VERSION "1.11.2"

NS_ :

BS_:

BU_: TCU BRK ESP MCU RDD GP TMS GW KPD1 RDE FNR ECU KPD2 ATSGO ACU IMU1 IMU2 IMU3 IMU4 IMU5 AGW PMI HDOQS EGOQS OBC EEC CBSW EJRH EJLH EPDLT EPDL2 EPDLR EPDLA TRBDZ ECU1 CLST LC510 EGDL JS SMB KPAC ACCU Audio TGU RDRR RDLH RDRH AVM CHMSL CTC SMK EVC MCU2 PHM MC3D AMBLMP RCTGU RDU PT3D XCU can1 can2

BO_ 2566866721 MCU_SIG3: 8 MCU
 SG_ DifActlTrgGrdt : 63|1@1+ (1,0) [0|1] "" Vector__XXX
 SG_ OprPrsntSt : 62|1@1+ (1,0) [0|1] "" Vector__XXX
 SG_ HydCutOffRls : 61|1@1+ (1,0) [0|1] "" Vector__XXX
 SG_ ChgErr : 60|1@1+ (1,0) [0|1] "" Vector__XXX
 SG_ ChgSt : 58|2@1+ (1,0) [0|3] "" Vector__XXX
 SG_ WrkTrv : 56|2@1+ (1,0) [0|3] "" Vector__XXX
 SG_ BatLw : 55|1@1+ (1,0) [0|1] "" Vector__XXX
 SG_ HydLck : 54|1@1+ (1,0) [0|1] "" Vector__XXX
 SG_ PopCmdHillDscntCtrl : 53|1@1+ (5,0) [0|1250] "" Vector__XXX
 SG_ HillDscntCtrlSt : 52|1@1+ (1,0) [0|1] "" Vector__XXX
 SG_ OprPrsnc : 51|1@1+ (1,0) [0|1] "" Vector__XXX
 SG_ BckDust : 50|1@1+ (1,0) [0|1] "" Vector__XXX
 SG_ BmsPrhtLmp : 48|2@1+ (1,0) [0|3] "" Vector__XXX
 SG_ DacSt : 45|3@1+ (1,0) [0|7] "" Vector__XXX
 SG_ EmcvFngrtpLvrErr : 44|1@1+ (1,0) [0|1] "" Vector__XXX
 SG_ PopCmdFnrNtrl : 42|2@1+ (1,0) [0|3] "" Vector__XXX
 SG_ IllminSt : 40|2@1+ (1,0) [0|3] "" Vector__XXX
 SG_ ChmslSt : 36|4@1+ (1,0) [0|15] "" Vector__XXX
 SG_ CdsFanRvsSt : 35|1@1+ (1,0) [0|1] "" Vector__XXX
 SG_ CacFanRvsSt : 34|1@1+ (1,0) [0|1] "" Vector__XXX
 SG_ CurMaxSpdMinor : 32|2@1+ (1,0) [0|3] "" Vector__XXX
 SG_ WhlTypeStrMd : 30|2@1+ (1,0) [0|3] "" Vector__XXX
 SG_ WrnGndSlop : 29|1@1+ (1,0) [0|1] "" Vector__XXX
 SG_ WrnOilTmpLw : 28|1@1+ (1,0) [0|1] "" Vector__XXX
 SG_ WghConfirmWarnMsg : 24|4@1+ (1,0) [0|15] "" Vector__XXX
 SG_ AttOpr : 23|1@1+ (1,0) [0|1] "" Vector__XXX
 SG_ QckCoolSt : 21|2@1+ (1,0) [0|3] "" Vector__XXX
 SG_ PopCmdBckAstTargetSet : 20|1@1+ (1,0) [0|1] "" Vector__XXX
 SG_ WrnLimpHome : 19|1@1+ (1,0) [0|1] "" Vector__XXX
 SG_ DozAstStopReq : 18|1@1+ (1,0) [0|1] "" Vector__XXX
 SG_ MchCond : 16|2@1+ (1,0) [0|3] "" Vector__XXX
 SG_ WrnRollOvr : 14|2@1+ (1,0) [0|3] "" Vector__XXX
 SG_ WrnArmPosOnDrv : 13|1@1+ (1,0) [0|1] "" Vector__XXX
 SG_ WrnThwStrShft : 12|1@1+ (1,0) [0|1] "" Vector__XXX
 SG_ WrnRamLck : 10|2@1+ (1,0) [0|3] "" Vector__XXX
 SG_ WrnHstOilFilt : 9|1@1+ (1,0) [0|1] "" Vector__XXX
 SG_ WrnGrBoxOvTmp : 8|1@1+ (1,0) [0|1] "" Vector__XXX
 SG_ VhcStTractionLv : 6|2@1+ (1,0) [0|3] "" Vector__XXX
 SG_ WhlLis : 4|2@1+ (1,0) [0|3] "" Vector__XXX
 SG_ WhlDzTrlHitch : 3|1@1+ (1,0) [0|1] "" Vector__XXX
 SG_ WhlSwgAlign : 2|1@1+ (1,0) [0|1] "" Vector__XXX
 SG_ WhlRamLckAuto : 0|2@1+ (1,0) [0|3] "" Vector__XXX

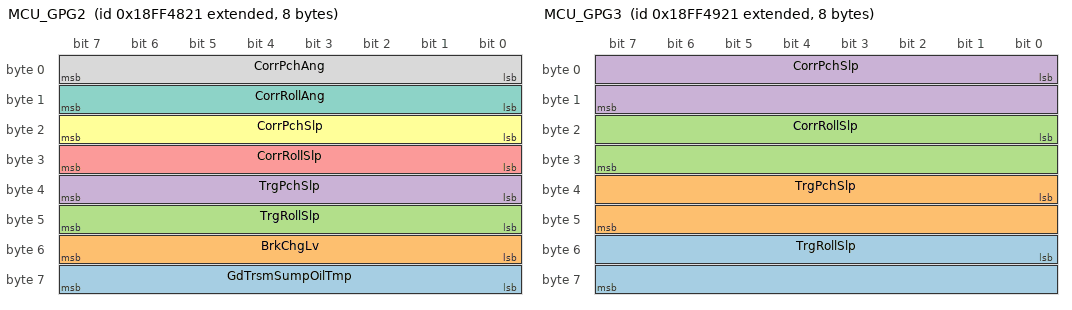
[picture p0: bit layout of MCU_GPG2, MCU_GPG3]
BO_ 2566866977 MCU_GPG2: 8 MCU
 SG_ GdTrsmSumpOilTmp : 56|8@1+ (1,0) [0|250] "percent" Vector__XXX
 SG_ BrkChgLv : 48|8@1+ (1,0) [0|250] "percent" Vector__XXX
 SG_ TrgRollSlp : 40|8@1- (1,-125) [-125|125] "percent" Vector__XXX
 SG_ TrgPchSlp : 32|8@1- (1,-125) [-125|125] "percent" Vector__XXX
 SG_ CorrRollSlp : 24|8@1- (1,-125) [-125|125] "percent" Vector__XXX
 SG_ CorrPchSlp : 16|8@1- (1,-125) [-125|125] "percent" Vector__XXX
 SG_ CorrRollAng : 8|8@1- (0.5,-65) [-65|60] "deg" Vector__XXX
 SG_ CorrPchAng : 0|8@1- (0.5,-65) [-65|60] "deg" Vector__XXX

BO_ 2566867233 MCU_GPG3: 8 MCU
 SG_ TrgRollSlp : 48|16@1- (0.01,-321.27) [-321.27|321.28] "percent" Vector__XXX
 SG_ TrgPchSlp : 32|16@1- (0.01,-321.27) [-321.27|321.28] "percent" Vector__XXX
 SG_ CorrRollSlp : 16|16@1- (0.01,-321.27) [-321.27|321.28] "percent" Vector__XXX
 SG_ CorrPchSlp : 0|16@1- (0.01,-321.27) [-321.27|321.28] "percent" Vector__XXX

BO_ 2566867489 MCU_SIG4: 8 MCU
 SG_ WarnPopLimitangexcess : 62|2@1+ (1,0) [0|3] "" Vector__XXX
 SG_ WarnPopMgMcSsErr : 58|4@1+ (1,0) [0|15] "" Vector__XXX
 SG_ McTemporaryRlsPop : 56|2@1+ (1,0) [0|3] "" Vector__XXX
 SG_ VhcStStickStr : 54|2@1+ (1,0) [0|3] "" Vector__XXX
 SG_ VhcStFineSwg : 52|2@1+ (1,0) [0|3] "" Vector__XXX
 SG_ ActTrvlSpdforCrwl : 50|2@1+ (1,0) [0|3] "" Vector__XXX
 SG_ ActTrvlStforCrwl : 48|2@1+ (1,0) [0|3] "" Vector__XXX
 SG_ VhcStParallelLift : 46|2@1+ (1,0) [0|3] "" Vector__XXX
 SG_ VhcStFrSspnAuto : 44|2@1+ (1,0) [0|3] "" Vector__XXX
 SG_ RmCrakingSt : 40|4@1+ (1,0) [0|15] "" Vector__XXX
 SG_ IndTrmsColdStart : 39|1@1+ (1,0) [0|1] "" Vector__XXX
 SG_ VhcStElevatingCabin : 37|2@1+ (1,0) [0|3] "" Vector__XXX
 SG_ WarnPopStickStr : 36|1@1+ (1,0) [0|1] "" Vector__XXX
 SG_ PopCmdThwLvrErr : 35|1@1+ (1,0) [0|1] "" Vector__XXX
 SG_ HpApMd : 33|2@1+ (1,0) [0|3] "" Vector__XXX
 SG_ GrLmt : 32|1@1+ (1,0) [0|1] "" Vector__XXX
 SG_ BodyAng : 24|8@1+ (1,-125) [-125|125] "deg" Vector__XXX
 SG_ WghIndSt : 22|2@1+ (1,0) [0|3] "" Vector__XXX
 SG_ BrkHold : 21|1@1+ (1,0) [0|1] "" Vector__XXX
 SG_ RtrdSt : 18|3@1+ (1,0) [0|7] "" Vector__XXX
 SG_ PilotCutOffSt : 16|2@1+ (1,0) [0|3] "" Vector__XXX
 SG_ BodySt : 14|2@1+ (1,0) [0|3] "" Vector__XXX
 SG_ VhcStGndSaw : 13|1@1+ (1,0) [0|1] "" Vector__XXX
 SG_ PopCmdJoyLvrNtrlErr : 12|1@1+ (1,0) [0|1] "" Vector__XXX
 SG_ VhcStIntAxleLck : 11|1@1+ (1,0) [0|1] "" Vector__XXX
 SG_ TrlHhFlowMd : 8|3@1+ (1,0) [0|7] "" Vector__XXX
 SG_ ExcAutoBrkAntiFire : 6|2@1+ (1,0) [0|3] "" Vector__XXX
 SG_ TrlIntLckOvrd : 5|1@1+ (1,0) [0|1] "" Vector__XXX
 SG_ TrlCtrlFlow : 3|2@1+ (1,0) [0|3] "" Vector__XXX
 SG_ TrlSelfLv : 1|2@1+ (1,0) [0|3] "" Vector__XXX
 SG_ TrlHhFlow : 0|1@1+ (1,0) [0|1] "" Vector__XXX

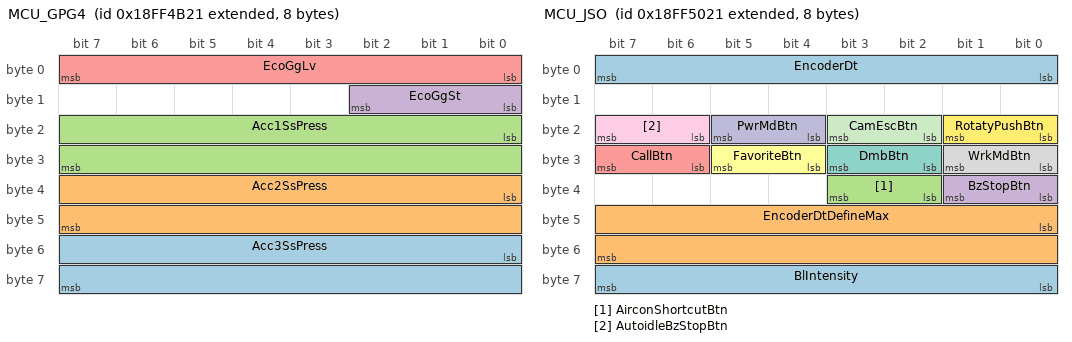
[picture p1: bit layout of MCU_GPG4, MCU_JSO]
BO_ 2566867745 MCU_GPG4: 8 MCU
 SG_ Acc3SsPress : 48|16@1+ (1,0) [0|65535] "bar" Vector__XXX
 SG_ Acc2SsPress : 32|16@1+ (1,0) [0|65535] "bar" Vector__XXX
 SG_ Acc1SsPress : 16|16@1+ (1,0) [0|65535] "bar" Vector__XXX
 SG_ EcoGgSt : 8|3@1+ (1,0) [0|7] "" Vector__XXX
 SG_ EcoGgLv : 0|8@1+ (1,0) [0|250] "percent" Vector__XXX

BO_ 2566868257 MCU_METPSC: 250 MCU
 SG_ MaximumEgSpd : 40|16@1+ (0.125,0) [0|8031.875] "Rpm" Vector__XXX
 SG_ AutoCalbMd : 35|1@1+ (1,0) [0|1] "" Vector__XXX
 SG_ CalbReq : 34|1@1+ (1,0) [0|1] "" Vector__XXX
 SG_ VhcStTpsCalb : 32|2@1+ (1,0) [0|3] "" Vector__XXX
 SG_ MinimumEgSpd : 8|16@1+ (0.125,0) [0|8031.875] "rpm" Vector__XXX
 SG_ VhcStSsNrm : 3|1@1+ (1,0) [0|1] "" Vector__XXX
 SG_ VhcStEgIgn : 2|1@1+ (1,0) [0|1] "" Vector__XXX
 SG_ VhcStPilotCutOff : 1|1@1+ (1,0) [0|1] "" Vector__XXX
 SG_ VhcStEgCtrlDialMax : 0|1@1+ (1,0) [0|1] "" Vector__XXX

BO_ 2566868921 EGDL_EDO: 8 EGDL
 SG_ DialStep : 8|4@1+ (1,0) [0|15] "" Vector__XXX
 SG_ DialPos : 0|8@1+ (0.02044,0) [0|5.11] "V" Vector__XXX

BO_ 2566869025 MCU_JSO: 8 MCU
 SG_ BlIntensity : 56|8@1+ (1,0) [0|255] "" Vector__XXX
 SG_ EncoderDtDefineMax : 40|16@1+ (16,0) [0|0] "" Vector__XXX
 SG_ AirconShortcutBtn : 34|2@1+ (1,0) [0|3] "" Vector__XXX
 SG_ BzStopBtn : 32|2@1+ (1,0) [0|3] "" Vector__XXX
 SG_ CallBtn : 30|2@1+ (1,0) [0|3] "" Vector__XXX
 SG_ FavoriteBtn : 28|2@1+ (1,0) [0|3] "" Vector__XXX
 SG_ DmbBtn : 26|2@1+ (1,0) [0|3] "" Vector__XXX
 SG_ WrkMdBtn : 24|2@1+ (1,0) [0|3] "" Vector__XXX
 SG_ AutoidleBzStopBtn : 22|2@1+ (1,0) [0|3] "" Vector__XXX
 SG_ PwrMdBtn : 20|2@1+ (1,0) [0|3] "" Vector__XXX
 SG_ CamEscBtn : 18|2@1+ (1,0) [0|3] "" Vector__XXX
 SG_ RotatyPushBtn : 16|2@1+ (1,0) [0|3] "" Vector__XXX
 SG_ EncoderDt : 0|8@1+ (1,0) [0|255] "" Vector__XXX

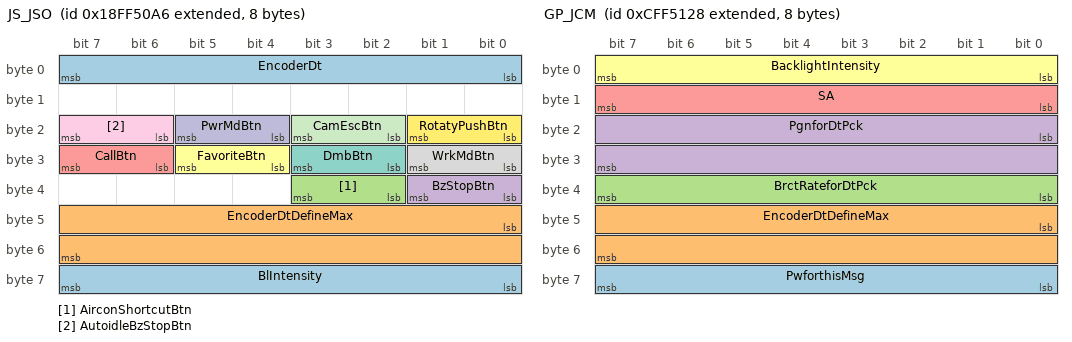
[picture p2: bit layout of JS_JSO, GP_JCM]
BO_ 2566869158 JS_JSO: 8 JS
 SG_ BlIntensity : 56|8@1+ (1,0) [0|255] "" Vector__XXX
 SG_ EncoderDtDefineMax : 40|16@1+ (16,0) [0|0] "" Vector__XXX
 SG_ AirconShortcutBtn : 34|2@1+ (1,0) [0|3] "" Vector__XXX
 SG_ BzStopBtn : 32|2@1+ (1,0) [0|3] "" Vector__XXX
 SG_ CallBtn : 30|2@1+ (1,0) [0|3] "" Vector__XXX
 SG_ FavoriteBtn : 28|2@1+ (1,0) [0|3] "" Vector__XXX
 SG_ DmbBtn : 26|2@1+ (1,0) [0|3] "" Vector__XXX
 SG_ WrkMdBtn : 24|2@1+ (1,0) [0|3] "" Vector__XXX
 SG_ AutoidleBzStopBtn : 22|2@1+ (1,0) [0|3] "" Vector__XXX
 SG_ PwrMdBtn : 20|2@1+ (1,0) [0|3] "" Vector__XXX
 SG_ CamEscBtn : 18|2@1+ (1,0) [0|3] "" Vector__XXX
 SG_ RotatyPushBtn : 16|2@1+ (1,0) [0|3] "" Vector__XXX
 SG_ EncoderDt : 0|8@1+ (1,0) [0|255] "" Vector__XXX

BO_ 2365542696 GP_JCM: 8 GP
 SG_ PwforthisMsg : 56|8@1+ (1,0) [0|254] "" Vector__XXX
 SG_ EncoderDtDefineMax : 40|16@1+ (1,0) [0|65534] "" Vector__XXX
 SG_ BrctRateforDtPck : 32|8@1+ (1,0) [0|254] "" Vector__XXX
 SG_ PgnforDtPck : 16|16@1+ (1,0) [0|65534] "" Vector__XXX
 SG_ SA : 8|8@1+ (1,0) [0|254] "" Vector__XXX
 SG_ BacklightIntensity : 0|8@1+ (1,0) [0|254] "" Vector__XXX

BO_ 2365542917 FNR_ZFTC1: 8 FNR

BO_ 2365543201 MCU_KEYPADBI: 8 MCU
 SG_ RvsFanLInd : 62|2@1+ (1,0) [0|3] "" Vector__XXX
 SG_ RvsFanRInd : 60|2@1+ (1,0) [0|3] "" Vector__XXX
 SG_ BoomLmpOprLInd : 58|2@1+ (1,0) [0|3] "" Vector__XXX
 SG_ BoomLmpOprCtrInd : 56|2@1+ (1,0) [0|3] "" Vector__XXX
 SG_ BoomLmpOprRInd : 54|2@1+ (1,0) [0|3] "" Vector__XXX
 SG_ InfoLInd : 52|2@1+ (1,0) [0|3] "" Vector__XXX
 SG_ InfoCtrInd : 50|2@1+ (1,0) [0|3] "" Vector__XXX
 SG_ InfoRInd : 48|2@1+ (1,0) [0|3] "" Vector__XXX
 SG_ EmgStrLInd : 46|2@1+ (1,0) [0|3] "" Vector__XXX
 SG_ EmgStrCtrInd : 44|2@1+ (1,0) [0|3] "" Vector__XXX
 SG_ EmgStrRInd : 42|2@1+ (1,0) [0|3] "" Vector__XXX
 SG_ LoadIsolationLInd : 40|2@1+ (1,0) [0|3] "" Vector__XXX
 SG_ LoadIsolationCtrInd : 38|2@1+ (1,0) [0|3] "" Vector__XXX
 SG_ LoadIsolationRInd : 36|2@1+ (1,0) [0|3] "" Vector__XXX
 SG_ MirrorHtLInd : 34|2@1+ (1,0) [0|3] "" Vector__XXX
 SG_ MirrorHtCtrInd : 32|2@1+ (1,0) [0|3] "" Vector__XXX
 SG_ MirrorHtRInd : 30|2@1+ (1,0) [0|3] "" Vector__XXX
 SG_ RrWpWashLInd : 28|2@1+ (1,0) [0|3] "" Vector__XXX
 SG_ RrWpWashCtrInd : 26|2@1+ (1,0) [0|3] "" Vector__XXX
 SG_ RrWpWashRInd : 24|2@1+ (1,0) [0|3] "" Vector__XXX
 SG_ BeaconLInd : 22|2@1+ (1,0) [0|3] "" Vector__XXX
 SG_ BeaconCtrInd : 20|2@1+ (1,0) [0|3] "" Vector__XXX
 SG_ BeaconRInd : 18|2@1+ (1,0) [0|3] "" Vector__XXX
 SG_ RrWrkLmpLInd : 16|2@1+ (1,0) [0|3] "" Vector__XXX
 SG_ RrWrkLmpCtrInd : 14|2@1+ (1,0) [0|3] "" Vector__XXX
 SG_ RrWrkLmpRInd : 12|2@1+ (1,0) [0|3] "" Vector__XXX
 SG_ FrWrkLmpLInd : 10|2@1+ (1,0) [0|3] "" Vector__XXX
 SG_ FrWrkLmpCentorInd : 8|2@1+ (1,0) [0|3] "" Vector__XXX
 SG_ FrWrkLmpRInd : 6|2@1+ (1,0) [0|3] "" Vector__XXX
 SG_ HeadLmpLInd : 4|2@1+ (1,0) [0|3] "" Vector__XXX
 SG_ HeadLmpCtrInd : 2|2@1+ (1,0) [0|3] "" Vector__XXX
 SG_ HeadLmpRInd : 0|2@1+ (1,0) [0|3] "" Vector__XXX

BO_ 2365543504 KPD1_KEYPADS: 8 KPD1
 SG_ TrkExpansionSig : 63|1@1+ (1,0) [0|1] "" Vector__XXX
 SG_ InterlockOverrideSig : 62|1@1+ (1,0) [0|1] "" Vector__XXX
 SG_ Aux8OprSig : 61|1@1+ (1,0) [0|1] "" Vector__XXX
 SG_ Aux7OprSig : 60|1@1+ (1,0) [0|1] "" Vector__XXX
 SG_ ContinuousFlowSig : 59|1@1+ (1,0) [0|1] "" Vector__XXX
 SG_ RvsFanOprSig : 58|1@1+ (1,0) [0|1] "" Vector__XXX
 SG_ SelfLevelSig : 57|1@1+ (1,0) [0|1] "" Vector__XXX
 SG_ BoomLis : 56|1@1+ (1,0) [0|1] "" Vector__XXX
 SG_ UpSig : 55|1@1+ (1,0) [0|1] "" Vector__XXX
 SG_ DnSig : 54|1@1+ (1,0) [0|1] "" Vector__XXX
 SG_ EnterSig : 53|1@1+ (1,0) [0|1] "" Vector__XXX
 SG_ MenuSig : 52|1@1+ (1,0) [0|1] "" Vector__XXX
 SG_ BzStopSig : 51|1@1+ (1,0) [0|1] "" Vector__XXX
 SG_ DmbEntertainSig : 50|1@1+ (1,0) [0|1] "" Vector__XXX
 SG_ CallSig : 49|1@1+ (1,0) [0|1] "" Vector__XXX
 SG_ RrMirrorHtSig : 48|1@1+ (1,0) [0|1] "" Vector__XXX
 SG_ FrWpOprSig : 47|1@1+ (1,0) [0|1] "" Vector__XXX
 SG_ RrWpOprSig : 46|1@1+ (1,0) [0|1] "" Vector__XXX
 SG_ SideWpOprSig : 45|1@1+ (1,0) [0|1] "" Vector__XXX
 SG_ FrWpWashOprSig : 44|1@1+ (1,0) [0|1] "" Vector__XXX
 SG_ SideWpWashOprSig : 43|1@1+ (1,0) [0|1] "" Vector__XXX
 SG_ AirCompOprSig : 42|1@1+ (1,0) [0|1] "" Vector__XXX
 SG_ TrvlSpdOprSig : 41|1@1+ (1,0) [0|1] "" Vector__XXX
 SG_ AutoidleSig : 40|1@1+ (1,0) [0|1] "" Vector__XXX
 SG_ CrabRoundSelSig : 39|1@1+ (1,0) [0|1] "" Vector__XXX
 SG_ TwoWhlFourWhlSelSig : 38|1@1+ (1,0) [0|1] "" Vector__XXX
 SG_ ThrottleLckUpOprSig : 37|1@1+ (1,0) [0|1] "" Vector__XXX
 SG_ TractionCtrlMdOprSig : 36|1@1+ (1,0) [0|1] "" Vector__XXX
 SG_ VariableSpdDnOprSig : 35|1@1+ (1,0) [0|1] "" Vector__XXX
 SG_ VariableSpdUpOprSig : 34|1@1+ (1,0) [0|1] "" Vector__XXX
 SG_ MaxSpdUpOprSig : 33|1@1+ (1,0) [0|1] "" Vector__XXX
 SG_ MaxSpdDnOprSig : 32|1@1+ (1,0) [0|1] "" Vector__XXX
 SG_ TrqCvtLckUpOprSig : 31|1@1+ (1,0) [0|1] "" Vector__XXX
 SG_ ClutchCutOffOprSig : 30|1@1+ (1,0) [0|1] "" Vector__XXX
 SG_ TrmsMdSelOprSig : 29|1@1+ (1,0) [0|1] "" Vector__XXX
 SG_ ShakeControlSig : 28|1@1+ (1,0) [0|1] "" Vector__XXX
 SG_ OutriggerAllSig : 27|1@1+ (1,0) [0|1] "" Vector__XXX
 SG_ OutriggerRrRSig : 26|1@1+ (1,0) [0|1] "" Vector__XXX
 SG_ OutriggerRrLSig : 25|1@1+ (1,0) [0|1] "" Vector__XXX
 SG_ OutriggerFrRSig : 24|1@1+ (1,0) [0|1] "" Vector__XXX
 SG_ OutriggerFrLSig : 23|1@1+ (1,0) [0|1] "" Vector__XXX
 SG_ DifLockEngagedOprSig : 22|1@1+ (1,0) [0|1] "" Vector__XXX
 SG_ EmgStrOprSig : 21|1@1+ (1,0) [0|1] "" Vector__XXX
 SG_ BckDetentOprSig : 20|1@1+ (1,0) [0|1] "" Vector__XXX
 SG_ BoomDetentOprSig : 19|1@1+ (1,0) [0|1] "" Vector__XXX
 SG_ LoadIsolationOprSig : 18|1@1+ (1,0) [0|1] "" Vector__XXX
 SG_ MdSelOprSig : 17|1@1+ (1,0) [0|1] "" Vector__XXX
 SG_ MenuHelpOprSig : 16|1@1+ (1,0) [0|1] "" Vector__XXX
 SG_ JoyStrSig : 15|1@1+ (1,0) [0|1] "" Vector__XXX
 SG_ FineSwgSig : 14|1@1+ (1,0) [0|1] "" Vector__XXX
 SG_ TrailerHitchSig : 13|1@1+ (1,0) [0|1] "" Vector__XXX
 SG_ AutoDigBrkSig : 12|1@1+ (1,0) [0|1] "" Vector__XXX
 SG_ BoomSwgSig : 11|1@1+ (1,0) [0|1] "" Vector__XXX
 SG_ WorkMdSig : 10|1@1+ (1,0) [0|1] "" Vector__XXX
 SG_ PwrMdSig : 9|1@1+ (1,0) [0|1] "" Vector__XXX
 SG_ TrvlAlmSig : 8|1@1+ (1,0) [0|1] "" Vector__XXX
 SG_ MirrorHtOprSig : 7|1@1+ (1,0) [0|1] "" Vector__XXX
 SG_ RrWpWashOprSig : 6|1@1+ (1,0) [0|1] "" Vector__XXX
 SG_ OwdOprSig : 5|1@1+ (1,0) [0|1] "" Vector__XXX
 SG_ BoomLmpOprSig : 4|1@1+ (1,0) [0|1] "" Vector__XXX
 SG_ BeaconLmpOprSig : 3|1@1+ (1,0) [0|1] "" Vector__XXX
 SG_ RrWrkLmpOprSig : 2|1@1+ (1,0) [0|1] "" Vector__XXX
 SG_ FrWrkLmpOprSig : 1|1@1+ (1,0) [0|1] "" Vector__XXX
 SG_ HeadLmpOprSig : 0|1@1+ (1,0) [0|1] "" Vector__XXX

BO_ 2365543713 MCU_KEYPADI1: 8 MCU
 SG_ SelfLvLInd : 58|2@1+ (1,0) [0|3] "" Vector__XXX
 SG_ SelfLvCtrInd : 56|2@1+ (1,0) [0|3] "" Vector__XXX
 SG_ SelfLvRInd : 54|2@1+ (1,0) [0|3] "" Vector__XXX
 SG_ TrqCvtLckUpLInd : 52|2@1+ (1,0) [0|3] "" Vector__XXX
 SG_ TrqCvtLckUpCtrInd : 50|2@1+ (1,0) [0|3] "" Vector__XXX
 SG_ TrqCvtLckUpRInd : 48|2@1+ (1,0) [0|3] "" Vector__XXX
 SG_ ClutchCutOffLInd : 46|2@1+ (1,0) [0|3] "" Vector__XXX
 SG_ ClutchCutOffCtrInd : 44|2@1+ (1,0) [0|3] "" Vector__XXX
 SG_ ClutchCutOffRInd : 42|2@1+ (1,0) [0|3] "" Vector__XXX
 SG_ TrmsMdSelLInd : 40|2@1+ (1,0) [0|3] "" Vector__XXX
 SG_ TrmsMdSelCtrInd : 38|2@1+ (1,0) [0|3] "" Vector__XXX
 SG_ TrmsMdSelRInd : 36|2@1+ (1,0) [0|3] "" Vector__XXX
 SG_ MaxSpdDnLInd : 34|2@1+ (1,0) [0|3] "" Vector__XXX
 SG_ MaxSpdDnCtrInd : 32|2@1+ (1,0) [0|3] "" Vector__XXX
 SG_ MaxSpdDnRInd : 30|2@1+ (1,0) [0|3] "" Vector__XXX
 SG_ MaxSpdUpLInd : 28|2@1+ (1,0) [0|3] "" Vector__XXX
 SG_ MaxSpdUpCtrInd : 26|2@1+ (1,0) [0|3] "" Vector__XXX
 SG_ MaxSpdUpRInd : 24|2@1+ (1,0) [0|3] "" Vector__XXX
 SG_ BckDetentLInd : 22|2@1+ (1,0) [0|3] "" Vector__XXX
 SG_ BckDetentCtrInd : 20|2@1+ (1,0) [0|3] "" Vector__XXX
 SG_ BckDetentRInd : 18|2@1+ (1,0) [0|3] "" Vector__XXX
 SG_ BoomDetentLInd : 16|2@1+ (1,0) [0|3] "" Vector__XXX
 SG_ BoomDetentCtrInd : 14|2@1+ (1,0) [0|3] "" Vector__XXX
 SG_ BoomDetentRInd : 12|2@1+ (1,0) [0|3] "" Vector__XXX
 SG_ DifLckEngagedLInd : 10|2@1+ (1,0) [0|3] "" Vector__XXX
 SG_ DifLckEngagedCtrInd : 8|2@1+ (1,0) [0|3] "" Vector__XXX
 SG_ DifLckEngagedRInd : 6|2@1+ (1,0) [0|3] "" Vector__XXX
 SG_ MdSelLInd : 4|2@1+ (1,0) [0|3] "" Vector__XXX
 SG_ MdSelCtrInd : 2|2@1+ (1,0) [0|3] "" Vector__XXX
 SG_ MdSelRInd : 0|2@1+ (1,0) [0|3] "" Vector__XXX

BO_ 2365543969 MCU_KEYPADMI1: 8 MCU
 SG_ HyhLckCtrInd : 60|2@1+ (1,0) [0|3] "" Vector__XXX
 SG_ AutoidleLInd : 58|2@1+ (1,0) [0|3] "" Vector__XXX
 SG_ AutoidleCtrInd : 56|2@1+ (1,0) [0|3] "" Vector__XXX
 SG_ AutoidleRInd : 54|2@1+ (1,0) [0|3] "" Vector__XXX
 SG_ JoyStrLInd : 52|2@1+ (1,0) [0|3] "" Vector__XXX
 SG_ JoyStrCtrInd : 50|2@1+ (1,0) [0|3] "" Vector__XXX
 SG_ JoyStrRInd : 48|2@1+ (1,0) [0|3] "" Vector__XXX
 SG_ FineSwgLInd : 46|2@1+ (1,0) [0|3] "" Vector__XXX
 SG_ FineSwgCtrInd : 44|2@1+ (1,0) [0|3] "" Vector__XXX
 SG_ FineSwgRInd : 42|2@1+ (1,0) [0|3] "" Vector__XXX
 SG_ TrailerHitchBrkLInd : 40|2@1+ (1,0) [0|3] "" Vector__XXX
 SG_ TrailerHitchBrkCtrInd : 38|2@1+ (1,0) [0|3] "" Vector__XXX
 SG_ TrailerHitchRInd : 36|2@1+ (1,0) [0|3] "" Vector__XXX
 SG_ AutoDigBrkLInd : 34|2@1+ (1,0) [0|3] "" Vector__XXX
 SG_ AutoDigBrkCtrInd : 32|2@1+ (1,0) [0|3] "" Vector__XXX
 SG_ AutoDigBrkRInd : 30|2@1+ (1,0) [0|3] "" Vector__XXX
 SG_ BoomSwgMdLInd : 28|2@1+ (1,0) [0|3] "" Vector__XXX
 SG_ BoomSwgMdCtrInd : 26|2@1+ (1,0) [0|3] "" Vector__XXX
 SG_ BoomSwgMdRInd : 24|2@1+ (1,0) [0|3] "" Vector__XXX
 SG_ WrkMdLInd : 22|2@1+ (1,0) [0|3] "" Vector__XXX
 SG_ WrkMdCtrInd : 20|2@1+ (1,0) [0|3] "" Vector__XXX
 SG_ WrkMdRInd : 18|2@1+ (1,0) [0|3] "" Vector__XXX
 SG_ PwrMdLInd : 16|2@1+ (1,0) [0|3] "" Vector__XXX
 SG_ PwrMdCtrInd : 14|2@1+ (1,0) [0|3] "" Vector__XXX
 SG_ PwrMdRInd : 12|2@1+ (1,0) [0|3] "" Vector__XXX
 SG_ TrvlAlmLInd : 10|2@1+ (1,0) [0|3] "" Vector__XXX
 SG_ TrvlAlmCtrInd : 8|2@1+ (1,0) [0|3] "" Vector__XXX
 SG_ TrvlAlmRInd : 6|2@1+ (1,0) [0|3] "" Vector__XXX
 SG_ OwdLInd : 4|2@1+ (1,0) [0|3] "" Vector__XXX
 SG_ OwdCtrInd : 2|2@1+ (1,0) [0|3] "" Vector__XXX
 SG_ OwdRInd : 0|2@1+ (1,0) [0|3] "" Vector__XXX

BO_ 2365544225 MCU_KEYPADMI2: 8 MCU
 SG_ SwgLckLInd : 58|2@1+ (1,0) [0|3] "" Vector__XXX
 SG_ SwgLckCtrInd : 56|2@1+ (1,0) [0|3] "" Vector__XXX
 SG_ SwgLckRInd : 54|2@1+ (1,0) [0|3] "" Vector__XXX
 SG_ BoomFltLInd : 52|2@1+ (1,0) [0|3] "" Vector__XXX
 SG_ BoomFltCtrInd : 50|2@1+ (1,0) [0|3] "" Vector__XXX
 SG_ BoomFltRInd : 48|2@1+ (1,0) [0|3] "" Vector__XXX
 SG_ BoomLisLInd : 46|2@1+ (1,0) [0|3] "" Vector__XXX
 SG_ BoomLisCtrInd : 44|2@1+ (1,0) [0|3] "" Vector__XXX
 SG_ BoomLisRInd : 42|2@1+ (1,0) [0|3] "" Vector__XXX
 SG_ CrabRoundSelLInd : 40|2@1+ (1,0) [0|3] "" Vector__XXX
 SG_ CrabRoundSelCtrInd : 38|2@1+ (1,0) [0|3] "" Vector__XXX
 SG_ CrabRoundSelRInd : 36|2@1+ (1,0) [0|3] "" Vector__XXX
 SG_ TwoWhlFourWhlSelLInd : 34|2@1+ (1,0) [0|3] "" Vector__XXX
 SG_ TwoWhlFourWhlSelCtrInd : 32|2@1+ (1,0) [0|3] "" Vector__XXX
 SG_ TwoWhlFourWhlSelRInd : 30|2@1+ (1,0) [0|3] "" Vector__XXX
 SG_ OtrgAllLInd : 28|2@1+ (1,0) [0|3] "" Vector__XXX
 SG_ OtrgAllCtrInd : 26|2@1+ (1,0) [0|3] "" Vector__XXX
 SG_ OtrgAllRInd : 24|2@1+ (1,0) [0|3] "" Vector__XXX
 SG_ OtrgRrRLInd : 22|2@1+ (1,0) [0|3] "" Vector__XXX
 SG_ OtrgRrRCtrInd : 20|2@1+ (1,0) [0|3] "" Vector__XXX
 SG_ OtrgRrRRInd : 18|2@1+ (1,0) [0|3] "" Vector__XXX
 SG_ OtrgRrLLInd : 16|2@1+ (1,0) [0|3] "" Vector__XXX
 SG_ OtrgRrLCtrInd : 14|2@1+ (1,0) [0|3] "" Vector__XXX
 SG_ OtrgRrLRInd : 12|2@1+ (1,0) [0|3] "" Vector__XXX
 SG_ OtrgFrRLInd : 10|2@1+ (1,0) [0|3] "" Vector__XXX
 SG_ OtrgFrRCtrInd : 8|2@1+ (1,0) [0|3] "" Vector__XXX
 SG_ OtrgFrRRInd : 6|2@1+ (1,0) [0|3] "" Vector__XXX
 SG_ OtrgFrLLInd : 4|2@1+ (1,0) [0|3] "" Vector__XXX
 SG_ OtrgFrLCtrInd : 2|2@1+ (1,0) [0|3] "" Vector__XXX
 SG_ OtrgFrLRInd : 0|2@1+ (1,0) [0|3] "" Vector__XXX

BO_ 2365544481 MCU_KEYPADI2: 8 MCU
 SG_ Aux8LInd : 52|2@1+ (1,0) [0|3] "" Vector__XXX
 SG_ Aux8CtrInd : 50|2@1+ (1,0) [0|3] "" Vector__XXX
 SG_ Aux8RInd : 48|2@1+ (1,0) [0|3] "" Vector__XXX
 SG_ Aux7LInd : 46|2@1+ (1,0) [0|3] "" Vector__XXX
 SG_ Aux7CtrInd : 44|2@1+ (1,0) [0|3] "" Vector__XXX
 SG_ Aux7RInd : 42|2@1+ (1,0) [0|3] "" Vector__XXX
 SG_ ContinuousFlowLInd : 40|2@1+ (1,0) [0|3] "" Vector__XXX
 SG_ ContinuousFlowCtrInd : 38|2@1+ (1,0) [0|3] "" Vector__XXX
 SG_ ContinuousFlowRInd : 36|2@1+ (1,0) [0|3] "" Vector__XXX
 SG_ InterlockOverrideLInd : 34|2@1+ (1,0) [0|3] "" Vector__XXX
 SG_ InterlockOverrideCtrInd : 32|2@1+ (1,0) [0|3] "" Vector__XXX
 SG_ InterlockOverrideRInd : 30|2@1+ (1,0) [0|3] "" Vector__XXX
 SG_ ShakeCtrlLInd : 28|2@1+ (1,0) [0|3] "" Vector__XXX
 SG_ ShakeCtrlCtrInd : 26|2@1+ (1,0) [0|3] "" Vector__XXX
 SG_ ShakeCtrlRInd : 24|2@1+ (1,0) [0|3] "" Vector__XXX
 SG_ ThrottleLckUpLInd : 22|2@1+ (1,0) [0|3] "" Vector__XXX
 SG_ ThrottleLckUpCtrInd : 20|2@1+ (1,0) [0|3] "" Vector__XXX
 SG_ ThrottleLckUpRInd : 18|2@1+ (1,0) [0|3] "" Vector__XXX
 SG_ TractionCtrlMdLInd : 16|2@1+ (1,0) [0|3] "" Vector__XXX
 SG_ TractionCtrlMdCtrInd : 14|2@1+ (1,0) [0|3] "" Vector__XXX
 SG_ TractionCtrlMdRInd : 12|2@1+ (1,0) [0|3] "" Vector__XXX
 SG_ VariableSpdDnLInd : 10|2@1+ (1,0) [0|3] "" Vector__XXX
 SG_ VariableSpdDnCtrInd : 8|2@1+ (1,0) [0|3] "" Vector__XXX
 SG_ VariableSpdDnRInd : 6|2@1+ (1,0) [0|3] "" Vector__XXX
 SG_ VariableSpdUpLInd : 4|2@1+ (1,0) [0|3] "" Vector__XXX
 SG_ VariableSpdUpCtrInd : 2|2@1+ (1,0) [0|3] "" Vector__XXX
 SG_ VariableSpdUpRInd : 0|2@1+ (1,0) [0|3] "" Vector__XXX

BO_ 2365544737 MCU_KEYPADI3: 8 MCU
 SG_ TrkExpansionLInd : 58|2@1+ (1,0) [0|3] "" Vector__XXX
 SG_ TrkExpansionCtrInd : 56|2@1+ (1,0) [0|3] "" Vector__XXX
 SG_ TrkExpansionRInd : 54|2@1+ (1,0) [0|3] "" Vector__XXX
 SG_ FrWpLInd : 52|2@1+ (1,0) [0|3] "" Vector__XXX
 SG_ FrWpCtrInd : 50|2@1+ (1,0) [0|3] "" Vector__XXX
 SG_ FrWpRInd : 48|2@1+ (1,0) [0|3] "" Vector__XXX
 SG_ RrWpLInd : 46|2@1+ (1,0) [0|3] "" Vector__XXX
 SG_ RrWpCtrInd : 44|2@1+ (1,0) [0|3] "" Vector__XXX
 SG_ RrWpRInd : 42|2@1+ (1,0) [0|3] "" Vector__XXX
 SG_ SideWpLInd : 40|2@1+ (1,0) [0|3] "" Vector__XXX
 SG_ SideWpCtrInd : 38|2@1+ (1,0) [0|3] "" Vector__XXX
 SG_ SideWpRInd : 36|2@1+ (1,0) [0|3] "" Vector__XXX
 SG_ FrWpWashLInd : 34|2@1+ (1,0) [0|3] "" Vector__XXX
 SG_ FrWpWashCtrInd : 32|2@1+ (1,0) [0|3] "" Vector__XXX
 SG_ FrWpWashRInd : 30|2@1+ (1,0) [0|3] "" Vector__XXX
 SG_ SideWpWashLInd : 28|2@1+ (1,0) [0|3] "" Vector__XXX
 SG_ SideWpWashCtrInd : 26|2@1+ (1,0) [0|3] "" Vector__XXX
 SG_ SideWpWashRInd : 24|2@1+ (1,0) [0|3] "" Vector__XXX
 SG_ RrMirrorHtLInd : 22|2@1+ (1,0) [0|3] "" Vector__XXX
 SG_ RrMirrorHtCtrInd : 20|2@1+ (1,0) [0|3] "" Vector__XXX
 SG_ RrMirrorHtRInd : 18|2@1+ (1,0) [0|3] "" Vector__XXX
 SG_ AirCompLInd : 16|2@1+ (1,0) [0|3] "" Vector__XXX
 SG_ AirCompCtrInd : 14|2@1+ (1,0) [0|3] "" Vector__XXX
 SG_ AirCompRInd : 12|2@1+ (1,0) [0|3] "" Vector__XXX
 SG_ TrvlSpdLInd : 10|2@1+ (1,0) [0|3] "" Vector__XXX
 SG_ TrvlSpdCtrInd : 8|2@1+ (1,0) [0|3] "" Vector__XXX
 SG_ TrvlSpdRInd : 6|2@1+ (1,0) [0|3] "" Vector__XXX
 SG_ BzStopLInd : 4|2@1+ (1,0) [0|3] "" Vector__XXX
 SG_ BzStopCtrInd : 2|2@1+ (1,0) [0|3] "" Vector__XXX
 SG_ BzStopRInd : 0|2@1+ (1,0) [0|3] "" Vector__XXX

BO_ 2566871629 CBSW_HCMD: 8 CBSW
 SG_ HornSwIn : 34|2@1+ (1,0) [0|3] "" Vector__XXX

BO_ 2566872001 IMU1_ASI: 8 IMU1
 SG_ AccRate : 0|21@1+ (189,-196245504) [-196245504|196245504] "umps2" Vector__XXX

BO_ 2566872002 IMU2_ASI: 8 IMU2
 SG_ AccRate : 0|21@1+ (189,-196245504) [-196245504|196245504] "umps2" Vector__XXX

BO_ 2566872003 IMU3_ASI: 8 IMU3
 SG_ AccRate : 0|21@1+ (189,-196245504) [-196245504|196245504] "umps2" Vector__XXX

BO_ 2566872004 IMU4_ASI: 8 IMU4
 SG_ AccRate : 0|21@1+ (189,-196245504) [-196245504|196245504] "umps2" Vector__XXX

BO_ 2566872005 IMU5_ASI: 8 IMU5
 SG_ AccRate : 0|21@1+ (189,-196245504) [-196245504|196245504] "umps2" Vector__XXX

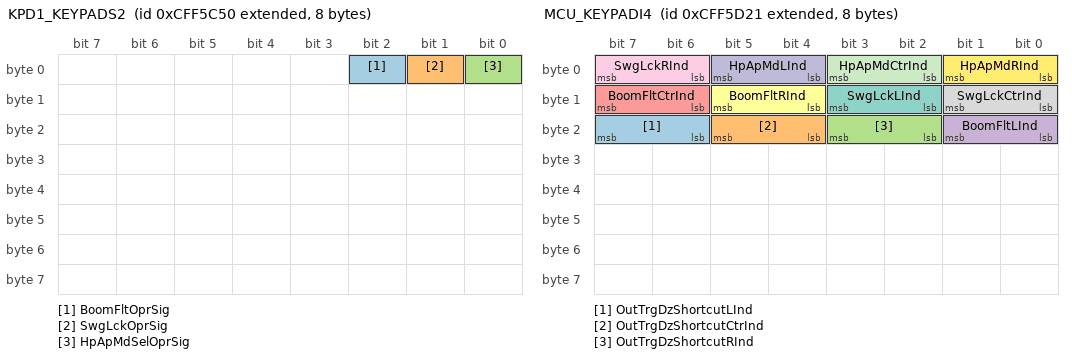
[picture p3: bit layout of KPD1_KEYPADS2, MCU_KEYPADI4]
BO_ 2365545552 KPD1_KEYPADS2: 8 KPD1
 SG_ BoomFltOprSig : 2|1@1+ (1,0) [0|1] "" Vector__XXX
 SG_ SwgLckOprSig : 1|1@1+ (1,0) [0|1] "" Vector__XXX
 SG_ HpApMdSelOprSig : 0|1@1+ (1,0) [0|1] "" Vector__XXX

BO_ 2365545761 MCU_KEYPADI4: 8 MCU
 SG_ OutTrgDzShortcutLInd : 22|2@1+ (1,0) [0|3] "" Vector__XXX
 SG_ OutTrgDzShortcutCtrInd : 20|2@1+ (1,0) [0|3] "" Vector__XXX
 SG_ OutTrgDzShortcutRInd : 18|2@1+ (1,0) [0|3] "" Vector__XXX
 SG_ BoomFltLInd : 16|2@1+ (1,0) [0|3] "" Vector__XXX
 SG_ BoomFltCtrInd : 14|2@1+ (1,0) [0|3] "" Vector__XXX
 SG_ BoomFltRInd : 12|2@1+ (1,0) [0|3] "" Vector__XXX
 SG_ SwgLckLInd : 10|2@1+ (1,0) [0|3] "" Vector__XXX
 SG_ SwgLckCtrInd : 8|2@1+ (1,0) [0|3] "" Vector__XXX
 SG_ SwgLckRInd : 6|2@1+ (1,0) [0|3] "" Vector__XXX
 SG_ HpApMdLInd : 4|2@1+ (1,0) [0|3] "" Vector__XXX
 SG_ HpApMdCtrInd : 2|2@1+ (1,0) [0|3] "" Vector__XXX
 SG_ HpApMdRInd : 0|2@1+ (1,0) [0|3] "" Vector__XXX

BO_ 2566873377 MCU_ACUCTR: 8 MCU
 SG_ LowOutReq8 : 46|2@1+ (1,0) [0|3] "" Vector__XXX
 SG_ LowOutReq7 : 44|2@1+ (1,0) [0|3] "" Vector__XXX
 SG_ LowOutReq6 : 42|2@1+ (1,0) [0|3] "" Vector__XXX
 SG_ LowOutReq5 : 40|2@1+ (1,0) [0|3] "" Vector__XXX
 SG_ LowOutReq4 : 38|2@1+ (1,0) [0|3] "" Vector__XXX
 SG_ LowOutReq3 : 36|2@1+ (1,0) [0|3] "" Vector__XXX
 SG_ LowOutReq2 : 34|2@1+ (1,0) [0|3] "" Vector__XXX
 SG_ LowOutReq1 : 32|2@1+ (1,0) [0|3] "" Vector__XXX
 SG_ OutReq15 : 28|2@1+ (1,0) [0|3] "" Vector__XXX
 SG_ OutReq14 : 26|2@1+ (1,0) [0|3] "" Vector__XXX
 SG_ OutReq13 : 24|2@1+ (1,0) [0|3] "" Vector__XXX
 SG_ OutReq12 : 22|2@1+ (1,0) [0|3] "" Vector__XXX
 SG_ OutReq11 : 20|2@1+ (1,0) [0|3] "" Vector__XXX
 SG_ OutReq10 : 18|2@1+ (1,0) [0|3] "" Vector__XXX
 SG_ OutReq9 : 16|2@1+ (1,0) [0|3] "" Vector__XXX
 SG_ OutReq8 : 14|2@1+ (1,0) [0|3] "" Vector__XXX
 SG_ OutReq7 : 12|2@1+ (1,0) [0|3] "" Vector__XXX
 SG_ OutReq6 : 10|2@1+ (1,0) [0|3] "" Vector__XXX
 SG_ OutReq5 : 8|2@1+ (1,0) [0|3] "" Vector__XXX
 SG_ OutReq4 : 6|2@1+ (1,0) [0|3] "" Vector__XXX
 SG_ OutReq3 : 4|2@1+ (1,0) [0|3] "" Vector__XXX
 SG_ OutReq2 : 2|2@1+ (1,0) [0|3] "" Vector__XXX
 SG_ OutReq1 : 0|2@1+ (1,0) [0|3] "" Vector__XXX

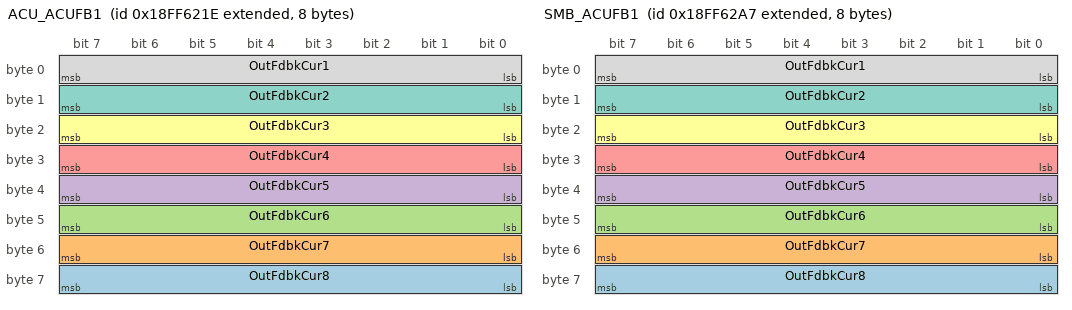
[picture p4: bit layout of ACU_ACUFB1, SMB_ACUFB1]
BO_ 2566873630 ACU_ACUFB1: 8 ACU
 SG_ OutFdbkCur8 : 56|8@1+ (1,0) [0|255] "" Vector__XXX
 SG_ OutFdbkCur7 : 48|8@1+ (1,0) [0|255] "" Vector__XXX
 SG_ OutFdbkCur6 : 40|8@1+ (1,0) [0|255] "" Vector__XXX
 SG_ OutFdbkCur5 : 32|8@1+ (1,0) [0|255] "" Vector__XXX
 SG_ OutFdbkCur4 : 24|8@1+ (1,0) [0|255] "" Vector__XXX
 SG_ OutFdbkCur3 : 16|8@1+ (1,0) [0|255] "" Vector__XXX
 SG_ OutFdbkCur2 : 8|8@1+ (1,0) [0|255] "" Vector__XXX
 SG_ OutFdbkCur1 : 0|8@1+ (0.05,0) [0|12.65] "A" Vector__XXX

BO_ 2566873767 SMB_ACUFB1: 8 SMB
 SG_ OutFdbkCur8 : 56|8@1+ (1,0) [0|255] "" Vector__XXX
 SG_ OutFdbkCur7 : 48|8@1+ (1,0) [0|255] "" Vector__XXX
 SG_ OutFdbkCur6 : 40|8@1+ (1,0) [0|255] "" Vector__XXX
 SG_ OutFdbkCur5 : 32|8@1+ (1,0) [0|255] "" Vector__XXX
 SG_ OutFdbkCur4 : 24|8@1+ (1,0) [0|255] "" Vector__XXX
 SG_ OutFdbkCur3 : 16|8@1+ (1,0) [0|255] "" Vector__XXX
 SG_ OutFdbkCur2 : 8|8@1+ (1,0) [0|255] "" Vector__XXX
 SG_ OutFdbkCur1 : 0|8@1+ (0.05,0) [0|12.65] "A" Vector__XXX

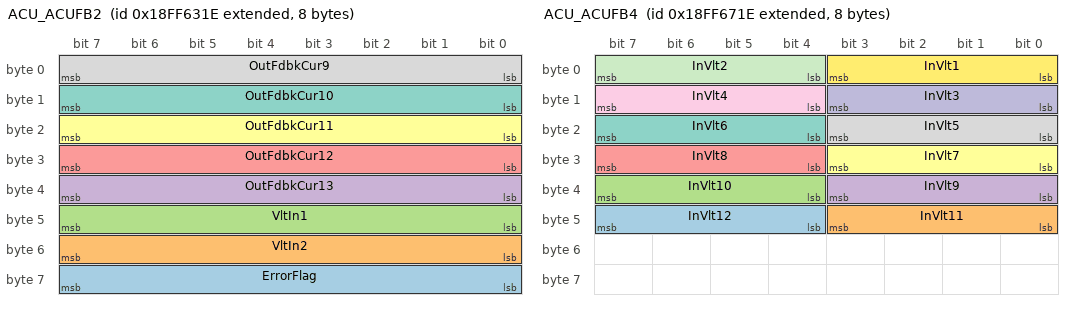
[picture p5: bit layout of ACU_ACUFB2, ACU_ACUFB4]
BO_ 2566873886 ACU_ACUFB2: 8 ACU
 SG_ ErrorFlag : 56|8@1+ (1,0) [0|255] "" Vector__XXX
 SG_ VltIn2 : 48|8@1+ (1,0) [0|255] "" Vector__XXX
 SG_ VltIn1 : 40|8@1+ (0.125,0) [0|31.625] "V" Vector__XXX
 SG_ OutFdbkCur13 : 32|8@1+ (1,0) [0|255] "" Vector__XXX
 SG_ OutFdbkCur12 : 24|8@1+ (1,0) [0|255] "" Vector__XXX
 SG_ OutFdbkCur11 : 16|8@1+ (1,0) [0|255] "" Vector__XXX
 SG_ OutFdbkCur10 : 8|8@1+ (1,0) [0|255] "" Vector__XXX
 SG_ OutFdbkCur9 : 0|8@1+ (0.05,0) [0|12.65] "A" Vector__XXX

BO_ 2566874654 ACU_ACUFB3: 8 ACU
 SG_ OutFdbkActvLowCur8 : 62|2@1+ (1,0) [0|3] "" Vector__XXX
 SG_ OutFdbkActvLowCur7 : 60|2@1+ (1,0) [0|3] "" Vector__XXX
 SG_ OutFdbkActvLowCur6 : 58|2@1+ (1,0) [0|3] "" Vector__XXX
 SG_ OutFdbkActvLowCur5 : 56|2@1+ (1,0) [0|3] "" Vector__XXX
 SG_ OutFdbkActvLowCur4 : 54|2@1+ (1,0) [0|3] "" Vector__XXX
 SG_ OutFdbkActvLowCur3 : 52|2@1+ (1,0) [0|3] "" Vector__XXX
 SG_ OutFdbkActvLowCur2 : 50|2@1+ (1,0) [0|3] "" Vector__XXX
 SG_ OutFdbkActvLowCur1 : 48|2@1+ (1,0) [0|3] "" Vector__XXX
 SG_ OutFdbkActvHighCur15 : 46|2@1+ (1,0) [0|3] "" Vector__XXX
 SG_ OutFdbkActvHighCur14 : 44|2@1+ (1,0) [0|3] "" Vector__XXX
 SG_ OutFdbkActvHighCur13 : 42|2@1+ (1,0) [0|3] "" Vector__XXX
 SG_ OutFdbkActvHighCur12 : 40|2@1+ (1,0) [0|3] "" Vector__XXX
 SG_ OutFdbkActvHighCur11 : 38|2@1+ (1,0) [0|3] "" Vector__XXX
 SG_ OutFdbkActvHighCur10 : 36|2@1+ (1,0) [0|3] "" Vector__XXX
 SG_ OutFdbkActvHighCur9 : 34|2@1+ (1,0) [0|3] "" Vector__XXX
 SG_ OutFdbkActvHighCur8 : 32|2@1+ (1,0) [0|3] "" Vector__XXX
 SG_ OutFdbkActvHighCur7 : 30|2@1+ (1,0) [0|3] "" Vector__XXX
 SG_ OutFdbkActvHighCur6 : 28|2@1+ (1,0) [0|3] "" Vector__XXX
 SG_ OutFdbkActvHighCur5 : 26|2@1+ (1,0) [0|3] "" Vector__XXX
 SG_ OutFdbkActvHighCur4 : 24|2@1+ (1,0) [0|3] "" Vector__XXX
 SG_ OutFdbkActvHighCur3 : 16|8@1+ (1,0) [0|255] "" Vector__XXX
 SG_ OutFdbkActvHighCur2 : 8|8@1+ (1,0) [0|255] "" Vector__XXX
 SG_ OutFdbkActvHighCur1 : 0|8@1+ (0.1,0) [0|25.3] "A" Vector__XXX

BO_ 2566874910 ACU_ACUFB4: 8 ACU
 SG_ InVlt12 : 44|4@1+ (1,0) [0|15] "" Vector__XXX
 SG_ InVlt11 : 40|4@1+ (1,0) [0|15] "" Vector__XXX
 SG_ InVlt10 : 36|4@1+ (1,0) [0|15] "" Vector__XXX
 SG_ InVlt9 : 32|4@1+ (1,0) [0|15] "" Vector__XXX
 SG_ InVlt8 : 28|4@1+ (1,0) [0|15] "" Vector__XXX
 SG_ InVlt7 : 24|4@1+ (1,0) [0|15] "" Vector__XXX
 SG_ InVlt6 : 20|4@1+ (1,0) [0|15] "" Vector__XXX
 SG_ InVlt5 : 16|4@1+ (1,0) [0|15] "" Vector__XXX
 SG_ InVlt4 : 12|4@1+ (1,0) [0|15] "" Vector__XXX
 SG_ InVlt3 : 8|4@1+ (1,0) [0|15] "" Vector__XXX
 SG_ InVlt2 : 4|4@1+ (1,0) [0|15] "" Vector__XXX
 SG_ InVlt1 : 0|4@1+ (2,0) [0|30] "V" Vector__XXX

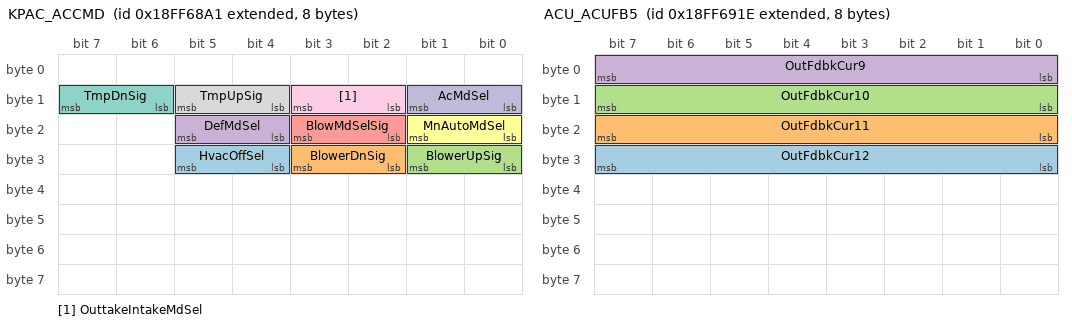
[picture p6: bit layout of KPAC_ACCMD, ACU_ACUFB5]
BO_ 2566875297 KPAC_ACCMD: 8 KPAC
 SG_ HvacOffSel : 28|2@1+ (1,0) [0|3] "" Vector__XXX
 SG_ BlowerDnSig : 26|2@1+ (1,0) [0|3] "" Vector__XXX
 SG_ BlowerUpSig : 24|2@1+ (1,0) [0|3] "" Vector__XXX
 SG_ DefMdSel : 20|2@1+ (1,0) [0|3] "" Vector__XXX
 SG_ BlowMdSelSig : 18|2@1+ (1,0) [0|3] "" Vector__XXX
 SG_ MnAutoMdSel : 16|2@1+ (1,0) [0|3] "" Vector__XXX
 SG_ TmpDnSig : 14|2@1+ (1,0) [0|3] "" Vector__XXX
 SG_ TmpUpSig : 12|2@1+ (1,0) [0|3] "" Vector__XXX
 SG_ OuttakeIntakeMdSel : 10|2@1+ (1,0) [0|3] "" Vector__XXX
 SG_ AcMdSel : 8|2@1+ (1,0) [0|3] "" Vector__XXX

BO_ 2566875422 ACU_ACUFB5: 8 ACU
 SG_ OutFdbkCur12 : 24|8@1+ (1,0) [0|255] "" Vector__XXX
 SG_ OutFdbkCur11 : 16|8@1+ (1,0) [0|255] "" Vector__XXX
 SG_ OutFdbkCur10 : 8|8@1+ (1,0) [0|255] "" Vector__XXX
 SG_ OutFdbkCur9 : 0|8@1+ (0.1,0) [0|25.3] "A" Vector__XXX

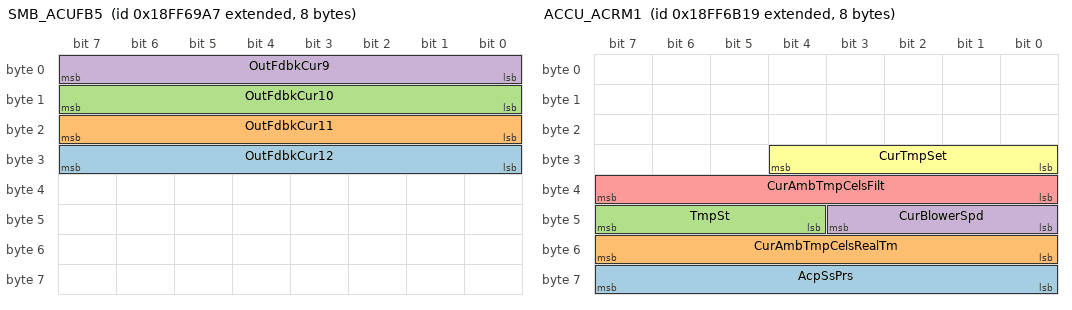
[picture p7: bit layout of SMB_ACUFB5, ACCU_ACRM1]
BO_ 2566875559 SMB_ACUFB5: 8 SMB
 SG_ OutFdbkCur12 : 24|8@1+ (1,0) [0|255] "" Vector__XXX
 SG_ OutFdbkCur11 : 16|8@1+ (1,0) [0|255] "" Vector__XXX
 SG_ OutFdbkCur10 : 8|8@1+ (1,0) [0|255] "" Vector__XXX
 SG_ OutFdbkCur9 : 0|8@1+ (0.1,0) [0|25.3] "A" Vector__XXX

BO_ 2566875678 ACU_ACUFB6: 28 ACU
 SG_ MiniRly30AFuse2St : 221|1@1+ (1,0) [0|1] "" Vector__XXX
 SG_ MiniRly30AFuse1St : 220|1@1+ (1,0) [0|1] "" Vector__XXX
 SG_ MicroRly20AFuse5St : 219|1@1+ (1,0) [0|1] "" Vector__XXX
 SG_ MicroRly20AFuse4St : 218|1@1+ (1,0) [0|1] "" Vector__XXX
 SG_ MicroRly20AFuse3St : 217|1@1+ (1,0) [0|1] "" Vector__XXX
 SG_ MicroRly20AFuse2St : 216|1@1+ (1,0) [0|1] "" Vector__XXX
 SG_ MicroRly20AFuse1St : 215|1@1+ (1,0) [0|1] "" Vector__XXX
 SG_ KeyOn30AFuse5St : 214|1@1+ (1,0) [0|1] "" Vector__XXX
 SG_ KeyOn30AFuse4St : 213|1@1+ (1,0) [0|1] "" Vector__XXX
 SG_ KeyOn30AFuse3St : 212|1@1+ (1,0) [0|1] "" Vector__XXX
 SG_ KeyOn30AFuse2St : 211|1@1+ (1,0) [0|1] "" Vector__XXX
 SG_ KeyOn30AFuse1St : 210|1@1+ (1,0) [0|1] "" Vector__XXX
 SG_ KeyOn20AFuse10St : 209|1@1+ (1,0) [0|1] "" Vector__XXX
 SG_ KeyOn20AFuse9St : 208|1@1+ (1,0) [0|1] "" Vector__XXX
 SG_ KeyOn20AFuse8St : 207|1@1+ (1,0) [0|1] "" Vector__XXX
 SG_ KeyOn20AFuse7St : 206|1@1+ (1,0) [0|1] "" Vector__XXX
 SG_ KeyOn20AFuse6St : 205|1@1+ (1,0) [0|1] "" Vector__XXX
 SG_ KeyOn20AFuse5St : 204|1@1+ (1,0) [0|1] "" Vector__XXX
 SG_ KeyOn20AFuse4St : 203|1@1+ (1,0) [0|1] "" Vector__XXX
 SG_ KeyOn20AFuse3St : 202|1@1+ (1,0) [0|1] "" Vector__XXX
 SG_ KeyOn20AFuse2St : 201|1@1+ (1,0) [0|1] "" Vector__XXX
 SG_ KeyOn20AFuse1St : 200|1@1+ (1,0) [0|1] "" Vector__XXX
 SG_ KeyOn10AFuse5St : 199|1@1+ (1,0) [0|1] "" Vector__XXX
 SG_ KeyOn10AFuse4St : 198|1@1+ (1,0) [0|1] "" Vector__XXX
 SG_ KeyOn10AFuse3St : 197|1@1+ (1,0) [0|1] "" Vector__XXX
 SG_ KeyOn10AFuse2St : 196|1@1+ (1,0) [0|1] "" Vector__XXX
 SG_ KeyOn10AFuse1St : 195|1@1+ (1,0) [0|1] "" Vector__XXX
 SG_ KeyOn5AFuse15St : 194|1@1+ (1,0) [0|1] "" Vector__XXX
 SG_ KeyOn5AFuse14St : 193|1@1+ (1,0) [0|1] "" Vector__XXX
 SG_ KeyOn5AFuse13St : 192|1@1+ (1,0) [0|1] "" Vector__XXX
 SG_ KeyOn5AFuse12St : 191|1@1+ (1,0) [0|1] "" Vector__XXX
 SG_ KeyOn5AFuse11St : 190|1@1+ (1,0) [0|1] "" Vector__XXX
 SG_ KeyOn5AFuse10St : 189|1@1+ (1,0) [0|1] "" Vector__XXX
 SG_ KeyOn5AFuse9St : 188|1@1+ (1,0) [0|1] "" Vector__XXX
 SG_ KeyOn5AFuse8St : 187|1@1+ (1,0) [0|1] "" Vector__XXX
 SG_ KeyOn5AFuse7St : 186|1@1+ (1,0) [0|1] "" Vector__XXX
 SG_ KeyOn5AFuse6St : 185|1@1+ (1,0) [0|1] "" Vector__XXX
 SG_ KeyOn5AFuse5St : 184|1@1+ (1,0) [0|1] "" Vector__XXX
 SG_ KeyOn5AFuse4St : 183|1@1+ (1,0) [0|1] "" Vector__XXX
 SG_ KeyOn5AFuse3St : 182|1@1+ (1,0) [0|1] "" Vector__XXX
 SG_ KeyOn5AFuse2St : 181|1@1+ (1,0) [0|1] "" Vector__XXX
 SG_ KeyOn5AFuse1St : 180|1@1+ (1,0) [0|1] "" Vector__XXX
 SG_ BPlus30AFuse5St : 179|1@1+ (1,0) [0|1] "" Vector__XXX
 SG_ BPlus30AFuse4St : 178|1@1+ (1,0) [0|1] "" Vector__XXX
 SG_ BPlus30AFuse3St : 177|1@1+ (1,0) [0|1] "" Vector__XXX
 SG_ BPlus30AFuse2St : 176|1@1+ (1,0) [0|1] "" Vector__XXX
 SG_ BPlus30AFuse1St : 175|1@1+ (1,0) [0|1] "" Vector__XXX
 SG_ BPlus20AFuse5St : 174|1@1+ (1,0) [0|1] "" Vector__XXX
 SG_ BPlus20AFuse4St : 173|1@1+ (1,0) [0|1] "" Vector__XXX
 SG_ BPlus20AFuse3St : 172|1@1+ (1,0) [0|1] "" Vector__XXX
 SG_ BPlus20AFuse2St : 171|1@1+ (1,0) [0|1] "" Vector__XXX
 SG_ BPlus20AFuse1St : 170|1@1+ (1,0) [0|1] "" Vector__XXX
 SG_ BPlus5AFuse10St : 169|1@1+ (1,0) [0|1] "" Vector__XXX
 SG_ BPlus5AFuse9St : 168|1@1+ (1,0) [0|1] "" Vector__XXX
 SG_ BPlus5AFuse8St : 167|1@1+ (1,0) [0|1] "" Vector__XXX
 SG_ BPlus5AFuse7St : 166|1@1+ (1,0) [0|1] "" Vector__XXX
 SG_ BPlus5AFuse6St : 165|1@1+ (1,0) [0|1] "" Vector__XXX
 SG_ BPlus5AFuse5St : 164|1@1+ (1,0) [0|1] "" Vector__XXX
 SG_ BPlus5AFuse4St : 163|1@1+ (1,0) [0|1] "" Vector__XXX
 SG_ BPlus5AFuse3St : 162|1@1+ (1,0) [0|1] "" Vector__XXX
 SG_ BPlus5AFuse2St : 161|1@1+ (1,0) [0|1] "" Vector__XXX
 SG_ BPlus5AFuse1St : 160|1@1+ (1,0) [0|1] "" Vector__XXX
 SG_ IpsTotalCur : 144|16@1+ (0.1,0) [0|102] "percent" Vector__XXX
 SG_ MINIFuse2Cur : 128|16@1+ (0.05,0) [0|3212.75] "A" Vector__XXX
 SG_ MINIFuse1Cur : 112|16@1+ (0.05,0) [0|3212.75] "A" Vector__XXX
 SG_ MicroFuse5Cur : 96|16@1+ (0.05,0) [0|3212.75] "A" Vector__XXX
 SG_ MicroFuse4Cur : 80|16@1+ (0.05,0) [0|3212.75] "A" Vector__XXX
 SG_ MicroFuse3Cur : 64|16@1+ (0.05,0) [0|3212.75] "A" Vector__XXX
 SG_ MicroFuse2Cur : 48|16@1+ (0.05,0) [0|3212.75] "A" Vector__XXX
 SG_ MicroFuse1Cur : 32|16@1+ (0.05,0) [0|3212.75] "A" Vector__XXX
 SG_ KeyOnPwrCur : 16|16@1+ (0.05,0) [0|3212.75] "A" Vector__XXX
 SG_ BPlusPwrCur : 0|16@1+ (0.05,0) [0|3212.75] "A" Vector__XXX

BO_ 2566875815 SMB_ACUFB6: 28 SMB
 SG_ MiniRly30AFuse2St : 221|1@1+ (1,0) [0|1] "" Vector__XXX
 SG_ MiniRly30AFuse1St : 220|1@1+ (1,0) [0|1] "" Vector__XXX
 SG_ MicroRly20AFuse5St : 219|1@1+ (1,0) [0|1] "" Vector__XXX
 SG_ MicroRly20AFuse4St : 218|1@1+ (1,0) [0|1] "" Vector__XXX
 SG_ MicroRly20AFuse3St : 217|1@1+ (1,0) [0|1] "" Vector__XXX
 SG_ MicroRly20AFuse2St : 216|1@1+ (1,0) [0|1] "" Vector__XXX
 SG_ MicroRly20AFuse1St : 215|1@1+ (1,0) [0|1] "" Vector__XXX
 SG_ KeyOn30AFuse5St : 214|1@1+ (1,0) [0|1] "" Vector__XXX
 SG_ KeyOn30AFuse4St : 213|1@1+ (1,0) [0|1] "" Vector__XXX
 SG_ KeyOn30AFuse3St : 212|1@1+ (1,0) [0|1] "" Vector__XXX
 SG_ KeyOn30AFuse2St : 211|1@1+ (1,0) [0|1] "" Vector__XXX
 SG_ KeyOn30AFuse1St : 210|1@1+ (1,0) [0|1] "" Vector__XXX
 SG_ KeyOn20AFuse10St : 209|1@1+ (1,0) [0|1] "" Vector__XXX
 SG_ KeyOn20AFuse9St : 208|1@1+ (1,0) [0|1] "" Vector__XXX
 SG_ KeyOn20AFuse8St : 207|1@1+ (1,0) [0|1] "" Vector__XXX
 SG_ KeyOn20AFuse7St : 206|1@1+ (1,0) [0|1] "" Vector__XXX
 SG_ KeyOn20AFuse6St : 205|1@1+ (1,0) [0|1] "" Vector__XXX
 SG_ KeyOn20AFuse5St : 204|1@1+ (1,0) [0|1] "" Vector__XXX
 SG_ KeyOn20AFuse4St : 203|1@1+ (1,0) [0|1] "" Vector__XXX
 SG_ KeyOn20AFuse3St : 202|1@1+ (1,0) [0|1] "" Vector__XXX
 SG_ KeyOn20AFuse2St : 201|1@1+ (1,0) [0|1] "" Vector__XXX
 SG_ KeyOn20AFuse1St : 200|1@1+ (1,0) [0|1] "" Vector__XXX
 SG_ KeyOn10AFuse5St : 199|1@1+ (1,0) [0|1] "" Vector__XXX
 SG_ KeyOn10AFuse4St : 198|1@1+ (1,0) [0|1] "" Vector__XXX
 SG_ KeyOn10AFuse3St : 197|1@1+ (1,0) [0|1] "" Vector__XXX
 SG_ KeyOn10AFuse2St : 196|1@1+ (1,0) [0|1] "" Vector__XXX
 SG_ KeyOn10AFuse1St : 195|1@1+ (1,0) [0|1] "" Vector__XXX
 SG_ KeyOn5AFuse15St : 194|1@1+ (1,0) [0|1] "" Vector__XXX
 SG_ KeyOn5AFuse14St : 193|1@1+ (1,0) [0|1] "" Vector__XXX
 SG_ KeyOn5AFuse13St : 192|1@1+ (1,0) [0|1] "" Vector__XXX
 SG_ KeyOn5AFuse12St : 191|1@1+ (1,0) [0|1] "" Vector__XXX
 SG_ KeyOn5AFuse11St : 190|1@1+ (1,0) [0|1] "" Vector__XXX
 SG_ KeyOn5AFuse10St : 189|1@1+ (1,0) [0|1] "" Vector__XXX
 SG_ KeyOn5AFuse9St : 188|1@1+ (1,0) [0|1] "" Vector__XXX
 SG_ KeyOn5AFuse8St : 187|1@1+ (1,0) [0|1] "" Vector__XXX
 SG_ KeyOn5AFuse7St : 186|1@1+ (1,0) [0|1] "" Vector__XXX
 SG_ KeyOn5AFuse6St : 185|1@1+ (1,0) [0|1] "" Vector__XXX
 SG_ KeyOn5AFuse5St : 184|1@1+ (1,0) [0|1] "" Vector__XXX
 SG_ KeyOn5AFuse4St : 183|1@1+ (1,0) [0|1] "" Vector__XXX
 SG_ KeyOn5AFuse3St : 182|1@1+ (1,0) [0|1] "" Vector__XXX
 SG_ KeyOn5AFuse2St : 181|1@1+ (1,0) [0|1] "" Vector__XXX
 SG_ KeyOn5AFuse1St : 180|1@1+ (1,0) [0|1] "" Vector__XXX
 SG_ BPlus30AFuse5St : 179|1@1+ (1,0) [0|1] "" Vector__XXX
 SG_ BPlus30AFuse4St : 178|1@1+ (1,0) [0|1] "" Vector__XXX
 SG_ BPlus30AFuse3St : 177|1@1+ (1,0) [0|1] "" Vector__XXX
 SG_ BPlus30AFuse2St : 176|1@1+ (1,0) [0|1] "" Vector__XXX
 SG_ BPlus30AFuse1St : 175|1@1+ (1,0) [0|1] "" Vector__XXX
 SG_ BPlus20AFuse5St : 174|1@1+ (1,0) [0|1] "" Vector__XXX
 SG_ BPlus20AFuse4St : 173|1@1+ (1,0) [0|1] "" Vector__XXX
 SG_ BPlus20AFuse3St : 172|1@1+ (1,0) [0|1] "" Vector__XXX
 SG_ BPlus20AFuse2St : 171|1@1+ (1,0) [0|1] "" Vector__XXX
 SG_ BPlus20AFuse1St : 170|1@1+ (1,0) [0|1] "" Vector__XXX
 SG_ BPlus5AFuse10St : 169|1@1+ (1,0) [0|1] "" Vector__XXX
 SG_ BPlus5AFuse9St : 168|1@1+ (1,0) [0|1] "" Vector__XXX
 SG_ BPlus5AFuse8St : 167|1@1+ (1,0) [0|1] "" Vector__XXX
 SG_ BPlus5AFuse7St : 166|1@1+ (1,0) [0|1] "" Vector__XXX
 SG_ BPlus5AFuse6St : 165|1@1+ (1,0) [0|1] "" Vector__XXX
 SG_ BPlus5AFuse5St : 164|1@1+ (1,0) [0|1] "" Vector__XXX
 SG_ BPlus5AFuse4St : 163|1@1+ (1,0) [0|1] "" Vector__XXX
 SG_ BPlus5AFuse3St : 162|1@1+ (1,0) [0|1] "" Vector__XXX
 SG_ BPlus5AFuse2St : 161|1@1+ (1,0) [0|1] "" Vector__XXX
 SG_ BPlus5AFuse1St : 160|1@1+ (1,0) [0|1] "" Vector__XXX
 SG_ IpsTotalCur : 144|16@1+ (0.1,0) [0|102] "percent" Vector__XXX
 SG_ MINIFuse2Cur : 128|16@1+ (0.05,0) [0|3212.75] "A" Vector__XXX
 SG_ MINIFuse1Cur : 112|16@1+ (0.05,0) [0|3212.75] "A" Vector__XXX
 SG_ MicroFuse5Cur : 96|16@1+ (0.05,0) [0|3212.75] "A" Vector__XXX
 SG_ MicroFuse4Cur : 80|16@1+ (0.05,0) [0|3212.75] "A" Vector__XXX
 SG_ MicroFuse3Cur : 64|16@1+ (0.05,0) [0|3212.75] "A" Vector__XXX
 SG_ MicroFuse2Cur : 48|16@1+ (0.05,0) [0|3212.75] "A" Vector__XXX
 SG_ MicroFuse1Cur : 32|16@1+ (0.05,0) [0|3212.75] "A" Vector__XXX
 SG_ KeyOnPwrCur : 16|16@1+ (0.05,0) [0|3212.75] "A" Vector__XXX
 SG_ BPlusPwrCur : 0|16@1+ (0.05,0) [0|3212.75] "A" Vector__XXX

BO_ 2566875929 ACCU_ACRM1: 8 ACCU
 SG_ AcpSsPrs : 56|8@1+ (16,0) [0|4000] "" Vector__XXX
 SG_ CurAmbTmpCelsRealTm : 48|8@1- (0.5,-40) [-40|86] "Celsius" Vector__XXX
 SG_ TmpSt : 44|4@1+ (1,0) [1|15] "Step" Vector__XXX
 SG_ CurBlowerSpd : 40|4@1+ (1,0) [0|13] "" Vector__XXX
 SG_ CurAmbTmpCelsFilt : 32|8@1- (0.5,-40) [-40|86] "Celsius" Vector__XXX
 SG_ CurTmpSet : 24|5@1+ (0.5,17) [17|32] "Celsius" Vector__XXX

BO_ 2566876320 Audio_DCAI: 8 Audio

BO_ 2566876576 Audio_AFRTGP: 1785 Audio
 SG_ ReqPgn : 8|24@1+ (1,0) [0|16777215] "" Vector__XXX
 SG_ MsgCounter : 0|4@1+ (1,0) [0|15] "" Vector__XXX

BO_ 2566876832 Audio_APFGP: 72 Audio
 SG_ AdoPreSetAma6FrqtoGp : 560|16@1+ (1,0) [0|2000] "KHz" Vector__XXX
 SG_ AdoPreSetAma5FrqtoGp : 544|16@1+ (1,0) [0|2000] "KHz" Vector__XXX
 SG_ AdoPreSetAma4FrqtoGp : 528|16@1+ (1,0) [0|2000] "KHz" Vector__XXX
 SG_ AdoPreSetAma3FrqtoGp : 512|16@1+ (1,0) [0|2000] "KHz" Vector__XXX
 SG_ AdoPreSetAma2FrqtoGp : 496|16@1+ (1,0) [0|2000] "KHz" Vector__XXX
 SG_ AdoPreSetAma1FrqtoGp : 480|16@1+ (1,0) [0|2000] "KHz" Vector__XXX
 SG_ AdoPreSetAm26FrqtoGp : 464|16@1+ (1,0) [0|2000] "KHz" Vector__XXX
 SG_ AdoPreSetAm25FrqtoGp : 448|16@1+ (1,0) [0|2000] "KHz" Vector__XXX
 SG_ AdoPreSetAm24FrqtoGp : 432|16@1+ (1,0) [0|2000] "KHz" Vector__XXX
 SG_ AdoPreSetAm23FrqtoGp : 416|16@1+ (1,0) [0|2000] "KHz" Vector__XXX
 SG_ AdoPreSetAm22FrqtoGp : 400|16@1+ (1,0) [0|2000] "KHz" Vector__XXX
 SG_ AdoPreSetAm21FrqtoGp : 384|16@1+ (1,0) [0|2000] "KHz" Vector__XXX
 SG_ AdoPreSetAm16FrqtoGp : 368|16@1+ (1,0) [0|2000] "KHz" Vector__XXX
 SG_ AdoPreSetAm15FrqtoGp : 352|16@1+ (1,0) [0|2000] "KHz" Vector__XXX
 SG_ AdoPreSetAm14FrqtoGp : 336|16@1+ (1,0) [0|2000] "KHz" Vector__XXX
 SG_ AdoPreSetAm13FrqtoGp : 320|16@1+ (1,0) [0|2000] "KHz" Vector__XXX
 SG_ AdoPreSetAm12FrqtoGp : 304|16@1+ (1,0) [0|2000] "KHz" Vector__XXX
 SG_ AdoPreSetAm11FrqtoGp : 288|16@1+ (1,0) [0|2000] "KHz" Vector__XXX
 SG_ AdoPreSetFma6FrqtoGp : 272|16@1+ (0.05,0) [0|200] "MHz" Vector__XXX
 SG_ AdoPreSetFma5FrqtoGp : 256|16@1+ (0.05,0) [0|200] "MHz" Vector__XXX
 SG_ AdoPreSetFma4FrqtoGp : 240|16@1+ (0.05,0) [0|200] "MHz" Vector__XXX
 SG_ AdoPreSetFma3FrqtoGp : 224|16@1+ (0.05,0) [0|200] "MHz" Vector__XXX
 SG_ AdoPreSetFma2FrqtoGp : 208|16@1+ (0.05,0) [0|200] "MHz" Vector__XXX
 SG_ AdoPreSetFma1FrqtoGp : 192|16@1+ (0.05,0) [0|200] "MHz" Vector__XXX
 SG_ AdoPreSetFm26FrqtoGp : 176|16@1+ (0.05,0) [0|200] "MHz" Vector__XXX
 SG_ AdoPreSetFm25FrqtoGp : 160|16@1+ (0.05,0) [0|200] "MHz" Vector__XXX
 SG_ AdoPreSetFm24FrqtoGp : 144|16@1+ (0.05,0) [0|200] "MHz" Vector__XXX
 SG_ AdoPreSetFm23FrqtoGp : 128|16@1+ (0.05,0) [0|200] "MHz" Vector__XXX
 SG_ AdoPreSetFm22FrqtoGp : 112|16@1+ (0.05,0) [0|200] "MHz" Vector__XXX
 SG_ AdoPreSetFm21FrqtoGp : 96|16@1+ (0.05,0) [0|200] "MHz" Vector__XXX
 SG_ AdoPreSetFm16FrqtoGp : 80|16@1+ (0.05,0) [0|200] "MHz" Vector__XXX
 SG_ AdoPreSetFm15FrqtoGp : 64|16@1+ (0.05,0) [0|200] "MHz" Vector__XXX
 SG_ AdoPreSetFm14FrqtoGp : 48|16@1+ (0.05,0) [0|200] "MHz" Vector__XXX
 SG_ AdoPreSetFm13FrqtoGp : 32|16@1+ (0.05,0) [0|200] "MHz" Vector__XXX
 SG_ AdoPreSetFm12FrqtoGp : 16|16@1+ (0.05,0) [0|200] "MHz" Vector__XXX
 SG_ AdoPreSetFm11FrqtoGp : 0|16@1+ (0.05,0) [0|200] "MHz" Vector__XXX

BO_ 2566876961 MCU_ACUCTR2: 8 MCU
 SG_ LowOutReq8 : 46|2@1+ (1,0) [0|3] "" Vector__XXX
 SG_ LowOutReq7 : 44|2@1+ (1,0) [0|3] "" Vector__XXX
 SG_ LowOutReq6 : 42|2@1+ (1,0) [0|3] "" Vector__XXX
 SG_ LowOutReq5 : 40|2@1+ (1,0) [0|3] "" Vector__XXX
 SG_ LowOutReq4 : 38|2@1+ (1,0) [0|3] "" Vector__XXX
 SG_ LowOutReq3 : 36|2@1+ (1,0) [0|3] "" Vector__XXX
 SG_ LowOutReq2 : 34|2@1+ (1,0) [0|3] "" Vector__XXX
 SG_ LowOutReq1 : 32|2@1+ (1,0) [0|3] "" Vector__XXX
 SG_ OutReq15 : 28|2@1+ (1,0) [0|3] "" Vector__XXX
 SG_ OutReq14 : 26|2@1+ (1,0) [0|3] "" Vector__XXX
 SG_ OutReq13 : 24|2@1+ (1,0) [0|3] "" Vector__XXX
 SG_ OutReq12 : 22|2@1+ (1,0) [0|3] "" Vector__XXX
 SG_ OutReq11 : 20|2@1+ (1,0) [0|3] "" Vector__XXX
 SG_ OutReq10 : 18|2@1+ (1,0) [0|3] "" Vector__XXX
 SG_ OutReq9 : 16|2@1+ (1,0) [0|3] "" Vector__XXX
 SG_ OutReq8 : 14|2@1+ (1,0) [0|3] "" Vector__XXX
 SG_ OutReq7 : 12|2@1+ (1,0) [0|3] "" Vector__XXX
 SG_ OutReq6 : 10|2@1+ (1,0) [0|3] "" Vector__XXX
 SG_ OutReq5 : 8|2@1+ (1,0) [0|3] "" Vector__XXX
 SG_ OutReq4 : 6|2@1+ (1,0) [0|3] "" Vector__XXX
 SG_ OutReq3 : 4|2@1+ (1,0) [0|3] "" Vector__XXX
 SG_ OutReq2 : 2|2@1+ (1,0) [0|3] "" Vector__XXX
 SG_ OutReq1 : 0|2@1+ (1,0) [0|3] "" Vector__XXX

CM_ BO_ 2566866721 "State Information Group 3";
CM_ SG_ 2566866721 DifActlTrgGrdt "Warningpop-up;InterlockDetail-DifferenceActualandTargetGradient";
CM_ SG_ 2566866721 OprPrsntSt "Warningpop-up;InterlockDetail-OperatorPresentState";
CM_ SG_ 2566866721 HydCutOffRls "Warningpop-up;InterlockDetail-HydraulicCutOffRelease";
CM_ SG_ 2566866721 ChgErr "Warningpop-up;Chargingisabnormal";
CM_ SG_ 2566866721 ChgSt "VehicleStateSymbol;ChargingStatus";
CM_ SG_ 2566866721 WrkTrv "VehicleStateSymbol;Working/Travelenable";
CM_ SG_ 2566866721 BatLw "Warningpop-up;LowBattery";
CM_ SG_ 2566866721 HydLck "IndicatorSymbol;HydraulicLock";
CM_ SG_ 2566866721 PopCmdHillDscntCtrl "Pop-up Indication Command; Hill Descent Control Pop-up";
CM_ SG_ 2566866721 HillDscntCtrlSt "IndicatorSymbol;HillDescentControlStatus";
CM_ SG_ 2566866721 OprPrsnc "IndicatorSymbol;OperatorPresence";
CM_ SG_ 2566866721 BckDust "IndicatorSymbol;BucketDusting";
CM_ SG_ 2566866721 BmsPrhtLmp "IndicatorSymbol;BMSPreheatLamp";
CM_ SG_ 2566866721 DacSt "DACState";
CM_ SG_ 2566866721 EmcvFngrtpLvrErr "Popup DisplayCommand;E-MCVFingertipLeverErrorPop-up";
CM_ SG_ 2566866721 PopCmdFnrNtrl "Pop-up Indication Command; FNR Neutral";
CM_ SG_ 2566866721 IllminSt "IlluminationStatus";
CM_ SG_ 2566866721 ChmslSt "CHMSLStatus";
CM_ SG_ 2566866721 CdsFanRvsSt "IndicatorSymbol;CondenserFanReverseState";
CM_ SG_ 2566866721 CacFanRvsSt "IndicatorSymbol;CACFanReverseState";
CM_ SG_ 2566866721 CurMaxSpdMinor "Current Max. Speed minor";
CM_ SG_ 2566866721 WhlTypeStrMd "Wheel Type Symbol; Steering Mode";
CM_ SG_ 2566866721 WrnGndSlop "WarningPop-up;GroundSlopeforWeighing";
CM_ SG_ 2566866721 WrnOilTmpLw "WarningPop-up;OilTemperaturetooLowforWeighing";
CM_ SG_ 2566866721 WghConfirmWarnMsg "Warning Pop-up; Weighing Confirm Warning Message";
CM_ SG_ 2566866721 AttOpr "AttachmentOperatingSignal";
CM_ SG_ 2566866721 QckCoolSt "Quick Cooling Status";
CM_ SG_ 2566866721 PopCmdBckAstTargetSet "Pop-up Indication Command; Bucket Assist Target Set";
CM_ SG_ 2566866721 WrnLimpHome "Warningpop-up;LimpHome";
CM_ SG_ 2566866721 DozAstStopReq "Dozing Assit Stop Request";
CM_ SG_ 2566866721 MchCond "MachineCondition";
CM_ SG_ 2566866721 WrnRollOvr "Warningpop-up;Rollover";
CM_ SG_ 2566866721 WrnArmPosOnDrv "Warningpop-up;ArmPositionondriving";
CM_ SG_ 2566866721 WrnThwStrShft "Warningpop-up;ThumbWheelSteeringShifting";
CM_ SG_ 2566866721 WrnRamLck "Popup DisplayCommand;RAMLockinformation";
CM_ SG_ 2566866721 WrnHstOilFilt "Warningpop-up;HSTOilFilter";
CM_ SG_ 2566866721 WrnGrBoxOvTmp "Warningpop-up;GearboxOverTemperature";
CM_ SG_ 2566866721 VhcStTractionLv "VehicleStateSymbol;TractionLevel";
CM_ SG_ 2566866721 WhlLis "WheelTypeSymbol;LIS";
CM_ SG_ 2566866721 WhlDzTrlHitch "WheelTypeSymbol;Dozer/TrailerHitch";
CM_ SG_ 2566866721 WhlSwgAlign "WheelTypeSymbol;SwingAlign";
CM_ SG_ 2566866721 WhlRamLckAuto "WheelTypeSymbol;RAMLockAuto";
CM_ BO_ 2566866977 "Gauge Data Group 2";
CM_ SG_ 2566866977 GdTrsmSumpOilTmp "Gauge Data; Transmission Sump Oil Temperature";
CM_ SG_ 2566866977 BrkChgLv "Gauge Data; Brake Charging Level";
CM_ SG_ 2566866977 TrgRollSlp "TargetRollSlope";
CM_ SG_ 2566866977 TrgPchSlp "TargetPitchSlope";
CM_ SG_ 2566866977 CorrRollSlp "CorrectedRollSlope";
CM_ SG_ 2566866977 CorrPchSlp "CorrectedPitchSlope";
CM_ SG_ 2566866977 CorrRollAng "CorrectedRollAngle";
CM_ SG_ 2566866977 CorrPchAng "CorrectedPitchAngle";
CM_ BO_ 2566867233 "Gauge Data Group 3";
CM_ SG_ 2566867233 TrgRollSlp "TargetRollSlope";
CM_ SG_ 2566867233 TrgPchSlp "TargetPitchSlope";
CM_ SG_ 2566867233 CorrRollSlp "CorrectedRollSlope";
CM_ SG_ 2566867233 CorrPchSlp "CorrectedPitchSlope";
CM_ BO_ 2566867489 "State Information Group 4";
CM_ SG_ 2566867489 WarnPopLimitangexcess "Warning pop-up; Limit angle excess";
CM_ SG_ 2566867489 WarnPopMgMcSsErr "Warning pop-up; MG/MC Sensor Error";
CM_ SG_ 2566867489 McTemporaryRlsPop "MC Temporary Release Pop-up";
CM_ SG_ 2566867489 VhcStStickStr "Vehicle State Symbol; Stick Steering";
CM_ SG_ 2566867489 VhcStFineSwg "Vehicle State Symbol; Fine Swing";
CM_ SG_ 2566867489 ActTrvlSpdforCrwl "Actual Travel Speed for Crawler";
CM_ SG_ 2566867489 ActTrvlStforCrwl "Actual Travel Status for Crawler";
CM_ SG_ 2566867489 VhcStParallelLift "Vehicle State Symbol; Parallel Lift";
CM_ SG_ 2566867489 VhcStFrSspnAuto "Vehicle State Symbol; Front Suspension Auto";
CM_ SG_ 2566867489 RmCrakingSt "Remote Craking Status";
CM_ SG_ 2566867489 IndTrmsColdStart "Indicator Symbol; Transmission Cold Start";
CM_ SG_ 2566867489 VhcStElevatingCabin "Vehicle State Symbol; Elevating Cabin";
CM_ SG_ 2566867489 WarnPopStickStr "Warning Pop-up; Stick Steering";
CM_ SG_ 2566867489 PopCmdThwLvrErr "Pop-up Indication Command; Thumb Wheel Lever Error Pop-up";
CM_ SG_ 2566867489 HpApMd "HP/APMode";
CM_ SG_ 2566867489 GrLmt "VehicleStateSymbol;GearLimit";
CM_ SG_ 2566867489 BodyAng "BodyAngle";
CM_ SG_ 2566867489 WghIndSt "Weighing Indicator State";
CM_ SG_ 2566867489 BrkHold "VehicleStateSymbol;BrakeHold";
CM_ SG_ 2566867489 RtrdSt "RetarderState";
CM_ SG_ 2566867489 PilotCutOffSt "VehicleStateSymbol;PilotCutOffStatus";
CM_ SG_ 2566867489 BodySt "IndicatorSymbol;Bodystate";
CM_ SG_ 2566867489 VhcStGndSaw "VehicleStateSymbol;GroundSaw";
CM_ SG_ 2566867489 PopCmdJoyLvrNtrlErr "Pop-up Indication Command;  Joystick Lever Neutral Error Pop-up";
CM_ SG_ 2566867489 VhcStIntAxleLck "VehicleStateSymbol;InterAxleLock";
CM_ SG_ 2566867489 TrlHhFlowMd "TrackLoaderTypeGraphic;HighFlowMode";
CM_ SG_ 2566867489 ExcAutoBrkAntiFire "ExcavatorTypeSymbol;AutoBreaker,AntiBlankFireIndicator";
CM_ SG_ 2566867489 TrlIntLckOvrd "TrackLoaderTypeSymbol;InterlockOverride";
CM_ SG_ 2566867489 TrlCtrlFlow "TrackLoaderTypeSymbol;ContinuousFlowIndicator";
CM_ SG_ 2566867489 TrlSelfLv "TrackLoaderTypeSymbol;SelfLevelIndicator";
CM_ SG_ 2566867489 TrlHhFlow "TrackLoaderTypeSymbol;HighFlowIndicator";
CM_ BO_ 2566867745 "Gauge Data Group 4";
CM_ SG_ 2566867745 Acc3SsPress "ACC 3 Press. Sensor Press.";
CM_ SG_ 2566867745 Acc2SsPress "ACC 2 Press. Sensor Press.";
CM_ SG_ 2566867745 Acc1SsPress "ACC 1 Press. Sensor Press.";
CM_ SG_ 2566867745 EcoGgSt "EcoGaugeStatus";
CM_ SG_ 2566867745 EcoGgLv "EcoGaugeLevel";
CM_ BO_ 2566868257 "Mech. Engine TPS Calibration ";
CM_ SG_ 2566868257 MaximumEgSpd "MaximumRpm";
CM_ SG_ 2566868257 AutoCalbMd "AutoCalibrationMode";
CM_ SG_ 2566868257 CalbReq "RequestCalibration";
CM_ SG_ 2566868257 VhcStTpsCalb "VehicelState(2bit)-TPSCalibrationState";
CM_ SG_ 2566868257 MinimumEgSpd "MinimumRpm";
CM_ SG_ 2566868257 VhcStSsNrm "VehicelState(1bit)-SensorNormal";
CM_ SG_ 2566868257 VhcStEgIgn "VehicelState(1bit)-EngineStart";
CM_ SG_ 2566868257 VhcStPilotCutOff "VehicelState(1bit)-PilotCutOff";
CM_ SG_ 2566868257 VhcStEgCtrlDialMax "VehicelState(1bit)-EngineControlDialMax";
CM_ BO_ 2566868921 "Engine Dial Output";
CM_ SG_ 2566868921 DialStep "Dial Step";
CM_ SG_ 2566868921 DialPos "Dial Position";
CM_ BO_ 2566869025 "Jog Shuttle Output";
CM_ SG_ 2566869025 BlIntensity "Back Light Intensity";
CM_ SG_ 2566869025 EncoderDtDefineMax "Encoder Data, Define Maximum";
CM_ SG_ 2566869025 AirconShortcutBtn "Aircon Shortcut Button";
CM_ SG_ 2566869025 BzStopBtn "Buzzer Stop Button";
CM_ SG_ 2566869025 CallBtn "Call Button";
CM_ SG_ 2566869025 FavoriteBtn "Favorite Button";
CM_ SG_ 2566869025 DmbBtn "DMB Button";
CM_ SG_ 2566869025 WrkMdBtn "Work Mode Button";
CM_ SG_ 2566869025 AutoidleBzStopBtn "Autoidle/Buzzer Stop Button";
CM_ SG_ 2566869025 PwrMdBtn "Power Mode Button";
CM_ SG_ 2566869025 CamEscBtn "CAM/ESC Button";
CM_ SG_ 2566869025 RotatyPushBtn "Rotaty Push Button";
CM_ SG_ 2566869025 EncoderDt "Encoder Data";
CM_ BO_ 2566869158 "Jog Shuttle Output";
CM_ SG_ 2566869158 BlIntensity "Back Light Intensity";
CM_ SG_ 2566869158 EncoderDtDefineMax "Encoder Data, Define Maximum";
CM_ SG_ 2566869158 AirconShortcutBtn "Aircon Shortcut Button";
CM_ SG_ 2566869158 BzStopBtn "Buzzer Stop Button";
CM_ SG_ 2566869158 CallBtn "Call Button";
CM_ SG_ 2566869158 FavoriteBtn "Favorite Button";
CM_ SG_ 2566869158 DmbBtn "DMB Button";
CM_ SG_ 2566869158 WrkMdBtn "Work Mode Button";
CM_ SG_ 2566869158 AutoidleBzStopBtn "Autoidle/Buzzer Stop Button";
CM_ SG_ 2566869158 PwrMdBtn "Power Mode Button";
CM_ SG_ 2566869158 CamEscBtn "CAM/ESC Button";
CM_ SG_ 2566869158 RotatyPushBtn "Rotaty Push Button";
CM_ SG_ 2566869158 EncoderDt "Encoder Data";
CM_ BO_ 2365542696 "Jog Control Message";
CM_ SG_ 2365542696 PwforthisMsg "Passwordforthismessage";
CM_ SG_ 2365542696 EncoderDtDefineMax "EncoderData,DefineMaximum";
CM_ SG_ 2365542696 BrctRateforDtPck "BroadcastingrateforDataPackage";
CM_ SG_ 2365542696 PgnforDtPck "PGNforDataPackage";
CM_ SG_ 2365542696 SA "SourceAddress(CommandedAddress)";
CM_ SG_ 2365542696 BacklightIntensity "BacklightIntensity";
CM_ BO_ 2365542917 "ZFTC1";
CM_ BO_ 2365543201 "KeyPad Basic Indicate";
CM_ SG_ 2365543201 RvsFanLInd "Reverse Fan Left Indicator";
CM_ SG_ 2365543201 RvsFanRInd "Reverse Fan Right Indicator";
CM_ SG_ 2365543201 BoomLmpOprLInd "Boom Lamp Operate Left Indicator";
CM_ SG_ 2365543201 BoomLmpOprCtrInd "Boom Lamp Operate Center Indicator";
CM_ SG_ 2365543201 BoomLmpOprRInd "Boom Lamp Operate Right Indicator";
CM_ SG_ 2365543201 InfoLInd "Information Left Indicator";
CM_ SG_ 2365543201 InfoCtrInd "Information Center Indicator";
CM_ SG_ 2365543201 InfoRInd "Information Right Indicator";
CM_ SG_ 2365543201 EmgStrLInd "Emergency Steering Left Indicator";
CM_ SG_ 2365543201 EmgStrCtrInd "Emergency Steering Center Indicator";
CM_ SG_ 2365543201 EmgStrRInd "Emergency Steering Right Indicator";
CM_ SG_ 2365543201 LoadIsolationLInd "Load Isolation Left Indicator";
CM_ SG_ 2365543201 LoadIsolationCtrInd "Load Isolation Center Indicator";
CM_ SG_ 2365543201 LoadIsolationRInd "Load Isolation Right Indicator";
CM_ SG_ 2365543201 MirrorHtLInd "Mirror Heat Left Indicator";
CM_ SG_ 2365543201 MirrorHtCtrInd "Mirror Heat Center Indicator";
CM_ SG_ 2365543201 MirrorHtRInd "Mirror Heat Right Indicator";
CM_ SG_ 2365543201 RrWpWashLInd "Rear wiper & Washer Left Indicator";
CM_ SG_ 2365543201 RrWpWashCtrInd "Rear wiper & Washer Center Indicator";
CM_ SG_ 2365543201 RrWpWashRInd "Rear wiper & Washer Right Indicator";
CM_ SG_ 2365543201 BeaconLInd "Beacon Left Indicator";
CM_ SG_ 2365543201 BeaconCtrInd "Beacon Center Indicator";
CM_ SG_ 2365543201 BeaconRInd "Beacon Right Indicator";
CM_ SG_ 2365543201 RrWrkLmpLInd "Rear working Lamp  Left Indicator";
CM_ SG_ 2365543201 RrWrkLmpCtrInd "Rear working Lamp  Center Indicator";
CM_ SG_ 2365543201 RrWrkLmpRInd "Rear working Lamp  Right Indicator";
CM_ SG_ 2365543201 FrWrkLmpLInd "Front working Lamp Left Indicator ";
CM_ SG_ 2365543201 FrWrkLmpCentorInd "Front working Lamp Centor Indicator ";
CM_ SG_ 2365543201 FrWrkLmpRInd "Front working Lamp Right Indicator ";
CM_ SG_ 2365543201 HeadLmpLInd "Head Lamp Left Indicator ";
CM_ SG_ 2365543201 HeadLmpCtrInd "Head Lamp Center Indicator ";
CM_ SG_ 2365543201 HeadLmpRInd "Head Lamp Right Indicator ";
CM_ BO_ 2365543504 "KeyPad Signal";
CM_ SG_ 2365543504 TrkExpansionSig "Track Expansion Signal";
CM_ SG_ 2365543504 InterlockOverrideSig "Interlock Override Signal";
CM_ SG_ 2365543504 Aux8OprSig "Aux 8 Operate Signal";
CM_ SG_ 2365543504 Aux7OprSig "Aux 7 Operate Signal";
CM_ SG_ 2365543504 ContinuousFlowSig "Continuous Flow Signal";
CM_ SG_ 2365543504 RvsFanOprSig "Reverse FAN Operate Signal";
CM_ SG_ 2365543504 SelfLevelSig "Self Level Signal";
CM_ SG_ 2365543504 BoomLis "Boom LIS";
CM_ SG_ 2365543504 UpSig "Up Signal";
CM_ SG_ 2365543504 DnSig "Down Signal";
CM_ SG_ 2365543504 EnterSig "Enter Signal";
CM_ SG_ 2365543504 MenuSig "Menu Signal";
CM_ SG_ 2365543504 BzStopSig "Buzzer Stop Signal";
CM_ SG_ 2365543504 DmbEntertainSig "DMB Signal / Entertainment Signal";
CM_ SG_ 2365543504 CallSig "Call Signal";
CM_ SG_ 2365543504 RrMirrorHtSig "Rear Mirror Heater Signal";
CM_ SG_ 2365543504 FrWpOprSig "Front Wiper Operate Signal";
CM_ SG_ 2365543504 RrWpOprSig "Rear Wiper Operate Signal";
CM_ SG_ 2365543504 SideWpOprSig "Side Wiper Operate Signal";
CM_ SG_ 2365543504 FrWpWashOprSig "Front Wiper & Washer Operate Signal";
CM_ SG_ 2365543504 SideWpWashOprSig "Side Wiper & Washer Operate Signal";
CM_ SG_ 2365543504 AirCompOprSig "Air Comp.  Operate Signal";
CM_ SG_ 2365543504 TrvlSpdOprSig "Travel Speed Operate Signal";
CM_ SG_ 2365543504 AutoidleSig "Autoidle Signal";
CM_ SG_ 2365543504 CrabRoundSelSig "Crab / Round Select Signal";
CM_ SG_ 2365543504 TwoWhlFourWhlSelSig "2Wheel / 4Wheel Select Signal";
CM_ SG_ 2365543504 ThrottleLckUpOprSig "Throttle Lock Up Operate Signal";
CM_ SG_ 2365543504 TractionCtrlMdOprSig "Traction Control Mode Operate Signal";
CM_ SG_ 2365543504 VariableSpdDnOprSig "Variable Speed Down Operate Signal";
CM_ SG_ 2365543504 VariableSpdUpOprSig "Variable Speed Up Operate Signal";
CM_ SG_ 2365543504 MaxSpdUpOprSig "Max Speed Up Operate Signal";
CM_ SG_ 2365543504 MaxSpdDnOprSig "Max Speed Down Operate Signal";
CM_ SG_ 2365543504 TrqCvtLckUpOprSig "Torque Converter Lock Up Operate Signal";
CM_ SG_ 2365543504 ClutchCutOffOprSig "Clutch Cut Off Operate Signal";
CM_ SG_ 2365543504 TrmsMdSelOprSig "Transmission mode select Operate Signal";
CM_ SG_ 2365543504 ShakeControlSig "Shake Control Signal";
CM_ SG_ 2365543504 OutriggerAllSig "Outrigger All Signal";
CM_ SG_ 2365543504 OutriggerRrRSig "Outrigger Rear Right Signal";
CM_ SG_ 2365543504 OutriggerRrLSig "Outrigger Rear Left Signal";
CM_ SG_ 2365543504 OutriggerFrRSig "Outrigger Front Right Signal";
CM_ SG_ 2365543504 OutriggerFrLSig "Outrigger Front Left Signal";
CM_ SG_ 2365543504 DifLockEngagedOprSig "Differential Lock Engaged Operate Signal";
CM_ SG_ 2365543504 EmgStrOprSig "Emergency Steering Operate Signal";
CM_ SG_ 2365543504 BckDetentOprSig "Bucket Detent Operate Signal";
CM_ SG_ 2365543504 BoomDetentOprSig "Boom Detent Operate Signal";
CM_ SG_ 2365543504 LoadIsolationOprSig "Load Isolation Operate Signal";
CM_ SG_ 2365543504 MdSelOprSig "Mode Select Operate Signal";
CM_ SG_ 2365543504 MenuHelpOprSig "Menu,Help Operate Signal";
CM_ SG_ 2365543504 JoyStrSig "Joystick Steering Signal";
CM_ SG_ 2365543504 FineSwgSig "Fine Swing Signal";
CM_ SG_ 2365543504 TrailerHitchSig "Trailer Hitch Signal";
CM_ SG_ 2365543504 AutoDigBrkSig "Auto Digging Brake Signal";
CM_ SG_ 2365543504 BoomSwgSig "Boom Swing Signal";
CM_ SG_ 2365543504 WorkMdSig "Work Mode Signal";
CM_ SG_ 2365543504 PwrMdSig "Power Mode Signal";
CM_ SG_ 2365543504 TrvlAlmSig "Travel Alarm Signal";
CM_ SG_ 2365543504 MirrorHtOprSig "Mirror Heat Operate Signal";
CM_ SG_ 2365543504 RrWpWashOprSig "Rear wiper & Washer Operate Signal";
CM_ SG_ 2365543504 OwdOprSig "OWD Operate Signal";
CM_ SG_ 2365543504 BoomLmpOprSig "Boom Lamp Operate Signal";
CM_ SG_ 2365543504 BeaconLmpOprSig "Beacon Lamp Operate Signal";
CM_ SG_ 2365543504 RrWrkLmpOprSig "Rear Working Lamp Operate Signal";
CM_ SG_ 2365543504 FrWrkLmpOprSig "Front Working Lamp Operate Signal";
CM_ SG_ 2365543504 HeadLmpOprSig "Head Lamp Operate Signal";
CM_ BO_ 2365543713 "KeyPad Indicate 1";
CM_ SG_ 2365543713 SelfLvLInd "Self Level Left Indicator";
CM_ SG_ 2365543713 SelfLvCtrInd "Self Level Center Indicator";
CM_ SG_ 2365543713 SelfLvRInd "Self Level Right Indicator";
CM_ SG_ 2365543713 TrqCvtLckUpLInd "Torque Converter Lock Up Left Indicator";
CM_ SG_ 2365543713 TrqCvtLckUpCtrInd "Torque Converter Lock Up Center Indicator";
CM_ SG_ 2365543713 TrqCvtLckUpRInd "Torque Converter Lock Up Right Indicator";
CM_ SG_ 2365543713 ClutchCutOffLInd "Clutch Cut Off  Left Indicator";
CM_ SG_ 2365543713 ClutchCutOffCtrInd "Clutch Cut Off  Center Indicator";
CM_ SG_ 2365543713 ClutchCutOffRInd "Clutch Cut Off  Right Indicator";
CM_ SG_ 2365543713 TrmsMdSelLInd "Transmission mode select Left Indicator";
CM_ SG_ 2365543713 TrmsMdSelCtrInd "Transmission mode select Center Indicator";
CM_ SG_ 2365543713 TrmsMdSelRInd "Transmission mode select Right Indicator";
CM_ SG_ 2365543713 MaxSpdDnLInd "Max Speed Down Left Indicator";
CM_ SG_ 2365543713 MaxSpdDnCtrInd "Max Speed Down Center Indicator";
CM_ SG_ 2365543713 MaxSpdDnRInd "Max Speed Down Right Indicator";
CM_ SG_ 2365543713 MaxSpdUpLInd "Max Speed Up Left Indicator";
CM_ SG_ 2365543713 MaxSpdUpCtrInd "Max Speed Up Center Indicator";
CM_ SG_ 2365543713 MaxSpdUpRInd "Max Speed Up Right Indicator";
CM_ SG_ 2365543713 BckDetentLInd "Bucket Detent Left Indicator";
CM_ SG_ 2365543713 BckDetentCtrInd "Bucket Detent Center Indicator";
CM_ SG_ 2365543713 BckDetentRInd "Bucket Detent Right Indicator";
CM_ SG_ 2365543713 BoomDetentLInd "Boom Detent Left Indicator";
CM_ SG_ 2365543713 BoomDetentCtrInd "Boom Detent Center Indicator";
CM_ SG_ 2365543713 BoomDetentRInd "Boom Detent Right Indicator";
CM_ SG_ 2365543713 DifLckEngagedLInd "Differential Lock Engaged Left Indicator";
CM_ SG_ 2365543713 DifLckEngagedCtrInd "Differential Lock Engaged Center Indicator";
CM_ SG_ 2365543713 DifLckEngagedRInd "Differential Lock Engaged Right Indicator";
CM_ SG_ 2365543713 MdSelLInd "Mode Select Left  Indicator";
CM_ SG_ 2365543713 MdSelCtrInd "Mode Select Center  Indicator";
CM_ SG_ 2365543713 MdSelRInd "Mode Select Right  Indicator";
CM_ BO_ 2365543969 "KeyPad Machine Indicate 1";
CM_ SG_ 2365543969 HyhLckCtrInd "Hydraulic Lock Center Indicator";
CM_ SG_ 2365543969 AutoidleLInd "Autoidle Left Indicator";
CM_ SG_ 2365543969 AutoidleCtrInd "Autoidle Center Indicator";
CM_ SG_ 2365543969 AutoidleRInd "Autoidle Right Indicator";
CM_ SG_ 2365543969 JoyStrLInd "Joystick Steering Left Indicator";
CM_ SG_ 2365543969 JoyStrCtrInd "Joystick Steering Center Indicator";
CM_ SG_ 2365543969 JoyStrRInd "Joystick Steering Right Indicator";
CM_ SG_ 2365543969 FineSwgLInd "Fine Swing Left Indicator";
CM_ SG_ 2365543969 FineSwgCtrInd "Fine Swing Center Indicator";
CM_ SG_ 2365543969 FineSwgRInd "Fine Swing Right Indicator";
CM_ SG_ 2365543969 TrailerHitchBrkLInd "Trailer Hitch Brake  Left Indicator";
CM_ SG_ 2365543969 TrailerHitchBrkCtrInd "Trailer Hitch Brake Center Indicator";
CM_ SG_ 2365543969 TrailerHitchRInd "Trailer Hitch  Right Indicator";
CM_ SG_ 2365543969 AutoDigBrkLInd "Auto Digging Brake  Left Indicator";
CM_ SG_ 2365543969 AutoDigBrkCtrInd "Auto Digging Brake Center Indicator";
CM_ SG_ 2365543969 AutoDigBrkRInd "Auto Digging Brake  Right Indicator";
CM_ SG_ 2365543969 BoomSwgMdLInd "Boom Swing Mode Left Indicator";
CM_ SG_ 2365543969 BoomSwgMdCtrInd "Boom Swing Mode Center Indicator";
CM_ SG_ 2365543969 BoomSwgMdRInd "Boom Swing Mode Right Indicator";
CM_ SG_ 2365543969 WrkMdLInd "Work Mode Left Indicator";
CM_ SG_ 2365543969 WrkMdCtrInd "Work Mode Center Indicator";
CM_ SG_ 2365543969 WrkMdRInd "Work Mode Right Indicator";
CM_ SG_ 2365543969 PwrMdLInd "Power Mode Left Indicator";
CM_ SG_ 2365543969 PwrMdCtrInd "Power Mode Center Indicator";
CM_ SG_ 2365543969 PwrMdRInd "Power Mode Right Indicator";
CM_ SG_ 2365543969 TrvlAlmLInd "Travel Alarm Left Indicator";
CM_ SG_ 2365543969 TrvlAlmCtrInd "Travel Alarm Center Indicator";
CM_ SG_ 2365543969 TrvlAlmRInd "Travel Alarm Right Indicator";
CM_ SG_ 2365543969 OwdLInd "OWD Left Indicator";
CM_ SG_ 2365543969 OwdCtrInd "OWD Center Indicator";
CM_ SG_ 2365543969 OwdRInd "OWD Right Indicator";
CM_ BO_ 2365544225 "KeyPad Machine Indicate 2";
CM_ SG_ 2365544225 SwgLckLInd "Swing Lock Left Indicator";
CM_ SG_ 2365544225 SwgLckCtrInd "Swing Lock Center Indicator";
CM_ SG_ 2365544225 SwgLckRInd "Swing Lock Right Indicator";
CM_ SG_ 2365544225 BoomFltLInd "Boom Floating Left Indicator";
CM_ SG_ 2365544225 BoomFltCtrInd "Boom Floating Center Indicator";
CM_ SG_ 2365544225 BoomFltRInd "Boom Floating Right Indicator";
CM_ SG_ 2365544225 BoomLisLInd "Boom LIS Left Indicator";
CM_ SG_ 2365544225 BoomLisCtrInd "Boom LIS Center Indicator";
CM_ SG_ 2365544225 BoomLisRInd "Boom LIS Right Indicator";
CM_ SG_ 2365544225 CrabRoundSelLInd "Crab / Round Select Left Indicator";
CM_ SG_ 2365544225 CrabRoundSelCtrInd "Crab / Round Select Center Indicator";
CM_ SG_ 2365544225 CrabRoundSelRInd "Crab / Round Select Right Indicator";
CM_ SG_ 2365544225 TwoWhlFourWhlSelLInd "2Wheel / 4Wheel Select Left Indicator";
CM_ SG_ 2365544225 TwoWhlFourWhlSelCtrInd "2Wheel / 4Wheel Select Center Indicator";
CM_ SG_ 2365544225 TwoWhlFourWhlSelRInd "2Wheel / 4Wheel Select Right Indicator";
CM_ SG_ 2365544225 OtrgAllLInd "Outrigger All Left Indicator";
CM_ SG_ 2365544225 OtrgAllCtrInd "Outrigger All Center Indicator";
CM_ SG_ 2365544225 OtrgAllRInd "Outrigger All Right Indicator";
CM_ SG_ 2365544225 OtrgRrRLInd "Outrigger Rear Right Left Indicator";
CM_ SG_ 2365544225 OtrgRrRCtrInd "Outrigger Rear Right Center Indicator";
CM_ SG_ 2365544225 OtrgRrRRInd "Outrigger Rear Right Right Indicator";
CM_ SG_ 2365544225 OtrgRrLLInd "Outrigger Rear Left  Left Indicator";
CM_ SG_ 2365544225 OtrgRrLCtrInd "Outrigger Rear Left Center Indicator";
CM_ SG_ 2365544225 OtrgRrLRInd "Outrigger Rear Left  Right Indicator";
CM_ SG_ 2365544225 OtrgFrRLInd "Outrigger Front Right Left Indicator";
CM_ SG_ 2365544225 OtrgFrRCtrInd "Outrigger Front Right Center Indicator";
CM_ SG_ 2365544225 OtrgFrRRInd "Outrigger Front Right Right Indicator";
CM_ SG_ 2365544225 OtrgFrLLInd "Outrigger Front Left Left Indicator";
CM_ SG_ 2365544225 OtrgFrLCtrInd "Outrigger Front Left Center Indicator";
CM_ SG_ 2365544225 OtrgFrLRInd "Outrigger Front Left Right Indicator";
CM_ BO_ 2365544481 "KeyPad Indicate 2";
CM_ SG_ 2365544481 Aux8LInd "Aux8 Left Indicator";
CM_ SG_ 2365544481 Aux8CtrInd "Aux8 Center Indicator";
CM_ SG_ 2365544481 Aux8RInd "Aux8 Right Indicator";
CM_ SG_ 2365544481 Aux7LInd "Aux7 Left Indicator";
CM_ SG_ 2365544481 Aux7CtrInd "Aux7 Center Indicator";
CM_ SG_ 2365544481 Aux7RInd "Aux7 Right Indicator";
CM_ SG_ 2365544481 ContinuousFlowLInd "Continuous Flow Left Indicator";
CM_ SG_ 2365544481 ContinuousFlowCtrInd "Continuous Flow Center Indicator";
CM_ SG_ 2365544481 ContinuousFlowRInd "Continuous Flow Right Indicator";
CM_ SG_ 2365544481 InterlockOverrideLInd "Interlock Override Left Indicator";
CM_ SG_ 2365544481 InterlockOverrideCtrInd "Interlock Override Center Indicator";
CM_ SG_ 2365544481 InterlockOverrideRInd "Interlock Override Right Indicator";
CM_ SG_ 2365544481 ShakeCtrlLInd "Shake Control Left Indicator";
CM_ SG_ 2365544481 ShakeCtrlCtrInd "Shake Control Center Indicator";
CM_ SG_ 2365544481 ShakeCtrlRInd "Shake Control Right Indicator";
CM_ SG_ 2365544481 ThrottleLckUpLInd "Throttle Lock Up Left Indicator";
CM_ SG_ 2365544481 ThrottleLckUpCtrInd "Throttle Lock Up Center Indicator";
CM_ SG_ 2365544481 ThrottleLckUpRInd "Throttle Lock Up Right Indicator";
CM_ SG_ 2365544481 TractionCtrlMdLInd "Traction Control Mode Left Indicator";
CM_ SG_ 2365544481 TractionCtrlMdCtrInd "Traction Control Mode Center Indicator";
CM_ SG_ 2365544481 TractionCtrlMdRInd "Traction Control Mode Right Indicator";
CM_ SG_ 2365544481 VariableSpdDnLInd "Variable Speed Down Left Indicator";
CM_ SG_ 2365544481 VariableSpdDnCtrInd "Variable Speed Down Center Indicator";
CM_ SG_ 2365544481 VariableSpdDnRInd "Variable Speed Down Right Indicator";
CM_ SG_ 2365544481 VariableSpdUpLInd "Variable Speed Up Left Indicator";
CM_ SG_ 2365544481 VariableSpdUpCtrInd "Variable Speed Up Center Indicator";
CM_ SG_ 2365544481 VariableSpdUpRInd "Variable Speed Up Right Indicator";
CM_ BO_ 2365544737 "KeyPad Indicate 3";
CM_ SG_ 2365544737 TrkExpansionLInd "Track Expansion Left Indicator";
CM_ SG_ 2365544737 TrkExpansionCtrInd "Track Expansion Center Indicator";
CM_ SG_ 2365544737 TrkExpansionRInd "Track Expansion Right Indicator";
CM_ SG_ 2365544737 FrWpLInd "Front Wiper Left Indicator";
CM_ SG_ 2365544737 FrWpCtrInd "Front Wiper Center Indicator";
CM_ SG_ 2365544737 FrWpRInd "Front Wiper Right Indicator";
CM_ SG_ 2365544737 RrWpLInd "Rear Wiper Left Indicator";
CM_ SG_ 2365544737 RrWpCtrInd "Rear Wiper Center Indicator";
CM_ SG_ 2365544737 RrWpRInd "Rear Wiper Right Indicator";
CM_ SG_ 2365544737 SideWpLInd "Side Wiper Left Indicator";
CM_ SG_ 2365544737 SideWpCtrInd "Side Wiper Center Indicator";
CM_ SG_ 2365544737 SideWpRInd "Side Wiper Right Indicator";
CM_ SG_ 2365544737 FrWpWashLInd "Front Wiper & Washer Left Indicator";
CM_ SG_ 2365544737 FrWpWashCtrInd "Front Wiper & Washer Center Indicator";
CM_ SG_ 2365544737 FrWpWashRInd "Front Wiper & Washer Right Indicator";
CM_ SG_ 2365544737 SideWpWashLInd "Side Wiper & Washer Left Indicator";
CM_ SG_ 2365544737 SideWpWashCtrInd "Side Wiper & Washer Center Indicator";
CM_ SG_ 2365544737 SideWpWashRInd "Side Wiper & Washer Right Indicator";
CM_ SG_ 2365544737 RrMirrorHtLInd "Rear Mirror Heater Left Indicator";
CM_ SG_ 2365544737 RrMirrorHtCtrInd "Rear Mirror Heater Center Indicator";
CM_ SG_ 2365544737 RrMirrorHtRInd "Rear Mirror Heater Right Indicator";
CM_ SG_ 2365544737 AirCompLInd "Air Comp. Left Indicator";
CM_ SG_ 2365544737 AirCompCtrInd "Air Comp. Center Indicator";
CM_ SG_ 2365544737 AirCompRInd "Air Comp. Right Indicator";
CM_ SG_ 2365544737 TrvlSpdLInd "Travel Speed Left Indicator";
CM_ SG_ 2365544737 TrvlSpdCtrInd "Travel Speed Center Indicator";
CM_ SG_ 2365544737 TrvlSpdRInd "Travel Speed Right Indicator";
CM_ SG_ 2365544737 BzStopLInd "Buzzer Stop Left Indicator";
CM_ SG_ 2365544737 BzStopCtrInd "Buzzer Stop Center Indicator";
CM_ SG_ 2365544737 BzStopRInd "Buzzer Stop Right Indicator";
CM_ BO_ 2566871629 "Horn Command";
CM_ SG_ 2566871629 HornSwIn "Horn Switch Input";
CM_ BO_ 2566872001 "Accelleration Sensor Information";
CM_ SG_ 2566872001 AccRate "Acceleration Rate";
CM_ BO_ 2566872002 "Accelleration Sensor Information";
CM_ SG_ 2566872002 AccRate "Acceleration Rate";
CM_ BO_ 2566872003 "Accelleration Sensor Information";
CM_ SG_ 2566872003 AccRate "Acceleration Rate";
CM_ BO_ 2566872004 "Accelleration Sensor Information";
CM_ SG_ 2566872004 AccRate "Acceleration Rate";
CM_ BO_ 2566872005 "Accelleration Sensor Information";
CM_ SG_ 2566872005 AccRate "Acceleration Rate";
CM_ BO_ 2365545552 "KeyPad Signal 2";
CM_ SG_ 2365545552 BoomFltOprSig "Boom Floating Operate Siganl";
CM_ SG_ 2365545552 SwgLckOprSig "Swing Lock Operate Signal";
CM_ SG_ 2365545552 HpApMdSelOprSig "HP/AP Mode Select Operate Signal";
CM_ BO_ 2365545761 "KeyPad Indicate 4";
CM_ SG_ 2365545761 OutTrgDzShortcutLInd "Outrigger/Dozer Shortcut Left Indicator";
CM_ SG_ 2365545761 OutTrgDzShortcutCtrInd "Outrigger/Dozer Shortcut Center Indicator";
CM_ SG_ 2365545761 OutTrgDzShortcutRInd "Outrigger/Dozer Shortcut Right Indicator";
CM_ SG_ 2365545761 BoomFltLInd "Boom Floating Left Indicator";
CM_ SG_ 2365545761 BoomFltCtrInd "Boom Floating Center Indicator";
CM_ SG_ 2365545761 BoomFltRInd "Boom Floating Right Indicator";
CM_ SG_ 2365545761 SwgLckLInd "Swing Lock Left Indicator";
CM_ SG_ 2365545761 SwgLckCtrInd "Swing Lock Center Indicator";
CM_ SG_ 2365545761 SwgLckRInd "Swing Lock Right Indicator";
CM_ SG_ 2365545761 HpApMdLInd "HP/AP Mode Left Indicator";
CM_ SG_ 2365545761 HpApMdCtrInd "HP/AP Mode Center Indicator";
CM_ SG_ 2365545761 HpApMdRInd "HP/AP Mode Right Indicator";
CM_ BO_ 2566873377 "ACU Control";
CM_ SG_ 2566873377 LowOutReq8 "LowOutputrequest#8";
CM_ SG_ 2566873377 LowOutReq7 "LowOutputrequest#7";
CM_ SG_ 2566873377 LowOutReq6 "LowOutputrequest#6";
CM_ SG_ 2566873377 LowOutReq5 "LowOutputrequest#5";
CM_ SG_ 2566873377 LowOutReq4 "LowOutputrequest#4";
CM_ SG_ 2566873377 LowOutReq3 "LowOutputrequest#3";
CM_ SG_ 2566873377 LowOutReq2 "LowOutputrequest#2";
CM_ SG_ 2566873377 LowOutReq1 "LowOutputrequest#1";
CM_ SG_ 2566873377 OutReq15 "Outputrequest#15";
CM_ SG_ 2566873377 OutReq14 "Outputrequest#14";
CM_ SG_ 2566873377 OutReq13 "Outputrequest#13";
CM_ SG_ 2566873377 OutReq12 "Outputrequest#12";
CM_ SG_ 2566873377 OutReq11 "Outputrequest#11";
CM_ SG_ 2566873377 OutReq10 "Outputrequest#10";
CM_ SG_ 2566873377 OutReq9 "Outputrequest#9";
CM_ SG_ 2566873377 OutReq8 "Outputrequest#8";
CM_ SG_ 2566873377 OutReq7 "Outputrequest#7";
CM_ SG_ 2566873377 OutReq6 "Outputrequest#6";
CM_ SG_ 2566873377 OutReq5 "Outputrequest#5";
CM_ SG_ 2566873377 OutReq4 "Outputrequest#4";
CM_ SG_ 2566873377 OutReq3 "Outputrequest#3";
CM_ SG_ 2566873377 OutReq2 "Outputrequest#2";
CM_ SG_ 2566873377 OutReq1 "Outputrequest#1";
CM_ BO_ 2566873630 "ACU Feedback1";
CM_ SG_ 2566873630 OutFdbkCur8 "OutputFeedbackCurrent#8";
CM_ SG_ 2566873630 OutFdbkCur7 "OutputFeedbackCurrent#7";
CM_ SG_ 2566873630 OutFdbkCur6 "OutputFeedbackCurrent#6";
CM_ SG_ 2566873630 OutFdbkCur5 "OutputFeedbackCurrent#5";
CM_ SG_ 2566873630 OutFdbkCur4 "OutputFeedbackCurrent#4";
CM_ SG_ 2566873630 OutFdbkCur3 "OutputFeedbackCurrent#3";
CM_ SG_ 2566873630 OutFdbkCur2 "OutputFeedbackCurrent#2";
CM_ SG_ 2566873630 OutFdbkCur1 "OutputFeedbackCurrent#1";
CM_ BO_ 2566873767 "ACU Feedback1";
CM_ SG_ 2566873767 OutFdbkCur8 "OutputFeedbackCurrent#8";
CM_ SG_ 2566873767 OutFdbkCur7 "OutputFeedbackCurrent#7";
CM_ SG_ 2566873767 OutFdbkCur6 "OutputFeedbackCurrent#6";
CM_ SG_ 2566873767 OutFdbkCur5 "OutputFeedbackCurrent#5";
CM_ SG_ 2566873767 OutFdbkCur4 "OutputFeedbackCurrent#4";
CM_ SG_ 2566873767 OutFdbkCur3 "OutputFeedbackCurrent#3";
CM_ SG_ 2566873767 OutFdbkCur2 "OutputFeedbackCurrent#2";
CM_ SG_ 2566873767 OutFdbkCur1 "OutputFeedbackCurrent#1";
CM_ BO_ 2566873886 "ACU Feedback2";
CM_ SG_ 2566873886 ErrorFlag "ErrorFlag";
CM_ SG_ 2566873886 VltIn2 "VoltageInput#2";
CM_ SG_ 2566873886 VltIn1 "VoltageInput#1";
CM_ SG_ 2566873886 OutFdbkCur13 "OutputFeedbackCurrent#13";
CM_ SG_ 2566873886 OutFdbkCur12 "OutputFeedbackCurrent#12";
CM_ SG_ 2566873886 OutFdbkCur11 "OutputFeedbackCurrent#11";
CM_ SG_ 2566873886 OutFdbkCur10 "OutputFeedbackCurrent#10";
CM_ SG_ 2566873886 OutFdbkCur9 "OutputFeedbackCurrent#9";
CM_ BO_ 2566874654 "ACU Feedback3";
CM_ SG_ 2566874654 OutFdbkActvLowCur8 "OutputFeedbackActiveLowCurrent#8";
CM_ SG_ 2566874654 OutFdbkActvLowCur7 "OutputFeedbackActiveLowCurrent#7";
CM_ SG_ 2566874654 OutFdbkActvLowCur6 "OutputFeedbackActiveLowCurrent#6";
CM_ SG_ 2566874654 OutFdbkActvLowCur5 "OutputFeedbackActiveLowCurrent#5";
CM_ SG_ 2566874654 OutFdbkActvLowCur4 "OutputFeedbackActiveLowCurrent#4";
CM_ SG_ 2566874654 OutFdbkActvLowCur3 "OutputFeedbackActiveLowCurrent#3";
CM_ SG_ 2566874654 OutFdbkActvLowCur2 "OutputFeedbackActiveLowCurrent#2";
CM_ SG_ 2566874654 OutFdbkActvLowCur1 "OutputFeedbackActiveLowCurrent#1";
CM_ SG_ 2566874654 OutFdbkActvHighCur15 "OutputFeedbackActiveHighCurrent#15";
CM_ SG_ 2566874654 OutFdbkActvHighCur14 "OutputFeedbackActiveHighCurrent#14";
CM_ SG_ 2566874654 OutFdbkActvHighCur13 "OutputFeedbackActiveHighCurrent#13";
CM_ SG_ 2566874654 OutFdbkActvHighCur12 "OutputFeedbackActiveHighCurrent#12";
CM_ SG_ 2566874654 OutFdbkActvHighCur11 "OutputFeedbackActiveHighCurrent#11";
CM_ SG_ 2566874654 OutFdbkActvHighCur10 "OutputFeedbackActiveHighCurrent#10";
CM_ SG_ 2566874654 OutFdbkActvHighCur9 "OutputFeedbackActiveHighCurrent#9";
CM_ SG_ 2566874654 OutFdbkActvHighCur8 "OutputFeedbackActiveHighCurrent#8";
CM_ SG_ 2566874654 OutFdbkActvHighCur7 "OutputFeedbackActiveHighCurrent#7";
CM_ SG_ 2566874654 OutFdbkActvHighCur6 "OutputFeedbackActiveHighCurrent#6";
CM_ SG_ 2566874654 OutFdbkActvHighCur5 "OutputFeedbackActiveHighCurrent#5";
CM_ SG_ 2566874654 OutFdbkActvHighCur4 "OutputFeedbackActiveHighCurrent#4";
CM_ SG_ 2566874654 OutFdbkActvHighCur3 "OutputFeedbackActiveHighCurrent#3";
CM_ SG_ 2566874654 OutFdbkActvHighCur2 "OutputFeedbackActiveHighCurrent#2";
CM_ SG_ 2566874654 OutFdbkActvHighCur1 "OutputFeedbackActiveHighCurrent#1";
CM_ BO_ 2566874910 "ACU Feedback4";
CM_ SG_ 2566874910 InVlt12 "InputVoltage#12";
CM_ SG_ 2566874910 InVlt11 "InputVoltage#11";
CM_ SG_ 2566874910 InVlt10 "InputVoltage#10";
CM_ SG_ 2566874910 InVlt9 "InputVoltage#9";
CM_ SG_ 2566874910 InVlt8 "InputVoltage#8";
CM_ SG_ 2566874910 InVlt7 "InputVoltage#7";
CM_ SG_ 2566874910 InVlt6 "InputVoltage#6";
CM_ SG_ 2566874910 InVlt5 "InputVoltage#5";
CM_ SG_ 2566874910 InVlt4 "InputVoltage#4";
CM_ SG_ 2566874910 InVlt3 "InputVoltage#3";
CM_ SG_ 2566874910 InVlt2 "InputVoltage#2";
CM_ SG_ 2566874910 InVlt1 "InputVoltage#1";
CM_ BO_ 2566875297 "KeyPad AirCon Command";
CM_ SG_ 2566875297 HvacOffSel "HVAC Off Select";
CM_ SG_ 2566875297 BlowerDnSig "Blower Down signal";
CM_ SG_ 2566875297 BlowerUpSig "Blower Up signal";
CM_ SG_ 2566875297 DefMdSel "DEF Mode select";
CM_ SG_ 2566875297 BlowMdSelSig "Blow Mode Select signal ";
CM_ SG_ 2566875297 MnAutoMdSel "Manual / Auto Mode Select";
CM_ SG_ 2566875297 TmpDnSig "Temperature Down signal";
CM_ SG_ 2566875297 TmpUpSig "Temperature Up signal";
CM_ SG_ 2566875297 OuttakeIntakeMdSel "Outtake/Intake Mode select";
CM_ SG_ 2566875297 AcMdSel "A/C Mode select";
CM_ BO_ 2566875422 "ACU Feedback5";
CM_ SG_ 2566875422 OutFdbkCur12 "OutputFeedbackCurrent#12";
CM_ SG_ 2566875422 OutFdbkCur11 "OutputFeedbackCurrent#11";
CM_ SG_ 2566875422 OutFdbkCur10 "OutputFeedbackCurrent#10";
CM_ SG_ 2566875422 OutFdbkCur9 "OutputFeedbackCurrent#9";
CM_ BO_ 2566875559 "ACU Feedback5";
CM_ SG_ 2566875559 OutFdbkCur12 "OutputFeedbackCurrent#12";
CM_ SG_ 2566875559 OutFdbkCur11 "OutputFeedbackCurrent#11";
CM_ SG_ 2566875559 OutFdbkCur10 "OutputFeedbackCurrent#10";
CM_ SG_ 2566875559 OutFdbkCur9 "OutputFeedbackCurrent#9";
CM_ BO_ 2566875678 "ACU Feedback6";
CM_ SG_ 2566875678 MiniRly30AFuse2St "MiniRelay30AFuse#2Status";
CM_ SG_ 2566875678 MiniRly30AFuse1St "MiniRelay30AFuse#1Status";
CM_ SG_ 2566875678 MicroRly20AFuse5St "MicroRelay20AFuse#5Status";
CM_ SG_ 2566875678 MicroRly20AFuse4St "MicroRelay20AFuse#4Status";
CM_ SG_ 2566875678 MicroRly20AFuse3St "MicroRelay20AFuse#3Status";
CM_ SG_ 2566875678 MicroRly20AFuse2St "MicroRelay20AFuse#2Status";
CM_ SG_ 2566875678 MicroRly20AFuse1St "MicroRelay20AFuse#1Status";
CM_ SG_ 2566875678 KeyOn30AFuse5St "KeyOn30AFuse#5Status";
CM_ SG_ 2566875678 KeyOn30AFuse4St "KeyOn30AFuse#4Status";
CM_ SG_ 2566875678 KeyOn30AFuse3St "KeyOn30AFuse#3Status";
CM_ SG_ 2566875678 KeyOn30AFuse2St "KeyOn30AFuse#2Status";
CM_ SG_ 2566875678 KeyOn30AFuse1St "KeyOn30AFuse#1Status";
CM_ SG_ 2566875678 KeyOn20AFuse10St "KeyOn20AFuse#10Status";
CM_ SG_ 2566875678 KeyOn20AFuse9St "KeyOn20AFuse#9Status";
CM_ SG_ 2566875678 KeyOn20AFuse8St "KeyOn20AFuse#8Status";
CM_ SG_ 2566875678 KeyOn20AFuse7St "KeyOn20AFuse#7Status";
CM_ SG_ 2566875678 KeyOn20AFuse6St "KeyOn20AFuse#6Status";
CM_ SG_ 2566875678 KeyOn20AFuse5St "KeyOn20AFuse#5Status";
CM_ SG_ 2566875678 KeyOn20AFuse4St "KeyOn20AFuse#4Status";
CM_ SG_ 2566875678 KeyOn20AFuse3St "KeyOn20AFuse#3Status";
CM_ SG_ 2566875678 KeyOn20AFuse2St "KeyOn20AFuse#2Status";
CM_ SG_ 2566875678 KeyOn20AFuse1St "KeyOn20AFuse#1Status";
CM_ SG_ 2566875678 KeyOn10AFuse5St "KeyOn10AFuse#5Status";
CM_ SG_ 2566875678 KeyOn10AFuse4St "KeyOn10AFuse#4Status";
CM_ SG_ 2566875678 KeyOn10AFuse3St "KeyOn10AFuse#3Status";
CM_ SG_ 2566875678 KeyOn10AFuse2St "KeyOn10AFuse#2Status";
CM_ SG_ 2566875678 KeyOn10AFuse1St "KeyOn10AFuse#1Status";
CM_ SG_ 2566875678 KeyOn5AFuse15St "KeyOn5AFuse#15Status";
CM_ SG_ 2566875678 KeyOn5AFuse14St "KeyOn5AFuse#14Status";
CM_ SG_ 2566875678 KeyOn5AFuse13St "KeyOn5AFuse#13Status";
CM_ SG_ 2566875678 KeyOn5AFuse12St "KeyOn5AFuse#12Status";
CM_ SG_ 2566875678 KeyOn5AFuse11St "KeyOn5AFuse#11Status";
CM_ SG_ 2566875678 KeyOn5AFuse10St "KeyOn5AFuse#10Status";
CM_ SG_ 2566875678 KeyOn5AFuse9St "KeyOn5AFuse#9Status";
CM_ SG_ 2566875678 KeyOn5AFuse8St "KeyOn5AFuse#8Status";
CM_ SG_ 2566875678 KeyOn5AFuse7St "KeyOn5AFuse#7Status";
CM_ SG_ 2566875678 KeyOn5AFuse6St "KeyOn5AFuse#6Status";
CM_ SG_ 2566875678 KeyOn5AFuse5St "KeyOn5AFuse#5Status";
CM_ SG_ 2566875678 KeyOn5AFuse4St "KeyOn5AFuse#4Status";
CM_ SG_ 2566875678 KeyOn5AFuse3St "KeyOn5AFuse#3Status";
CM_ SG_ 2566875678 KeyOn5AFuse2St "KeyOn5AFuse#2Status";
CM_ SG_ 2566875678 KeyOn5AFuse1St "KeyOn5AFuse#1Status";
CM_ SG_ 2566875678 BPlus30AFuse5St "B+30AFuse#5Status";
CM_ SG_ 2566875678 BPlus30AFuse4St "B+30AFuse#4Status";
CM_ SG_ 2566875678 BPlus30AFuse3St "B+30AFuse#3Status";
CM_ SG_ 2566875678 BPlus30AFuse2St "B+30AFuse#2Status";
CM_ SG_ 2566875678 BPlus30AFuse1St "B+30AFuse#1Status";
CM_ SG_ 2566875678 BPlus20AFuse5St "B+20AFuse#5Status";
CM_ SG_ 2566875678 BPlus20AFuse4St "B+20AFuse#4Status";
CM_ SG_ 2566875678 BPlus20AFuse3St "B+20AFuse#3Status";
CM_ SG_ 2566875678 BPlus20AFuse2St "B+20AFuse#2Status";
CM_ SG_ 2566875678 BPlus20AFuse1St "B+20AFuse#1Status";
CM_ SG_ 2566875678 BPlus5AFuse10St "B+5AFuse#10Status";
CM_ SG_ 2566875678 BPlus5AFuse9St "B+5AFuse#9Status";
CM_ SG_ 2566875678 BPlus5AFuse8St "B+5AFuse#8Status";
CM_ SG_ 2566875678 BPlus5AFuse7St "B+5AFuse#7Status";
CM_ SG_ 2566875678 BPlus5AFuse6St "B+5AFuse#6Status";
CM_ SG_ 2566875678 BPlus5AFuse5St "B+5AFuse#5Status";
CM_ SG_ 2566875678 BPlus5AFuse4St "B+5AFuse#4Status";
CM_ SG_ 2566875678 BPlus5AFuse3St "B+5AFuse#3Status";
CM_ SG_ 2566875678 BPlus5AFuse2St "B+5AFuse#2Status";
CM_ SG_ 2566875678 BPlus5AFuse1St "B+5AFuse#1Status";
CM_ SG_ 2566875678 IpsTotalCur "IPSTotalCurrent";
CM_ SG_ 2566875678 MINIFuse2Cur "MINIFuse#2Current";
CM_ SG_ 2566875678 MINIFuse1Cur "MINIFuse#1Current";
CM_ SG_ 2566875678 MicroFuse5Cur "MicroFuse#5Current";
CM_ SG_ 2566875678 MicroFuse4Cur "MicroFuse#4Current";
CM_ SG_ 2566875678 MicroFuse3Cur "MicroFuse#3Current";
CM_ SG_ 2566875678 MicroFuse2Cur "MicroFuse#2Current";
CM_ SG_ 2566875678 MicroFuse1Cur "MicroFuse#1Current";
CM_ SG_ 2566875678 KeyOnPwrCur "KEYONPowerCurrent";
CM_ SG_ 2566875678 BPlusPwrCur "B+PowerCurrent";
CM_ BO_ 2566875815 "ACU Feedback6";
CM_ SG_ 2566875815 MiniRly30AFuse2St "MiniRelay30AFuse#2Status";
CM_ SG_ 2566875815 MiniRly30AFuse1St "MiniRelay30AFuse#1Status";
CM_ SG_ 2566875815 MicroRly20AFuse5St "MicroRelay20AFuse#5Status";
CM_ SG_ 2566875815 MicroRly20AFuse4St "MicroRelay20AFuse#4Status";
CM_ SG_ 2566875815 MicroRly20AFuse3St "MicroRelay20AFuse#3Status";
CM_ SG_ 2566875815 MicroRly20AFuse2St "MicroRelay20AFuse#2Status";
CM_ SG_ 2566875815 MicroRly20AFuse1St "MicroRelay20AFuse#1Status";
CM_ SG_ 2566875815 KeyOn30AFuse5St "KeyOn30AFuse#5Status";
CM_ SG_ 2566875815 KeyOn30AFuse4St "KeyOn30AFuse#4Status";
CM_ SG_ 2566875815 KeyOn30AFuse3St "KeyOn30AFuse#3Status";
CM_ SG_ 2566875815 KeyOn30AFuse2St "KeyOn30AFuse#2Status";
CM_ SG_ 2566875815 KeyOn30AFuse1St "KeyOn30AFuse#1Status";
CM_ SG_ 2566875815 KeyOn20AFuse10St "KeyOn20AFuse#10Status";
CM_ SG_ 2566875815 KeyOn20AFuse9St "KeyOn20AFuse#9Status";
CM_ SG_ 2566875815 KeyOn20AFuse8St "KeyOn20AFuse#8Status";
CM_ SG_ 2566875815 KeyOn20AFuse7St "KeyOn20AFuse#7Status";
CM_ SG_ 2566875815 KeyOn20AFuse6St "KeyOn20AFuse#6Status";
CM_ SG_ 2566875815 KeyOn20AFuse5St "KeyOn20AFuse#5Status";
CM_ SG_ 2566875815 KeyOn20AFuse4St "KeyOn20AFuse#4Status";
CM_ SG_ 2566875815 KeyOn20AFuse3St "KeyOn20AFuse#3Status";
CM_ SG_ 2566875815 KeyOn20AFuse2St "KeyOn20AFuse#2Status";
CM_ SG_ 2566875815 KeyOn20AFuse1St "KeyOn20AFuse#1Status";
CM_ SG_ 2566875815 KeyOn10AFuse5St "KeyOn10AFuse#5Status";
CM_ SG_ 2566875815 KeyOn10AFuse4St "KeyOn10AFuse#4Status";
CM_ SG_ 2566875815 KeyOn10AFuse3St "KeyOn10AFuse#3Status";
CM_ SG_ 2566875815 KeyOn10AFuse2St "KeyOn10AFuse#2Status";
CM_ SG_ 2566875815 KeyOn10AFuse1St "KeyOn10AFuse#1Status";
CM_ SG_ 2566875815 KeyOn5AFuse15St "KeyOn5AFuse#15Status";
CM_ SG_ 2566875815 KeyOn5AFuse14St "KeyOn5AFuse#14Status";
CM_ SG_ 2566875815 KeyOn5AFuse13St "KeyOn5AFuse#13Status";
CM_ SG_ 2566875815 KeyOn5AFuse12St "KeyOn5AFuse#12Status";
CM_ SG_ 2566875815 KeyOn5AFuse11St "KeyOn5AFuse#11Status";
CM_ SG_ 2566875815 KeyOn5AFuse10St "KeyOn5AFuse#10Status";
CM_ SG_ 2566875815 KeyOn5AFuse9St "KeyOn5AFuse#9Status";
CM_ SG_ 2566875815 KeyOn5AFuse8St "KeyOn5AFuse#8Status";
CM_ SG_ 2566875815 KeyOn5AFuse7St "KeyOn5AFuse#7Status";
CM_ SG_ 2566875815 KeyOn5AFuse6St "KeyOn5AFuse#6Status";
CM_ SG_ 2566875815 KeyOn5AFuse5St "KeyOn5AFuse#5Status";
CM_ SG_ 2566875815 KeyOn5AFuse4St "KeyOn5AFuse#4Status";
CM_ SG_ 2566875815 KeyOn5AFuse3St "KeyOn5AFuse#3Status";
CM_ SG_ 2566875815 KeyOn5AFuse2St "KeyOn5AFuse#2Status";
CM_ SG_ 2566875815 KeyOn5AFuse1St "KeyOn5AFuse#1Status";
CM_ SG_ 2566875815 BPlus30AFuse5St "B+30AFuse#5Status";
CM_ SG_ 2566875815 BPlus30AFuse4St "B+30AFuse#4Status";
CM_ SG_ 2566875815 BPlus30AFuse3St "B+30AFuse#3Status";
CM_ SG_ 2566875815 BPlus30AFuse2St "B+30AFuse#2Status";
CM_ SG_ 2566875815 BPlus30AFuse1St "B+30AFuse#1Status";
CM_ SG_ 2566875815 BPlus20AFuse5St "B+20AFuse#5Status";
CM_ SG_ 2566875815 BPlus20AFuse4St "B+20AFuse#4Status";
CM_ SG_ 2566875815 BPlus20AFuse3St "B+20AFuse#3Status";
CM_ SG_ 2566875815 BPlus20AFuse2St "B+20AFuse#2Status";
CM_ SG_ 2566875815 BPlus20AFuse1St "B+20AFuse#1Status";
CM_ SG_ 2566875815 BPlus5AFuse10St "B+5AFuse#10Status";
CM_ SG_ 2566875815 BPlus5AFuse9St "B+5AFuse#9Status";
CM_ SG_ 2566875815 BPlus5AFuse8St "B+5AFuse#8Status";
CM_ SG_ 2566875815 BPlus5AFuse7St "B+5AFuse#7Status";
CM_ SG_ 2566875815 BPlus5AFuse6St "B+5AFuse#6Status";
CM_ SG_ 2566875815 BPlus5AFuse5St "B+5AFuse#5Status";
CM_ SG_ 2566875815 BPlus5AFuse4St "B+5AFuse#4Status";
CM_ SG_ 2566875815 BPlus5AFuse3St "B+5AFuse#3Status";
CM_ SG_ 2566875815 BPlus5AFuse2St "B+5AFuse#2Status";
CM_ SG_ 2566875815 BPlus5AFuse1St "B+5AFuse#1Status";
CM_ SG_ 2566875815 IpsTotalCur "IPSTotalCurrent";
CM_ SG_ 2566875815 MINIFuse2Cur "MINIFuse#2Current";
CM_ SG_ 2566875815 MINIFuse1Cur "MINIFuse#1Current";
CM_ SG_ 2566875815 MicroFuse5Cur "MicroFuse#5Current";
CM_ SG_ 2566875815 MicroFuse4Cur "MicroFuse#4Current";
CM_ SG_ 2566875815 MicroFuse3Cur "MicroFuse#3Current";
CM_ SG_ 2566875815 MicroFuse2Cur "MicroFuse#2Current";
CM_ SG_ 2566875815 MicroFuse1Cur "MicroFuse#1Current";
CM_ SG_ 2566875815 KeyOnPwrCur "KEYONPowerCurrent";
CM_ SG_ 2566875815 BPlusPwrCur "B+PowerCurrent";
CM_ BO_ 2566875929 "Aircon Response Message 1";
CM_ SG_ 2566875929 AcpSsPrs "ACPsensorPressure";
CM_ SG_ 2566875929 CurAmbTmpCelsRealTm "CurrentAmbientTemperature(Celsius),RealTime";
CM_ SG_ 2566875929 TmpSt "TemperatureState";
CM_ SG_ 2566875929 CurBlowerSpd "CurrentBlowerSpeed";
CM_ SG_ 2566875929 CurAmbTmpCelsFilt "CurrentAmbientTemperature(Celsius),Filtered";
CM_ SG_ 2566875929 CurTmpSet "CurrentTemperatureSetting(Celsius)";
CM_ BO_ 2566876320 "Doosan CAN Audio Information";
CM_ BO_ 2566876576 "Audio Frequency to GP";
CM_ SG_ 2566876576 ReqPgn "Requesting PGN";
CM_ SG_ 2566876576 MsgCounter "Message Counter";
CM_ BO_ 2566876832 "Audio Preset Frequency to GP";
CM_ SG_ 2566876832 AdoPreSetAma6FrqtoGp "Audio PreSET AMA 6 Frequency to GP";
CM_ SG_ 2566876832 AdoPreSetAma5FrqtoGp "Audio PreSET AMA 5 Frequency to GP";
CM_ SG_ 2566876832 AdoPreSetAma4FrqtoGp "Audio PreSET AMA 4 Frequency to GP";
CM_ SG_ 2566876832 AdoPreSetAma3FrqtoGp "Audio PreSET AMA 3 Frequency to GP";
CM_ SG_ 2566876832 AdoPreSetAma2FrqtoGp "Audio PreSET AMA 2 Frequency to GP";
CM_ SG_ 2566876832 AdoPreSetAma1FrqtoGp "Audio PreSET AMA 1 Frequency to GP";
CM_ SG_ 2566876832 AdoPreSetAm26FrqtoGp "Audio PreSET AM2 6 Frequency to GP";
CM_ SG_ 2566876832 AdoPreSetAm25FrqtoGp "Audio PreSET AM2 5 Frequency to GP";
CM_ SG_ 2566876832 AdoPreSetAm24FrqtoGp "Audio PreSET AM2 4 Frequency to GP";
CM_ SG_ 2566876832 AdoPreSetAm23FrqtoGp "Audio PreSET AM2 3 Frequency to GP";
CM_ SG_ 2566876832 AdoPreSetAm22FrqtoGp "Audio PreSET AM2 2 Frequency to GP";
CM_ SG_ 2566876832 AdoPreSetAm21FrqtoGp "Audio PreSET AM2 1 Frequency to GP";
CM_ SG_ 2566876832 AdoPreSetAm16FrqtoGp "Audio PreSET AM1 6 Frequency to GP";
CM_ SG_ 2566876832 AdoPreSetAm15FrqtoGp "Audio PreSET AM1 5 Frequency to GP";
CM_ SG_ 2566876832 AdoPreSetAm14FrqtoGp "Audio PreSET AM1 4 Frequency to GP";
CM_ SG_ 2566876832 AdoPreSetAm13FrqtoGp "Audio PreSET AM1 3 Frequency to GP";
CM_ SG_ 2566876832 AdoPreSetAm12FrqtoGp "Audio PreSET AM1 2 Frequency to GP";
CM_ SG_ 2566876832 AdoPreSetAm11FrqtoGp "Audio PreSET AM1 1 Frequency to GP";
CM_ SG_ 2566876832 AdoPreSetFma6FrqtoGp "Audio PreSET FMA 6 Frequency to GP";
CM_ SG_ 2566876832 AdoPreSetFma5FrqtoGp "Audio PreSET FMA 5 Frequency to GP";
CM_ SG_ 2566876832 AdoPreSetFma4FrqtoGp "Audio PreSET FMA 4 Frequency to GP";
CM_ SG_ 2566876832 AdoPreSetFma3FrqtoGp "Audio PreSET FMA 3 Frequency to GP";
CM_ SG_ 2566876832 AdoPreSetFma2FrqtoGp "Audio PreSET FMA 2 Frequency to GP";
CM_ SG_ 2566876832 AdoPreSetFma1FrqtoGp "Audio PreSET FMA 1 Frequency to GP";
CM_ SG_ 2566876832 AdoPreSetFm26FrqtoGp "Audio PreSET FM2 6 Frequency to GP";
CM_ SG_ 2566876832 AdoPreSetFm25FrqtoGp "Audio PreSET FM2 5 Frequency to GP";
CM_ SG_ 2566876832 AdoPreSetFm24FrqtoGp "Audio PreSET FM2 4 Frequency to GP";
CM_ SG_ 2566876832 AdoPreSetFm23FrqtoGp "Audio PreSET FM2 3 Frequency to GP";
CM_ SG_ 2566876832 AdoPreSetFm22FrqtoGp "Audio PreSET FM2 2 Frequency to GP";
CM_ SG_ 2566876832 AdoPreSetFm21FrqtoGp "Audio PreSET FM2 1 Frequency to GP";
CM_ SG_ 2566876832 AdoPreSetFm16FrqtoGp "Audio PreSET FM1 6 Frequency to GP";
CM_ SG_ 2566876832 AdoPreSetFm15FrqtoGp "Audio PreSET FM1 5 Frequency to GP";
CM_ SG_ 2566876832 AdoPreSetFm14FrqtoGp "Audio PreSET FM1 4 Frequency to GP";
CM_ SG_ 2566876832 AdoPreSetFm13FrqtoGp "Audio PreSET FM1 3 Frequency to GP";
CM_ SG_ 2566876832 AdoPreSetFm12FrqtoGp "Audio PreSET FM1 2 Frequency to GP";
CM_ SG_ 2566876832 AdoPreSetFm11FrqtoGp "Audio PreSET FM1 1 Frequency to GP";
CM_ BO_ 2566876961 "ACU Control2";
CM_ SG_ 2566876961 LowOutReq8 "LowOutputrequest#8";
CM_ SG_ 2566876961 LowOutReq7 "LowOutputrequest#7";
CM_ SG_ 2566876961 LowOutReq6 "LowOutputrequest#6";
CM_ SG_ 2566876961 LowOutReq5 "LowOutputrequest#5";
CM_ SG_ 2566876961 LowOutReq4 "LowOutputrequest#4";
CM_ SG_ 2566876961 LowOutReq3 "LowOutputrequest#3";
CM_ SG_ 2566876961 LowOutReq2 "LowOutputrequest#2";
CM_ SG_ 2566876961 LowOutReq1 "LowOutputrequest#1";
CM_ SG_ 2566876961 OutReq15 "Outputrequest#15";
CM_ SG_ 2566876961 OutReq14 "Outputrequest#14";
CM_ SG_ 2566876961 OutReq13 "Outputrequest#13";
CM_ SG_ 2566876961 OutReq12 "Outputrequest#12";
CM_ SG_ 2566876961 OutReq11 "Outputrequest#11";
CM_ SG_ 2566876961 OutReq10 "Outputrequest#10";
CM_ SG_ 2566876961 OutReq9 "Outputrequest#9";
CM_ SG_ 2566876961 OutReq8 "Outputrequest#8";
CM_ SG_ 2566876961 OutReq7 "Outputrequest#7";
CM_ SG_ 2566876961 OutReq6 "Outputrequest#6";
CM_ SG_ 2566876961 OutReq5 "Outputrequest#5";
CM_ SG_ 2566876961 OutReq4 "Outputrequest#4";
CM_ SG_ 2566876961 OutReq3 "Outputrequest#3";
CM_ SG_ 2566876961 OutReq2 "Outputrequest#2";
CM_ SG_ 2566876961 OutReq1 "Outputrequest#1";
BA_DEF_ BO_  "Channel" STRING ;
BA_DEF_ BO_  "VssMsg" STRING ;
BA_DEF_ SG_  "VssSig" STRING ;
BA_DEF_ BO_  "GenMsgCycleTime" INT 0 65535;
BA_DEF_ SG_  "SystemSignalLongSymbol" STRING ;
BA_DEF_DEF_  "Channel" "";
BA_DEF_DEF_  "VssMsg" "";
BA_DEF_DEF_  "VssSig" "";
BA_DEF_DEF_  "GenMsgCycleTime" 0;
BA_DEF_DEF_  "SystemSignalLongSymbol" "";
BA_ "GenMsgCycleTime" BO_ 2566866721 200;
BA_ "VssMsg" BO_ 2566866721 "Mch.MCU.SIG3";
BA_ "Channel" BO_ 2566866721 "can1";
BA_ "GenMsgCycleTime" BO_ 2566866977 500;
BA_ "VssMsg" BO_ 2566866977 "Mch.MCU.GPG2";
BA_ "Channel" BO_ 2566866977 "can1";
BA_ "GenMsgCycleTime" BO_ 2566867233 500;
BA_ "VssMsg" BO_ 2566867233 "Mch.MCU.GPG3";
BA_ "Channel" BO_ 2566867233 "can1";
BA_ "GenMsgCycleTime" BO_ 2566867489 200;
BA_ "VssMsg" BO_ 2566867489 "Mch.MCU.SIG4";
BA_ "Channel" BO_ 2566867489 "can1";
BA_ "GenMsgCycleTime" BO_ 2566867745 200;
BA_ "VssMsg" BO_ 2566867745 "Mch.MCU.GPG4";
BA_ "Channel" BO_ 2566867745 "can1";
BA_ "VssMsg" BO_ 2566868257 "Mch.MCU.METPSC";
BA_ "Channel" BO_ 2566868257 "can1";
BA_ "GenMsgCycleTime" BO_ 2566868921 10;
BA_ "VssMsg" BO_ 2566868921 "Mch.EGDL.EDO";
BA_ "Channel" BO_ 2566868921 "can1";
BA_ "GenMsgCycleTime" BO_ 2566869025 100;
BA_ "VssMsg" BO_ 2566869025 "Mch.MCU.JSO";
BA_ "Channel" BO_ 2566869025 "can1";
BA_ "GenMsgCycleTime" BO_ 2566869158 100;
BA_ "VssMsg" BO_ 2566869158 "Mch.JS.JSO";
BA_ "Channel" BO_ 2566869158 "can1";
BA_ "VssMsg" BO_ 2365542696 "Mch.GP.JCM";
BA_ "Channel" BO_ 2365542696 "can1";
BA_ "GenMsgCycleTime" BO_ 2365542917 10;
BA_ "VssMsg" BO_ 2365542917 "Mch.FNR.ZFTC1";
BA_ "Channel" BO_ 2365542917 "can1";
BA_ "GenMsgCycleTime" BO_ 2365543201 100;
BA_ "VssMsg" BO_ 2365543201 "Mch.MCU.KEYPADBI";
BA_ "Channel" BO_ 2365543201 "can1";
BA_ "GenMsgCycleTime" BO_ 2365543504 100;
BA_ "VssMsg" BO_ 2365543504 "Mch.KPD1.KEYPADS";
BA_ "Channel" BO_ 2365543504 "can1";
BA_ "GenMsgCycleTime" BO_ 2365543713 100;
BA_ "VssMsg" BO_ 2365543713 "Mch.MCU.KEYPADI1";
BA_ "Channel" BO_ 2365543713 "can1";
BA_ "GenMsgCycleTime" BO_ 2365543969 100;
BA_ "VssMsg" BO_ 2365543969 "Mch.MCU.KEYPADMI1";
BA_ "Channel" BO_ 2365543969 "can1";
BA_ "GenMsgCycleTime" BO_ 2365544225 100;
BA_ "VssMsg" BO_ 2365544225 "Mch.MCU.KEYPADMI2";
BA_ "Channel" BO_ 2365544225 "can1";
BA_ "GenMsgCycleTime" BO_ 2365544481 100;
BA_ "VssMsg" BO_ 2365544481 "Mch.MCU.KEYPADI2";
BA_ "Channel" BO_ 2365544481 "can1";
BA_ "GenMsgCycleTime" BO_ 2365544737 100;
BA_ "VssMsg" BO_ 2365544737 "Mch.MCU.KEYPADI3";
BA_ "Channel" BO_ 2365544737 "can1";
BA_ "VssMsg" BO_ 2566871629 "Mch.CBSW.HCMD";
BA_ "Channel" BO_ 2566871629 "can2";
BA_ "GenMsgCycleTime" BO_ 2566872001 20;
BA_ "VssMsg" BO_ 2566872001 "Mch.IMU1.ASI";
BA_ "Channel" BO_ 2566872001 "can1";
BA_ "GenMsgCycleTime" BO_ 2566872002 20;
BA_ "VssMsg" BO_ 2566872002 "Mch.IMU2.ASI";
BA_ "Channel" BO_ 2566872002 "can1";
BA_ "GenMsgCycleTime" BO_ 2566872003 20;
BA_ "VssMsg" BO_ 2566872003 "Mch.IMU3.ASI";
BA_ "Channel" BO_ 2566872003 "can1";
BA_ "GenMsgCycleTime" BO_ 2566872004 20;
BA_ "VssMsg" BO_ 2566872004 "Mch.IMU4.ASI";
BA_ "Channel" BO_ 2566872004 "can1";
BA_ "GenMsgCycleTime" BO_ 2566872005 20;
BA_ "VssMsg" BO_ 2566872005 "Mch.IMU5.ASI";
BA_ "Channel" BO_ 2566872005 "can1";
BA_ "GenMsgCycleTime" BO_ 2365545552 100;
BA_ "VssMsg" BO_ 2365545552 "Mch.KPD1.KEYPADS2";
BA_ "Channel" BO_ 2365545552 "can1";
BA_ "GenMsgCycleTime" BO_ 2365545761 100;
BA_ "VssMsg" BO_ 2365545761 "Mch.MCU.KEYPADI4";
BA_ "Channel" BO_ 2365545761 "can1";
BA_ "GenMsgCycleTime" BO_ 2566873377 100;
BA_ "VssMsg" BO_ 2566873377 "Mch.MCU.ACUCTR";
BA_ "Channel" BO_ 2566873377 "can1";
BA_ "GenMsgCycleTime" BO_ 2566873630 100;
BA_ "VssMsg" BO_ 2566873630 "Mch.ACU.ACUFB1";
BA_ "Channel" BO_ 2566873630 "can1";
BA_ "GenMsgCycleTime" BO_ 2566873767 100;
BA_ "VssMsg" BO_ 2566873767 "Mch.SMB.ACUFB1";
BA_ "Channel" BO_ 2566873767 "can1";
BA_ "GenMsgCycleTime" BO_ 2566873886 100;
BA_ "VssMsg" BO_ 2566873886 "Mch.ACU.ACUFB2";
BA_ "Channel" BO_ 2566873886 "can1";
BA_ "GenMsgCycleTime" BO_ 2566874654 100;
BA_ "VssMsg" BO_ 2566874654 "Mch.ACU.ACUFB3";
BA_ "Channel" BO_ 2566874654 "can1";
BA_ "GenMsgCycleTime" BO_ 2566874910 100;
BA_ "VssMsg" BO_ 2566874910 "Mch.ACU.ACUFB4";
BA_ "Channel" BO_ 2566874910 "can1";
BA_ "GenMsgCycleTime" BO_ 2566875297 100;
BA_ "VssMsg" BO_ 2566875297 "Mch.KPAC.ACCMD";
BA_ "Channel" BO_ 2566875297 "can1";
BA_ "GenMsgCycleTime" BO_ 2566875422 100;
BA_ "VssMsg" BO_ 2566875422 "Mch.ACU.ACUFB5";
BA_ "Channel" BO_ 2566875422 "can1";
BA_ "GenMsgCycleTime" BO_ 2566875559 100;
BA_ "VssMsg" BO_ 2566875559 "Mch.SMB.ACUFB5";
BA_ "Channel" BO_ 2566875559 "can1";
BA_ "VssMsg" BO_ 2566875678 "Mch.ACU.ACUFB6";
BA_ "Channel" BO_ 2566875678 "can1";
BA_ "VssMsg" BO_ 2566875815 "Mch.SMB.ACUFB6";
BA_ "Channel" BO_ 2566875815 "can1";
BA_ "GenMsgCycleTime" BO_ 2566875929 500;
BA_ "VssMsg" BO_ 2566875929 "Mch.ACCU.ACRM1";
BA_ "Channel" BO_ 2566875929 "can1";
BA_ "GenMsgCycleTime" BO_ 2566876320 100;
BA_ "VssMsg" BO_ 2566876320 "Mch.Audio.DCAI";
BA_ "Channel" BO_ 2566876320 "can2";
BA_ "VssMsg" BO_ 2566876576 "Mch.Audio.AFRTGP";
BA_ "Channel" BO_ 2566876576 "can1";
BA_ "VssMsg" BO_ 2566876832 "Mch.Audio.APFGP";
BA_ "Channel" BO_ 2566876832 "can1";
BA_ "GenMsgCycleTime" BO_ 2566876961 100;
BA_ "VssMsg" BO_ 2566876961 "Mch.MCU.ACUCTR2";
BA_ "Channel" BO_ 2566876961 "can1";
BA_ "VssSig" SG_ 2566866721 DifActlTrgGrdt "Mch.MCU.SIG3.DifActlTrgGrdt";
BA_ "VssSig" SG_ 2566866721 OprPrsntSt "Mch.MCU.SIG3.OprPrsntSt";
BA_ "VssSig" SG_ 2566866721 HydCutOffRls "Mch.MCU.SIG3.HydCutOffRls";
BA_ "VssSig" SG_ 2566866721 ChgErr "Mch.MCU.SIG3.ChgErr";
BA_ "VssSig" SG_ 2566866721 ChgSt "Mch.MCU.SIG3.ChgSt";
BA_ "VssSig" SG_ 2566866721 WrkTrv "Mch.MCU.SIG3.WrkTrv";
BA_ "VssSig" SG_ 2566866721 BatLw "Mch.MCU.SIG3.BatLw";
BA_ "VssSig" SG_ 2566866721 HydLck "Mch.MCU.SIG3.HydLck";
BA_ "VssSig" SG_ 2566866721 PopCmdHillDscntCtrl "Mch.MCU.SIG3.PopCmdHillDscntCtrl";
BA_ "VssSig" SG_ 2566866721 HillDscntCtrlSt "Mch.MCU.SIG3.HillDscntCtrlSt";
BA_ "VssSig" SG_ 2566866721 OprPrsnc "Mch.MCU.SIG3.OprPrsnc";
BA_ "VssSig" SG_ 2566866721 BckDust "Mch.MCU.SIG3.BckDust";
BA_ "VssSig" SG_ 2566866721 BmsPrhtLmp "Mch.MCU.SIG3.BmsPrhtLmp";
BA_ "VssSig" SG_ 2566866721 DacSt "Mch.MCU.SIG3.DacSt";
BA_ "VssSig" SG_ 2566866721 EmcvFngrtpLvrErr "Mch.MCU.SIG3.EmcvFngrtpLvrErr";
BA_ "VssSig" SG_ 2566866721 PopCmdFnrNtrl "Mch.MCU.SIG3.PopCmdFnrNtrl";
BA_ "VssSig" SG_ 2566866721 IllminSt "Mch.MCU.SIG3.IllminSt";
BA_ "VssSig" SG_ 2566866721 ChmslSt "Mch.MCU.SIG3.ChmslSt";
BA_ "VssSig" SG_ 2566866721 CdsFanRvsSt "Mch.MCU.SIG3.CdsFanRvsSt";
BA_ "VssSig" SG_ 2566866721 CacFanRvsSt "Mch.MCU.SIG3.CacFanRvsSt";
BA_ "VssSig" SG_ 2566866721 CurMaxSpdMinor "Mch.MCU.SIG3.CurMaxSpdMinor";
BA_ "VssSig" SG_ 2566866721 WhlTypeStrMd "Mch.MCU.SIG3.WhlTypeStrMd";
BA_ "VssSig" SG_ 2566866721 WrnGndSlop "Mch.MCU.SIG3.WrnGndSlop";
BA_ "VssSig" SG_ 2566866721 WrnOilTmpLw "Mch.MCU.SIG3.WrnOilTmpLw";
BA_ "VssSig" SG_ 2566866721 WghConfirmWarnMsg "Mch.MCU.SIG3.WghConfirmWarnMsg";
BA_ "VssSig" SG_ 2566866721 AttOpr "Mch.MCU.SIG3.AttOpr";
BA_ "VssSig" SG_ 2566866721 QckCoolSt "Mch.MCU.SIG3.QckCoolSt";
BA_ "VssSig" SG_ 2566866721 PopCmdBckAstTargetSet "Mch.MCU.SIG3.PopCmdBckAstTargetSet";
BA_ "VssSig" SG_ 2566866721 WrnLimpHome "Mch.MCU.SIG3.WrnLimpHome";
BA_ "VssSig" SG_ 2566866721 DozAstStopReq "Mch.MCU.SIG3.DozAstStopReq";
BA_ "VssSig" SG_ 2566866721 MchCond "Mch.MCU.SIG3.MchCond";
BA_ "VssSig" SG_ 2566866721 WrnRollOvr "Mch.MCU.SIG3.WrnRollOvr";
BA_ "VssSig" SG_ 2566866721 WrnArmPosOnDrv "Mch.MCU.SIG3.WrnArmPosOnDrv";
BA_ "VssSig" SG_ 2566866721 WrnThwStrShft "Mch.MCU.SIG3.WrnThwStrShft";
BA_ "VssSig" SG_ 2566866721 WrnRamLck "Mch.MCU.SIG3.WrnRamLck";
BA_ "VssSig" SG_ 2566866721 WrnHstOilFilt "Mch.MCU.SIG3.WrnHstOilFilt";
BA_ "VssSig" SG_ 2566866721 WrnGrBoxOvTmp "Mch.MCU.SIG3.WrnGrBoxOvTmp";
BA_ "VssSig" SG_ 2566866721 VhcStTractionLv "Mch.MCU.SIG3.VhcStTractionLv";
BA_ "VssSig" SG_ 2566866721 WhlLis "Mch.MCU.SIG3.WhlLis";
BA_ "VssSig" SG_ 2566866721 WhlDzTrlHitch "Mch.MCU.SIG3.WhlDzTrlHitch";
BA_ "VssSig" SG_ 2566866721 WhlSwgAlign "Mch.MCU.SIG3.WhlSwgAlign";
BA_ "VssSig" SG_ 2566866721 WhlRamLckAuto "Mch.MCU.SIG3.WhlRamLckAuto";
BA_ "VssSig" SG_ 2566866977 GdTrsmSumpOilTmp "Mch.MCU.GPG2.GdTrsmSumpOilTmp";
BA_ "VssSig" SG_ 2566866977 BrkChgLv "Mch.MCU.GPG2.BrkChgLv";
BA_ "VssSig" SG_ 2566866977 TrgRollSlp "Mch.MCU.GPG2.TrgRollSlp";
BA_ "VssSig" SG_ 2566866977 TrgPchSlp "Mch.MCU.GPG2.TrgPchSlp";
BA_ "VssSig" SG_ 2566866977 CorrRollSlp "Mch.MCU.GPG2.CorrRollSlp";
BA_ "VssSig" SG_ 2566866977 CorrPchSlp "Mch.MCU.GPG2.CorrPchSlp";
BA_ "VssSig" SG_ 2566866977 CorrRollAng "Mch.MCU.GPG2.CorrRollAng";
BA_ "VssSig" SG_ 2566866977 CorrPchAng "Mch.MCU.GPG2.CorrPchAng";
BA_ "VssSig" SG_ 2566867233 TrgRollSlp "Mch.MCU.GPG3.TrgRollSlp";
BA_ "VssSig" SG_ 2566867233 TrgPchSlp "Mch.MCU.GPG3.TrgPchSlp";
BA_ "VssSig" SG_ 2566867233 CorrRollSlp "Mch.MCU.GPG3.CorrRollSlp";
BA_ "VssSig" SG_ 2566867233 CorrPchSlp "Mch.MCU.GPG3.CorrPchSlp";
BA_ "VssSig" SG_ 2566867489 WarnPopLimitangexcess "Mch.MCU.SIG4.WarnPopLimitangexcess";
BA_ "VssSig" SG_ 2566867489 WarnPopMgMcSsErr "Mch.MCU.SIG4.WarnPopMgMcSsErr";
BA_ "VssSig" SG_ 2566867489 McTemporaryRlsPop "Mch.MCU.SIG4.McTemporaryRlsPop";
BA_ "VssSig" SG_ 2566867489 VhcStStickStr "Mch.MCU.SIG4.VhcStStickStr";
BA_ "VssSig" SG_ 2566867489 VhcStFineSwg "Mch.MCU.SIG4.VhcStFineSwg";
BA_ "VssSig" SG_ 2566867489 ActTrvlSpdforCrwl "Mch.MCU.SIG4.ActTrvlSpdforCrwl";
BA_ "VssSig" SG_ 2566867489 ActTrvlStforCrwl "Mch.MCU.SIG4.ActTrvlStforCrwl";
BA_ "VssSig" SG_ 2566867489 VhcStParallelLift "Mch.MCU.SIG4.VhcStParallelLift";
BA_ "VssSig" SG_ 2566867489 VhcStFrSspnAuto "Mch.MCU.SIG4.VhcStFrSspnAuto";
BA_ "VssSig" SG_ 2566867489 RmCrakingSt "Mch.MCU.SIG4.RmCrakingSt";
BA_ "VssSig" SG_ 2566867489 IndTrmsColdStart "Mch.MCU.SIG4.IndTrmsColdStart";
BA_ "VssSig" SG_ 2566867489 VhcStElevatingCabin "Mch.MCU.SIG4.VhcStElevatingCabin";
BA_ "VssSig" SG_ 2566867489 WarnPopStickStr "Mch.MCU.SIG4.WarnPopStickStr";
BA_ "VssSig" SG_ 2566867489 PopCmdThwLvrErr "Mch.MCU.SIG4.PopCmdThwLvrErr";
BA_ "VssSig" SG_ 2566867489 HpApMd "Mch.MCU.SIG4.HpApMd";
BA_ "VssSig" SG_ 2566867489 GrLmt "Mch.MCU.SIG4.GrLmt";
BA_ "VssSig" SG_ 2566867489 BodyAng "Mch.MCU.SIG4.BodyAng";
BA_ "VssSig" SG_ 2566867489 WghIndSt "Mch.MCU.SIG4.WghIndSt";
BA_ "VssSig" SG_ 2566867489 BrkHold "Mch.MCU.SIG4.BrkHold";
BA_ "VssSig" SG_ 2566867489 RtrdSt "Mch.MCU.SIG4.RtrdSt";
BA_ "VssSig" SG_ 2566867489 PilotCutOffSt "Mch.MCU.SIG4.PilotCutOffSt";
BA_ "VssSig" SG_ 2566867489 BodySt "Mch.MCU.SIG4.BodySt";
BA_ "VssSig" SG_ 2566867489 VhcStGndSaw "Mch.MCU.SIG4.VhcStGndSaw";
BA_ "VssSig" SG_ 2566867489 PopCmdJoyLvrNtrlErr "Mch.MCU.SIG4.PopCmdJoyLvrNtrlErr";
BA_ "VssSig" SG_ 2566867489 VhcStIntAxleLck "Mch.MCU.SIG4.VhcStIntAxleLck";
BA_ "VssSig" SG_ 2566867489 TrlHhFlowMd "Mch.MCU.SIG4.TrlHhFlowMd";
BA_ "VssSig" SG_ 2566867489 ExcAutoBrkAntiFire "Mch.MCU.SIG4.ExcAutoBrkAntiFire";
BA_ "VssSig" SG_ 2566867489 TrlIntLckOvrd "Mch.MCU.SIG4.TrlIntLckOvrd";
BA_ "VssSig" SG_ 2566867489 TrlCtrlFlow "Mch.MCU.SIG4.TrlCtrlFlow";
BA_ "VssSig" SG_ 2566867489 TrlSelfLv "Mch.MCU.SIG4.TrlSelfLv";
BA_ "VssSig" SG_ 2566867489 TrlHhFlow "Mch.MCU.SIG4.TrlHhFlow";
BA_ "VssSig" SG_ 2566867745 Acc3SsPress "Mch.MCU.GPG4.Acc3SsPress";
BA_ "VssSig" SG_ 2566867745 Acc2SsPress "Mch.MCU.GPG4.Acc2SsPress";
BA_ "VssSig" SG_ 2566867745 Acc1SsPress "Mch.MCU.GPG4.Acc1SsPress";
BA_ "VssSig" SG_ 2566867745 EcoGgSt "Mch.MCU.GPG4.EcoGgSt";
BA_ "VssSig" SG_ 2566867745 EcoGgLv "Mch.MCU.GPG4.EcoGgLv";
BA_ "VssSig" SG_ 2566868257 MaximumEgSpd "Mch.MCU.METPSC.MaximumEgSpd";
BA_ "VssSig" SG_ 2566868257 AutoCalbMd "Mch.MCU.METPSC.AutoCalbMd";
BA_ "VssSig" SG_ 2566868257 CalbReq "Mch.MCU.METPSC.CalbReq";
BA_ "VssSig" SG_ 2566868257 VhcStTpsCalb "Mch.MCU.METPSC.VhcStTpsCalb";
BA_ "VssSig" SG_ 2566868257 MinimumEgSpd "Mch.MCU.METPSC.MinimumEgSpd";
BA_ "VssSig" SG_ 2566868257 VhcStSsNrm "Mch.MCU.METPSC.VhcStSsNrm";
BA_ "VssSig" SG_ 2566868257 VhcStEgIgn "Mch.MCU.METPSC.VhcStEgIgn";
BA_ "VssSig" SG_ 2566868257 VhcStPilotCutOff "Mch.MCU.METPSC.VhcStPilotCutOff";
BA_ "VssSig" SG_ 2566868257 VhcStEgCtrlDialMax "Mch.MCU.METPSC.VhcStEgCtrlDialMax";
BA_ "VssSig" SG_ 2566868921 DialStep "Mch.EGDL.EDO.DialStep";
BA_ "VssSig" SG_ 2566868921 DialPos "Mch.EGDL.EDO.DialPos";
BA_ "VssSig" SG_ 2566869025 BlIntensity "Mch.MCU.JSO.BlIntensity";
BA_ "VssSig" SG_ 2566869025 EncoderDtDefineMax "Mch.MCU.JSO.EncoderDtDefineMax";
BA_ "VssSig" SG_ 2566869025 AirconShortcutBtn "Mch.MCU.JSO.AirconShortcutBtn";
BA_ "VssSig" SG_ 2566869025 BzStopBtn "Mch.MCU.JSO.BzStopBtn";
BA_ "VssSig" SG_ 2566869025 CallBtn "Mch.MCU.JSO.CallBtn";
BA_ "VssSig" SG_ 2566869025 FavoriteBtn "Mch.MCU.JSO.FavoriteBtn";
BA_ "VssSig" SG_ 2566869025 DmbBtn "Mch.MCU.JSO.DmbBtn";
BA_ "VssSig" SG_ 2566869025 WrkMdBtn "Mch.MCU.JSO.WrkMdBtn";
BA_ "VssSig" SG_ 2566869025 AutoidleBzStopBtn "Mch.MCU.JSO.AutoidleBzStopBtn";
BA_ "VssSig" SG_ 2566869025 PwrMdBtn "Mch.MCU.JSO.PwrMdBtn";
BA_ "VssSig" SG_ 2566869025 CamEscBtn "Mch.MCU.JSO.CamEscBtn";
BA_ "VssSig" SG_ 2566869025 RotatyPushBtn "Mch.MCU.JSO.RotatyPushBtn";
BA_ "VssSig" SG_ 2566869025 EncoderDt "Mch.MCU.JSO.EncoderDt";
BA_ "VssSig" SG_ 2566869158 BlIntensity "Mch.JS.JSO.BlIntensity";
BA_ "VssSig" SG_ 2566869158 EncoderDtDefineMax "Mch.JS.JSO.EncoderDtDefineMax";
BA_ "VssSig" SG_ 2566869158 AirconShortcutBtn "Mch.JS.JSO.AirconShortcutBtn";
BA_ "VssSig" SG_ 2566869158 BzStopBtn "Mch.JS.JSO.BzStopBtn";
BA_ "VssSig" SG_ 2566869158 CallBtn "Mch.JS.JSO.CallBtn";
BA_ "VssSig" SG_ 2566869158 FavoriteBtn "Mch.JS.JSO.FavoriteBtn";
BA_ "VssSig" SG_ 2566869158 DmbBtn "Mch.JS.JSO.DmbBtn";
BA_ "VssSig" SG_ 2566869158 WrkMdBtn "Mch.JS.JSO.WrkMdBtn";
BA_ "VssSig" SG_ 2566869158 AutoidleBzStopBtn "Mch.JS.JSO.AutoidleBzStopBtn";
BA_ "VssSig" SG_ 2566869158 PwrMdBtn "Mch.JS.JSO.PwrMdBtn";
BA_ "VssSig" SG_ 2566869158 CamEscBtn "Mch.JS.JSO.CamEscBtn";
BA_ "VssSig" SG_ 2566869158 RotatyPushBtn "Mch.JS.JSO.RotatyPushBtn";
BA_ "VssSig" SG_ 2566869158 EncoderDt "Mch.JS.JSO.EncoderDt";
BA_ "VssSig" SG_ 2365542696 PwforthisMsg "Mch.GP.JCM.PwforthisMsg";
BA_ "VssSig" SG_ 2365542696 EncoderDtDefineMax "Mch.GP.JCM.EncoderDtDefineMax";
BA_ "VssSig" SG_ 2365542696 BrctRateforDtPck "Mch.GP.JCM.BrctRateforDtPck";
BA_ "VssSig" SG_ 2365542696 PgnforDtPck "Mch.GP.JCM.PgnforDtPck";
BA_ "VssSig" SG_ 2365542696 SA "Mch.GP.JCM.SA";
BA_ "VssSig" SG_ 2365542696 BacklightIntensity "Mch.GP.JCM.BacklightIntensity";
BA_ "VssSig" SG_ 2365543201 RvsFanLInd "Mch.MCU.KEYPADBI.RvsFanLInd";
BA_ "VssSig" SG_ 2365543201 RvsFanRInd "Mch.MCU.KEYPADBI.RvsFanRInd";
BA_ "VssSig" SG_ 2365543201 BoomLmpOprLInd "Mch.MCU.KEYPADBI.BoomLmpOprLInd";
BA_ "VssSig" SG_ 2365543201 BoomLmpOprCtrInd "Mch.MCU.KEYPADBI.BoomLmpOprCtrInd";
BA_ "VssSig" SG_ 2365543201 BoomLmpOprRInd "Mch.MCU.KEYPADBI.BoomLmpOprRInd";
BA_ "VssSig" SG_ 2365543201 InfoLInd "Mch.MCU.KEYPADBI.InfoLInd";
BA_ "VssSig" SG_ 2365543201 InfoCtrInd "Mch.MCU.KEYPADBI.InfoCtrInd";
BA_ "VssSig" SG_ 2365543201 InfoRInd "Mch.MCU.KEYPADBI.InfoRInd";
BA_ "VssSig" SG_ 2365543201 EmgStrLInd "Mch.MCU.KEYPADBI.EmgStrLInd";
BA_ "VssSig" SG_ 2365543201 EmgStrCtrInd "Mch.MCU.KEYPADBI.EmgStrCtrInd";
BA_ "VssSig" SG_ 2365543201 EmgStrRInd "Mch.MCU.KEYPADBI.EmgStrRInd";
BA_ "VssSig" SG_ 2365543201 LoadIsolationLInd "Mch.MCU.KEYPADBI.LoadIsolationLInd";
BA_ "VssSig" SG_ 2365543201 LoadIsolationCtrInd "Mch.MCU.KEYPADBI.LoadIsolationCtrInd";
BA_ "VssSig" SG_ 2365543201 LoadIsolationRInd "Mch.MCU.KEYPADBI.LoadIsolationRInd";
BA_ "VssSig" SG_ 2365543201 MirrorHtLInd "Mch.MCU.KEYPADBI.MirrorHtLInd";
BA_ "VssSig" SG_ 2365543201 MirrorHtCtrInd "Mch.MCU.KEYPADBI.MirrorHtCtrInd";
BA_ "VssSig" SG_ 2365543201 MirrorHtRInd "Mch.MCU.KEYPADBI.MirrorHtRInd";
BA_ "VssSig" SG_ 2365543201 RrWpWashLInd "Mch.MCU.KEYPADBI.RrWpWashLInd";
BA_ "VssSig" SG_ 2365543201 RrWpWashCtrInd "Mch.MCU.KEYPADBI.RrWpWashCtrInd";
BA_ "VssSig" SG_ 2365543201 RrWpWashRInd "Mch.MCU.KEYPADBI.RrWpWashRInd";
BA_ "VssSig" SG_ 2365543201 BeaconLInd "Mch.MCU.KEYPADBI.BeaconLInd";
BA_ "VssSig" SG_ 2365543201 BeaconCtrInd "Mch.MCU.KEYPADBI.BeaconCtrInd";
BA_ "VssSig" SG_ 2365543201 BeaconRInd "Mch.MCU.KEYPADBI.BeaconRInd";
BA_ "VssSig" SG_ 2365543201 RrWrkLmpLInd "Mch.MCU.KEYPADBI.RrWrkLmpLInd";
BA_ "VssSig" SG_ 2365543201 RrWrkLmpCtrInd "Mch.MCU.KEYPADBI.RrWrkLmpCtrInd";
BA_ "VssSig" SG_ 2365543201 RrWrkLmpRInd "Mch.MCU.KEYPADBI.RrWrkLmpRInd";
BA_ "VssSig" SG_ 2365543201 FrWrkLmpLInd "Mch.MCU.KEYPADBI.FrWrkLmpLInd";
BA_ "VssSig" SG_ 2365543201 FrWrkLmpCentorInd "Mch.MCU.KEYPADBI.FrWrkLmpCentorInd";
BA_ "VssSig" SG_ 2365543201 FrWrkLmpRInd "Mch.MCU.KEYPADBI.FrWrkLmpRInd";
BA_ "VssSig" SG_ 2365543201 HeadLmpLInd "Mch.MCU.KEYPADBI.HeadLmpLInd";
BA_ "VssSig" SG_ 2365543201 HeadLmpCtrInd "Mch.MCU.KEYPADBI.HeadLmpCtrInd";
BA_ "VssSig" SG_ 2365543201 HeadLmpRInd "Mch.MCU.KEYPADBI.HeadLmpRInd";
BA_ "VssSig" SG_ 2365543504 TrkExpansionSig "Mch.KPD1.KEYPADS.TrkExpansionSig";
BA_ "VssSig" SG_ 2365543504 InterlockOverrideSig "Mch.KPD1.KEYPADS.InterlockOverrideSig";
BA_ "VssSig" SG_ 2365543504 Aux8OprSig "Mch.KPD1.KEYPADS.Aux8OprSig";
BA_ "VssSig" SG_ 2365543504 Aux7OprSig "Mch.KPD1.KEYPADS.Aux7OprSig";
BA_ "VssSig" SG_ 2365543504 ContinuousFlowSig "Mch.KPD1.KEYPADS.ContinuousFlowSig";
BA_ "VssSig" SG_ 2365543504 RvsFanOprSig "Mch.KPD1.KEYPADS.RvsFanOprSig";
BA_ "VssSig" SG_ 2365543504 SelfLevelSig "Mch.KPD1.KEYPADS.SelfLevelSig";
BA_ "VssSig" SG_ 2365543504 BoomLis "Mch.KPD1.KEYPADS.BoomLis";
BA_ "VssSig" SG_ 2365543504 UpSig "Mch.KPD1.KEYPADS.UpSig";
BA_ "VssSig" SG_ 2365543504 DnSig "Mch.KPD1.KEYPADS.DnSig";
BA_ "VssSig" SG_ 2365543504 EnterSig "Mch.KPD1.KEYPADS.EnterSig";
BA_ "VssSig" SG_ 2365543504 MenuSig "Mch.KPD1.KEYPADS.MenuSig";
BA_ "VssSig" SG_ 2365543504 BzStopSig "Mch.KPD1.KEYPADS.BzStopSig";
BA_ "VssSig" SG_ 2365543504 DmbEntertainSig "Mch.KPD1.KEYPADS.DmbEntertainSig";
BA_ "VssSig" SG_ 2365543504 CallSig "Mch.KPD1.KEYPADS.CallSig";
BA_ "VssSig" SG_ 2365543504 RrMirrorHtSig "Mch.KPD1.KEYPADS.RrMirrorHtSig";
BA_ "VssSig" SG_ 2365543504 FrWpOprSig "Mch.KPD1.KEYPADS.FrWpOprSig";
BA_ "VssSig" SG_ 2365543504 RrWpOprSig "Mch.KPD1.KEYPADS.RrWpOprSig";
BA_ "VssSig" SG_ 2365543504 SideWpOprSig "Mch.KPD1.KEYPADS.SideWpOprSig";
BA_ "VssSig" SG_ 2365543504 FrWpWashOprSig "Mch.KPD1.KEYPADS.FrWpWashOprSig";
BA_ "VssSig" SG_ 2365543504 SideWpWashOprSig "Mch.KPD1.KEYPADS.SideWpWashOprSig";
BA_ "VssSig" SG_ 2365543504 AirCompOprSig "Mch.KPD1.KEYPADS.AirCompOprSig";
BA_ "VssSig" SG_ 2365543504 TrvlSpdOprSig "Mch.KPD1.KEYPADS.TrvlSpdOprSig";
BA_ "VssSig" SG_ 2365543504 AutoidleSig "Mch.KPD1.KEYPADS.AutoidleSig";
BA_ "VssSig" SG_ 2365543504 CrabRoundSelSig "Mch.KPD1.KEYPADS.CrabRoundSelSig";
BA_ "VssSig" SG_ 2365543504 TwoWhlFourWhlSelSig "Mch.KPD1.KEYPADS.TwoWhlFourWhlSelSig";
BA_ "VssSig" SG_ 2365543504 ThrottleLckUpOprSig "Mch.KPD1.KEYPADS.ThrottleLckUpOprSig";
BA_ "VssSig" SG_ 2365543504 TractionCtrlMdOprSig "Mch.KPD1.KEYPADS.TractionCtrlMdOprSig";
BA_ "VssSig" SG_ 2365543504 VariableSpdDnOprSig "Mch.KPD1.KEYPADS.VariableSpdDnOprSig";
BA_ "VssSig" SG_ 2365543504 VariableSpdUpOprSig "Mch.KPD1.KEYPADS.VariableSpdUpOprSig";
BA_ "VssSig" SG_ 2365543504 MaxSpdUpOprSig "Mch.KPD1.KEYPADS.MaxSpdUpOprSig";
BA_ "VssSig" SG_ 2365543504 MaxSpdDnOprSig "Mch.KPD1.KEYPADS.MaxSpdDnOprSig";
BA_ "VssSig" SG_ 2365543504 TrqCvtLckUpOprSig "Mch.KPD1.KEYPADS.TrqCvtLckUpOprSig";
BA_ "VssSig" SG_ 2365543504 ClutchCutOffOprSig "Mch.KPD1.KEYPADS.ClutchCutOffOprSig";
BA_ "VssSig" SG_ 2365543504 TrmsMdSelOprSig "Mch.KPD1.KEYPADS.TrmsMdSelOprSig";
BA_ "VssSig" SG_ 2365543504 ShakeControlSig "Mch.KPD1.KEYPADS.ShakeControlSig";
BA_ "VssSig" SG_ 2365543504 OutriggerAllSig "Mch.KPD1.KEYPADS.OutriggerAllSig";
BA_ "VssSig" SG_ 2365543504 OutriggerRrRSig "Mch.KPD1.KEYPADS.OutriggerRrRSig";
BA_ "VssSig" SG_ 2365543504 OutriggerRrLSig "Mch.KPD1.KEYPADS.OutriggerRrLSig";
BA_ "VssSig" SG_ 2365543504 OutriggerFrRSig "Mch.KPD1.KEYPADS.OutriggerFrRSig";
BA_ "VssSig" SG_ 2365543504 OutriggerFrLSig "Mch.KPD1.KEYPADS.OutriggerFrLSig";
BA_ "VssSig" SG_ 2365543504 DifLockEngagedOprSig "Mch.KPD1.KEYPADS.DifLockEngagedOprSig";
BA_ "VssSig" SG_ 2365543504 EmgStrOprSig "Mch.KPD1.KEYPADS.EmgStrOprSig";
BA_ "VssSig" SG_ 2365543504 BckDetentOprSig "Mch.KPD1.KEYPADS.BckDetentOprSig";
BA_ "VssSig" SG_ 2365543504 BoomDetentOprSig "Mch.KPD1.KEYPADS.BoomDetentOprSig";
BA_ "VssSig" SG_ 2365543504 LoadIsolationOprSig "Mch.KPD1.KEYPADS.LoadIsolationOprSig";
BA_ "VssSig" SG_ 2365543504 MdSelOprSig "Mch.KPD1.KEYPADS.MdSelOprSig";
BA_ "VssSig" SG_ 2365543504 MenuHelpOprSig "Mch.KPD1.KEYPADS.MenuHelpOprSig";
BA_ "VssSig" SG_ 2365543504 JoyStrSig "Mch.KPD1.KEYPADS.JoyStrSig";
BA_ "VssSig" SG_ 2365543504 FineSwgSig "Mch.KPD1.KEYPADS.FineSwgSig";
BA_ "VssSig" SG_ 2365543504 TrailerHitchSig "Mch.KPD1.KEYPADS.TrailerHitchSig";
BA_ "VssSig" SG_ 2365543504 AutoDigBrkSig "Mch.KPD1.KEYPADS.AutoDigBrkSig";
BA_ "VssSig" SG_ 2365543504 BoomSwgSig "Mch.KPD1.KEYPADS.BoomSwgSig";
BA_ "VssSig" SG_ 2365543504 WorkMdSig "Mch.KPD1.KEYPADS.WorkMdSig";
BA_ "VssSig" SG_ 2365543504 PwrMdSig "Mch.KPD1.KEYPADS.PwrMdSig";
BA_ "VssSig" SG_ 2365543504 TrvlAlmSig "Mch.KPD1.KEYPADS.TrvlAlmSig";
BA_ "VssSig" SG_ 2365543504 MirrorHtOprSig "Mch.KPD1.KEYPADS.MirrorHtOprSig";
BA_ "VssSig" SG_ 2365543504 RrWpWashOprSig "Mch.KPD1.KEYPADS.RrWpWashOprSig";
BA_ "VssSig" SG_ 2365543504 OwdOprSig "Mch.KPD1.KEYPADS.OwdOprSig";
BA_ "VssSig" SG_ 2365543504 BoomLmpOprSig "Mch.KPD1.KEYPADS.BoomLmpOprSig";
BA_ "VssSig" SG_ 2365543504 BeaconLmpOprSig "Mch.KPD1.KEYPADS.BeaconLmpOprSig";
BA_ "VssSig" SG_ 2365543504 RrWrkLmpOprSig "Mch.KPD1.KEYPADS.RrWrkLmpOprSig";
BA_ "VssSig" SG_ 2365543504 FrWrkLmpOprSig "Mch.KPD1.KEYPADS.FrWrkLmpOprSig";
BA_ "VssSig" SG_ 2365543504 HeadLmpOprSig "Mch.KPD1.KEYPADS.HeadLmpOprSig";
BA_ "VssSig" SG_ 2365543713 SelfLvLInd "Mch.MCU.KEYPADI1.SelfLvLInd";
BA_ "VssSig" SG_ 2365543713 SelfLvCtrInd "Mch.MCU.KEYPADI1.SelfLvCtrInd";
BA_ "VssSig" SG_ 2365543713 SelfLvRInd "Mch.MCU.KEYPADI1.SelfLvRInd";
BA_ "VssSig" SG_ 2365543713 TrqCvtLckUpLInd "Mch.MCU.KEYPADI1.TrqCvtLckUpLInd";
BA_ "VssSig" SG_ 2365543713 TrqCvtLckUpCtrInd "Mch.MCU.KEYPADI1.TrqCvtLckUpCtrInd";
BA_ "VssSig" SG_ 2365543713 TrqCvtLckUpRInd "Mch.MCU.KEYPADI1.TrqCvtLckUpRInd";
BA_ "VssSig" SG_ 2365543713 ClutchCutOffLInd "Mch.MCU.KEYPADI1.ClutchCutOffLInd";
BA_ "VssSig" SG_ 2365543713 ClutchCutOffCtrInd "Mch.MCU.KEYPADI1.ClutchCutOffCtrInd";
BA_ "VssSig" SG_ 2365543713 ClutchCutOffRInd "Mch.MCU.KEYPADI1.ClutchCutOffRInd";
BA_ "VssSig" SG_ 2365543713 TrmsMdSelLInd "Mch.MCU.KEYPADI1.TrmsMdSelLInd";
BA_ "VssSig" SG_ 2365543713 TrmsMdSelCtrInd "Mch.MCU.KEYPADI1.TrmsMdSelCtrInd";
BA_ "VssSig" SG_ 2365543713 TrmsMdSelRInd "Mch.MCU.KEYPADI1.TrmsMdSelRInd";
BA_ "VssSig" SG_ 2365543713 MaxSpdDnLInd "Mch.MCU.KEYPADI1.MaxSpdDnLInd";
BA_ "VssSig" SG_ 2365543713 MaxSpdDnCtrInd "Mch.MCU.KEYPADI1.MaxSpdDnCtrInd";
BA_ "VssSig" SG_ 2365543713 MaxSpdDnRInd "Mch.MCU.KEYPADI1.MaxSpdDnRInd";
BA_ "VssSig" SG_ 2365543713 MaxSpdUpLInd "Mch.MCU.KEYPADI1.MaxSpdUpLInd";
BA_ "VssSig" SG_ 2365543713 MaxSpdUpCtrInd "Mch.MCU.KEYPADI1.MaxSpdUpCtrInd";
BA_ "VssSig" SG_ 2365543713 MaxSpdUpRInd "Mch.MCU.KEYPADI1.MaxSpdUpRInd";
BA_ "VssSig" SG_ 2365543713 BckDetentLInd "Mch.MCU.KEYPADI1.BckDetentLInd";
BA_ "VssSig" SG_ 2365543713 BckDetentCtrInd "Mch.MCU.KEYPADI1.BckDetentCtrInd";
BA_ "VssSig" SG_ 2365543713 BckDetentRInd "Mch.MCU.KEYPADI1.BckDetentRInd";
BA_ "VssSig" SG_ 2365543713 BoomDetentLInd "Mch.MCU.KEYPADI1.BoomDetentLInd";
BA_ "VssSig" SG_ 2365543713 BoomDetentCtrInd "Mch.MCU.KEYPADI1.BoomDetentCtrInd";
BA_ "VssSig" SG_ 2365543713 BoomDetentRInd "Mch.MCU.KEYPADI1.BoomDetentRInd";
BA_ "VssSig" SG_ 2365543713 DifLckEngagedLInd "Mch.MCU.KEYPADI1.DifLckEngagedLInd";
BA_ "VssSig" SG_ 2365543713 DifLckEngagedCtrInd "Mch.MCU.KEYPADI1.DifLckEngagedCtrInd";
BA_ "VssSig" SG_ 2365543713 DifLckEngagedRInd "Mch.MCU.KEYPADI1.DifLckEngagedRInd";
BA_ "VssSig" SG_ 2365543713 MdSelLInd "Mch.MCU.KEYPADI1.MdSelLInd";
BA_ "VssSig" SG_ 2365543713 MdSelCtrInd "Mch.MCU.KEYPADI1.MdSelCtrInd";
BA_ "VssSig" SG_ 2365543713 MdSelRInd "Mch.MCU.KEYPADI1.MdSelRInd";
BA_ "VssSig" SG_ 2365543969 HyhLckCtrInd "Mch.MCU.KEYPADMI1.HyhLckCtrInd";
BA_ "VssSig" SG_ 2365543969 AutoidleLInd "Mch.MCU.KEYPADMI1.AutoidleLInd";
BA_ "VssSig" SG_ 2365543969 AutoidleCtrInd "Mch.MCU.KEYPADMI1.AutoidleCtrInd";
BA_ "VssSig" SG_ 2365543969 AutoidleRInd "Mch.MCU.KEYPADMI1.AutoidleRInd";
BA_ "VssSig" SG_ 2365543969 JoyStrLInd "Mch.MCU.KEYPADMI1.JoyStrLInd";
BA_ "VssSig" SG_ 2365543969 JoyStrCtrInd "Mch.MCU.KEYPADMI1.JoyStrCtrInd";
BA_ "VssSig" SG_ 2365543969 JoyStrRInd "Mch.MCU.KEYPADMI1.JoyStrRInd";
BA_ "VssSig" SG_ 2365543969 FineSwgLInd "Mch.MCU.KEYPADMI1.FineSwgLInd";
BA_ "VssSig" SG_ 2365543969 FineSwgCtrInd "Mch.MCU.KEYPADMI1.FineSwgCtrInd";
BA_ "VssSig" SG_ 2365543969 FineSwgRInd "Mch.MCU.KEYPADMI1.FineSwgRInd";
BA_ "VssSig" SG_ 2365543969 TrailerHitchBrkLInd "Mch.MCU.KEYPADMI1.TrailerHitchBrkLInd";
BA_ "VssSig" SG_ 2365543969 TrailerHitchBrkCtrInd "Mch.MCU.KEYPADMI1.TrailerHitchBrkCtrInd";
BA_ "VssSig" SG_ 2365543969 TrailerHitchRInd "Mch.MCU.KEYPADMI1.TrailerHitchRInd";
BA_ "VssSig" SG_ 2365543969 AutoDigBrkLInd "Mch.MCU.KEYPADMI1.AutoDigBrkLInd";
BA_ "VssSig" SG_ 2365543969 AutoDigBrkCtrInd "Mch.MCU.KEYPADMI1.AutoDigBrkCtrInd";
BA_ "VssSig" SG_ 2365543969 AutoDigBrkRInd "Mch.MCU.KEYPADMI1.AutoDigBrkRInd";
BA_ "VssSig" SG_ 2365543969 BoomSwgMdLInd "Mch.MCU.KEYPADMI1.BoomSwgMdLInd";
BA_ "VssSig" SG_ 2365543969 BoomSwgMdCtrInd "Mch.MCU.KEYPADMI1.BoomSwgMdCtrInd";
BA_ "VssSig" SG_ 2365543969 BoomSwgMdRInd "Mch.MCU.KEYPADMI1.BoomSwgMdRInd";
BA_ "VssSig" SG_ 2365543969 WrkMdLInd "Mch.MCU.KEYPADMI1.WrkMdLInd";
BA_ "VssSig" SG_ 2365543969 WrkMdCtrInd "Mch.MCU.KEYPADMI1.WrkMdCtrInd";
BA_ "VssSig" SG_ 2365543969 WrkMdRInd "Mch.MCU.KEYPADMI1.WrkMdRInd";
BA_ "VssSig" SG_ 2365543969 PwrMdLInd "Mch.MCU.KEYPADMI1.PwrMdLInd";
BA_ "VssSig" SG_ 2365543969 PwrMdCtrInd "Mch.MCU.KEYPADMI1.PwrMdCtrInd";
BA_ "VssSig" SG_ 2365543969 PwrMdRInd "Mch.MCU.KEYPADMI1.PwrMdRInd";
BA_ "VssSig" SG_ 2365543969 TrvlAlmLInd "Mch.MCU.KEYPADMI1.TrvlAlmLInd";
BA_ "VssSig" SG_ 2365543969 TrvlAlmCtrInd "Mch.MCU.KEYPADMI1.TrvlAlmCtrInd";
BA_ "VssSig" SG_ 2365543969 TrvlAlmRInd "Mch.MCU.KEYPADMI1.TrvlAlmRInd";
BA_ "VssSig" SG_ 2365543969 OwdLInd "Mch.MCU.KEYPADMI1.OwdLInd";
BA_ "VssSig" SG_ 2365543969 OwdCtrInd "Mch.MCU.KEYPADMI1.OwdCtrInd";
BA_ "VssSig" SG_ 2365543969 OwdRInd "Mch.MCU.KEYPADMI1.OwdRInd";
BA_ "VssSig" SG_ 2365544225 SwgLckLInd "Mch.MCU.KEYPADMI2.SwgLckLInd";
BA_ "VssSig" SG_ 2365544225 SwgLckCtrInd "Mch.MCU.KEYPADMI2.SwgLckCtrInd";
BA_ "VssSig" SG_ 2365544225 SwgLckRInd "Mch.MCU.KEYPADMI2.SwgLckRInd";
BA_ "VssSig" SG_ 2365544225 BoomFltLInd "Mch.MCU.KEYPADMI2.BoomFltLInd";
BA_ "VssSig" SG_ 2365544225 BoomFltCtrInd "Mch.MCU.KEYPADMI2.BoomFltCtrInd";
BA_ "VssSig" SG_ 2365544225 BoomFltRInd "Mch.MCU.KEYPADMI2.BoomFltRInd";
BA_ "VssSig" SG_ 2365544225 BoomLisLInd "Mch.MCU.KEYPADMI2.BoomLisLInd";
BA_ "VssSig" SG_ 2365544225 BoomLisCtrInd "Mch.MCU.KEYPADMI2.BoomLisCtrInd";
BA_ "VssSig" SG_ 2365544225 BoomLisRInd "Mch.MCU.KEYPADMI2.BoomLisRInd";
BA_ "VssSig" SG_ 2365544225 CrabRoundSelLInd "Mch.MCU.KEYPADMI2.CrabRoundSelLInd";
BA_ "VssSig" SG_ 2365544225 CrabRoundSelCtrInd "Mch.MCU.KEYPADMI2.CrabRoundSelCtrInd";
BA_ "VssSig" SG_ 2365544225 CrabRoundSelRInd "Mch.MCU.KEYPADMI2.CrabRoundSelRInd";
BA_ "VssSig" SG_ 2365544225 TwoWhlFourWhlSelLInd "Mch.MCU.KEYPADMI2.TwoWhlFourWhlSelLInd";
BA_ "VssSig" SG_ 2365544225 TwoWhlFourWhlSelCtrInd "Mch.MCU.KEYPADMI2.TwoWhlFourWhlSelCtrInd";
BA_ "VssSig" SG_ 2365544225 TwoWhlFourWhlSelRInd "Mch.MCU.KEYPADMI2.TwoWhlFourWhlSelRInd";
BA_ "VssSig" SG_ 2365544225 OtrgAllLInd "Mch.MCU.KEYPADMI2.OtrgAllLInd";
BA_ "VssSig" SG_ 2365544225 OtrgAllCtrInd "Mch.MCU.KEYPADMI2.OtrgAllCtrInd";
BA_ "VssSig" SG_ 2365544225 OtrgAllRInd "Mch.MCU.KEYPADMI2.OtrgAllRInd";
BA_ "VssSig" SG_ 2365544225 OtrgRrRLInd "Mch.MCU.KEYPADMI2.OtrgRrRLInd";
BA_ "VssSig" SG_ 2365544225 OtrgRrRCtrInd "Mch.MCU.KEYPADMI2.OtrgRrRCtrInd";
BA_ "VssSig" SG_ 2365544225 OtrgRrRRInd "Mch.MCU.KEYPADMI2.OtrgRrRRInd";
BA_ "VssSig" SG_ 2365544225 OtrgRrLLInd "Mch.MCU.KEYPADMI2.OtrgRrLLInd";
BA_ "VssSig" SG_ 2365544225 OtrgRrLCtrInd "Mch.MCU.KEYPADMI2.OtrgRrLCtrInd";
BA_ "VssSig" SG_ 2365544225 OtrgRrLRInd "Mch.MCU.KEYPADMI2.OtrgRrLRInd";
BA_ "VssSig" SG_ 2365544225 OtrgFrRLInd "Mch.MCU.KEYPADMI2.OtrgFrRLInd";
BA_ "VssSig" SG_ 2365544225 OtrgFrRCtrInd "Mch.MCU.KEYPADMI2.OtrgFrRCtrInd";
BA_ "VssSig" SG_ 2365544225 OtrgFrRRInd "Mch.MCU.KEYPADMI2.OtrgFrRRInd";
BA_ "VssSig" SG_ 2365544225 OtrgFrLLInd "Mch.MCU.KEYPADMI2.OtrgFrLLInd";
BA_ "VssSig" SG_ 2365544225 OtrgFrLCtrInd "Mch.MCU.KEYPADMI2.OtrgFrLCtrInd";
BA_ "VssSig" SG_ 2365544225 OtrgFrLRInd "Mch.MCU.KEYPADMI2.OtrgFrLRInd";
BA_ "VssSig" SG_ 2365544481 Aux8LInd "Mch.MCU.KEYPADI2.Aux8LInd";
BA_ "VssSig" SG_ 2365544481 Aux8CtrInd "Mch.MCU.KEYPADI2.Aux8CtrInd";
BA_ "VssSig" SG_ 2365544481 Aux8RInd "Mch.MCU.KEYPADI2.Aux8RInd";
BA_ "VssSig" SG_ 2365544481 Aux7LInd "Mch.MCU.KEYPADI2.Aux7LInd";
BA_ "VssSig" SG_ 2365544481 Aux7CtrInd "Mch.MCU.KEYPADI2.Aux7CtrInd";
BA_ "VssSig" SG_ 2365544481 Aux7RInd "Mch.MCU.KEYPADI2.Aux7RInd";
BA_ "VssSig" SG_ 2365544481 ContinuousFlowLInd "Mch.MCU.KEYPADI2.ContinuousFlowLInd";
BA_ "VssSig" SG_ 2365544481 ContinuousFlowCtrInd "Mch.MCU.KEYPADI2.ContinuousFlowCtrInd";
BA_ "VssSig" SG_ 2365544481 ContinuousFlowRInd "Mch.MCU.KEYPADI2.ContinuousFlowRInd";
BA_ "VssSig" SG_ 2365544481 InterlockOverrideLInd "Mch.MCU.KEYPADI2.InterlockOverrideLInd";
BA_ "VssSig" SG_ 2365544481 InterlockOverrideCtrInd "Mch.MCU.KEYPADI2.InterlockOverrideCtrInd";
BA_ "VssSig" SG_ 2365544481 InterlockOverrideRInd "Mch.MCU.KEYPADI2.InterlockOverrideRInd";
BA_ "VssSig" SG_ 2365544481 ShakeCtrlLInd "Mch.MCU.KEYPADI2.ShakeCtrlLInd";
BA_ "VssSig" SG_ 2365544481 ShakeCtrlCtrInd "Mch.MCU.KEYPADI2.ShakeCtrlCtrInd";
BA_ "VssSig" SG_ 2365544481 ShakeCtrlRInd "Mch.MCU.KEYPADI2.ShakeCtrlRInd";
BA_ "VssSig" SG_ 2365544481 ThrottleLckUpLInd "Mch.MCU.KEYPADI2.ThrottleLckUpLInd";
BA_ "VssSig" SG_ 2365544481 ThrottleLckUpCtrInd "Mch.MCU.KEYPADI2.ThrottleLckUpCtrInd";
BA_ "VssSig" SG_ 2365544481 ThrottleLckUpRInd "Mch.MCU.KEYPADI2.ThrottleLckUpRInd";
BA_ "VssSig" SG_ 2365544481 TractionCtrlMdLInd "Mch.MCU.KEYPADI2.TractionCtrlMdLInd";
BA_ "VssSig" SG_ 2365544481 TractionCtrlMdCtrInd "Mch.MCU.KEYPADI2.TractionCtrlMdCtrInd";
BA_ "VssSig" SG_ 2365544481 TractionCtrlMdRInd "Mch.MCU.KEYPADI2.TractionCtrlMdRInd";
BA_ "VssSig" SG_ 2365544481 VariableSpdDnLInd "Mch.MCU.KEYPADI2.VariableSpdDnLInd";
BA_ "VssSig" SG_ 2365544481 VariableSpdDnCtrInd "Mch.MCU.KEYPADI2.VariableSpdDnCtrInd";
BA_ "VssSig" SG_ 2365544481 VariableSpdDnRInd "Mch.MCU.KEYPADI2.VariableSpdDnRInd";
BA_ "VssSig" SG_ 2365544481 VariableSpdUpLInd "Mch.MCU.KEYPADI2.VariableSpdUpLInd";
BA_ "VssSig" SG_ 2365544481 VariableSpdUpCtrInd "Mch.MCU.KEYPADI2.VariableSpdUpCtrInd";
BA_ "VssSig" SG_ 2365544481 VariableSpdUpRInd "Mch.MCU.KEYPADI2.VariableSpdUpRInd";
BA_ "VssSig" SG_ 2365544737 TrkExpansionLInd "Mch.MCU.KEYPADI3.TrkExpansionLInd";
BA_ "VssSig" SG_ 2365544737 TrkExpansionCtrInd "Mch.MCU.KEYPADI3.TrkExpansionCtrInd";
BA_ "VssSig" SG_ 2365544737 TrkExpansionRInd "Mch.MCU.KEYPADI3.TrkExpansionRInd";
BA_ "VssSig" SG_ 2365544737 FrWpLInd "Mch.MCU.KEYPADI3.FrWpLInd";
BA_ "VssSig" SG_ 2365544737 FrWpCtrInd "Mch.MCU.KEYPADI3.FrWpCtrInd";
BA_ "VssSig" SG_ 2365544737 FrWpRInd "Mch.MCU.KEYPADI3.FrWpRInd";
BA_ "VssSig" SG_ 2365544737 RrWpLInd "Mch.MCU.KEYPADI3.RrWpLInd";
BA_ "VssSig" SG_ 2365544737 RrWpCtrInd "Mch.MCU.KEYPADI3.RrWpCtrInd";
BA_ "VssSig" SG_ 2365544737 RrWpRInd "Mch.MCU.KEYPADI3.RrWpRInd";
BA_ "VssSig" SG_ 2365544737 SideWpLInd "Mch.MCU.KEYPADI3.SideWpLInd";
BA_ "VssSig" SG_ 2365544737 SideWpCtrInd "Mch.MCU.KEYPADI3.SideWpCtrInd";
BA_ "VssSig" SG_ 2365544737 SideWpRInd "Mch.MCU.KEYPADI3.SideWpRInd";
BA_ "VssSig" SG_ 2365544737 FrWpWashLInd "Mch.MCU.KEYPADI3.FrWpWashLInd";
BA_ "VssSig" SG_ 2365544737 FrWpWashCtrInd "Mch.MCU.KEYPADI3.FrWpWashCtrInd";
BA_ "VssSig" SG_ 2365544737 FrWpWashRInd "Mch.MCU.KEYPADI3.FrWpWashRInd";
BA_ "VssSig" SG_ 2365544737 SideWpWashLInd "Mch.MCU.KEYPADI3.SideWpWashLInd";
BA_ "VssSig" SG_ 2365544737 SideWpWashCtrInd "Mch.MCU.KEYPADI3.SideWpWashCtrInd";
BA_ "VssSig" SG_ 2365544737 SideWpWashRInd "Mch.MCU.KEYPADI3.SideWpWashRInd";
BA_ "VssSig" SG_ 2365544737 RrMirrorHtLInd "Mch.MCU.KEYPADI3.RrMirrorHtLInd";
BA_ "VssSig" SG_ 2365544737 RrMirrorHtCtrInd "Mch.MCU.KEYPADI3.RrMirrorHtCtrInd";
BA_ "VssSig" SG_ 2365544737 RrMirrorHtRInd "Mch.MCU.KEYPADI3.RrMirrorHtRInd";
BA_ "VssSig" SG_ 2365544737 AirCompLInd "Mch.MCU.KEYPADI3.AirCompLInd";
BA_ "VssSig" SG_ 2365544737 AirCompCtrInd "Mch.MCU.KEYPADI3.AirCompCtrInd";
BA_ "VssSig" SG_ 2365544737 AirCompRInd "Mch.MCU.KEYPADI3.AirCompRInd";
BA_ "VssSig" SG_ 2365544737 TrvlSpdLInd "Mch.MCU.KEYPADI3.TrvlSpdLInd";
BA_ "VssSig" SG_ 2365544737 TrvlSpdCtrInd "Mch.MCU.KEYPADI3.TrvlSpdCtrInd";
BA_ "VssSig" SG_ 2365544737 TrvlSpdRInd "Mch.MCU.KEYPADI3.TrvlSpdRInd";
BA_ "VssSig" SG_ 2365544737 BzStopLInd "Mch.MCU.KEYPADI3.BzStopLInd";
BA_ "VssSig" SG_ 2365544737 BzStopCtrInd "Mch.MCU.KEYPADI3.BzStopCtrInd";
BA_ "VssSig" SG_ 2365544737 BzStopRInd "Mch.MCU.KEYPADI3.BzStopRInd";
BA_ "VssSig" SG_ 2566871629 HornSwIn "Mch.CBSW.HCMD.HornSwIn";
BA_ "VssSig" SG_ 2566872001 AccRate "Mch.IMU1.ASI.AccRate";
BA_ "VssSig" SG_ 2566872002 AccRate "Mch.IMU2.ASI.AccRate";
BA_ "VssSig" SG_ 2566872003 AccRate "Mch.IMU3.ASI.AccRate";
BA_ "VssSig" SG_ 2566872004 AccRate "Mch.IMU4.ASI.AccRate";
BA_ "VssSig" SG_ 2566872005 AccRate "Mch.IMU5.ASI.AccRate";
BA_ "VssSig" SG_ 2365545552 BoomFltOprSig "Mch.KPD1.KEYPADS2.BoomFltOprSig";
BA_ "VssSig" SG_ 2365545552 SwgLckOprSig "Mch.KPD1.KEYPADS2.SwgLckOprSig";
BA_ "VssSig" SG_ 2365545552 HpApMdSelOprSig "Mch.KPD1.KEYPADS2.HpApMdSelOprSig";
BA_ "VssSig" SG_ 2365545761 OutTrgDzShortcutLInd "Mch.MCU.KEYPADI4.OutTrgDzShortcutLInd";
BA_ "VssSig" SG_ 2365545761 OutTrgDzShortcutCtrInd "Mch.MCU.KEYPADI4.OutTrgDzShortcutCtrInd";
BA_ "VssSig" SG_ 2365545761 OutTrgDzShortcutRInd "Mch.MCU.KEYPADI4.OutTrgDzShortcutRInd";
BA_ "VssSig" SG_ 2365545761 BoomFltLInd "Mch.MCU.KEYPADI4.BoomFltLInd";
BA_ "VssSig" SG_ 2365545761 BoomFltCtrInd "Mch.MCU.KEYPADI4.BoomFltCtrInd";
BA_ "VssSig" SG_ 2365545761 BoomFltRInd "Mch.MCU.KEYPADI4.BoomFltRInd";
BA_ "VssSig" SG_ 2365545761 SwgLckLInd "Mch.MCU.KEYPADI4.SwgLckLInd";
BA_ "VssSig" SG_ 2365545761 SwgLckCtrInd "Mch.MCU.KEYPADI4.SwgLckCtrInd";
BA_ "VssSig" SG_ 2365545761 SwgLckRInd "Mch.MCU.KEYPADI4.SwgLckRInd";
BA_ "VssSig" SG_ 2365545761 HpApMdLInd "Mch.MCU.KEYPADI4.HpApMdLInd";
BA_ "VssSig" SG_ 2365545761 HpApMdCtrInd "Mch.MCU.KEYPADI4.HpApMdCtrInd";
BA_ "VssSig" SG_ 2365545761 HpApMdRInd "Mch.MCU.KEYPADI4.HpApMdRInd";
BA_ "VssSig" SG_ 2566873377 LowOutReq8 "Mch.MCU.ACUCTR.LowOutReq8";
BA_ "VssSig" SG_ 2566873377 LowOutReq7 "Mch.MCU.ACUCTR.LowOutReq7";
BA_ "VssSig" SG_ 2566873377 LowOutReq6 "Mch.MCU.ACUCTR.LowOutReq6";
BA_ "VssSig" SG_ 2566873377 LowOutReq5 "Mch.MCU.ACUCTR.LowOutReq5";
BA_ "VssSig" SG_ 2566873377 LowOutReq4 "Mch.MCU.ACUCTR.LowOutReq4";
BA_ "VssSig" SG_ 2566873377 LowOutReq3 "Mch.MCU.ACUCTR.LowOutReq3";
BA_ "VssSig" SG_ 2566873377 LowOutReq2 "Mch.MCU.ACUCTR.LowOutReq2";
BA_ "VssSig" SG_ 2566873377 LowOutReq1 "Mch.MCU.ACUCTR.LowOutReq1";
BA_ "VssSig" SG_ 2566873377 OutReq15 "Mch.MCU.ACUCTR.OutReq15";
BA_ "VssSig" SG_ 2566873377 OutReq14 "Mch.MCU.ACUCTR.OutReq14";
BA_ "VssSig" SG_ 2566873377 OutReq13 "Mch.MCU.ACUCTR.OutReq13";
BA_ "VssSig" SG_ 2566873377 OutReq12 "Mch.MCU.ACUCTR.OutReq12";
BA_ "VssSig" SG_ 2566873377 OutReq11 "Mch.MCU.ACUCTR.OutReq11";
BA_ "VssSig" SG_ 2566873377 OutReq10 "Mch.MCU.ACUCTR.OutReq10";
BA_ "VssSig" SG_ 2566873377 OutReq9 "Mch.MCU.ACUCTR.OutReq9";
BA_ "VssSig" SG_ 2566873377 OutReq8 "Mch.MCU.ACUCTR.OutReq8";
BA_ "VssSig" SG_ 2566873377 OutReq7 "Mch.MCU.ACUCTR.OutReq7";
BA_ "VssSig" SG_ 2566873377 OutReq6 "Mch.MCU.ACUCTR.OutReq6";
BA_ "VssSig" SG_ 2566873377 OutReq5 "Mch.MCU.ACUCTR.OutReq5";
BA_ "VssSig" SG_ 2566873377 OutReq4 "Mch.MCU.ACUCTR.OutReq4";
BA_ "VssSig" SG_ 2566873377 OutReq3 "Mch.MCU.ACUCTR.OutReq3";
BA_ "VssSig" SG_ 2566873377 OutReq2 "Mch.MCU.ACUCTR.OutReq2";
BA_ "VssSig" SG_ 2566873377 OutReq1 "Mch.MCU.ACUCTR.OutReq1";
BA_ "VssSig" SG_ 2566873630 OutFdbkCur8 "Mch.ACU.ACUFB1.OutFdbkCur8";
BA_ "VssSig" SG_ 2566873630 OutFdbkCur7 "Mch.ACU.ACUFB1.OutFdbkCur7";
BA_ "VssSig" SG_ 2566873630 OutFdbkCur6 "Mch.ACU.ACUFB1.OutFdbkCur6";
BA_ "VssSig" SG_ 2566873630 OutFdbkCur5 "Mch.ACU.ACUFB1.OutFdbkCur5";
BA_ "VssSig" SG_ 2566873630 OutFdbkCur4 "Mch.ACU.ACUFB1.OutFdbkCur4";
BA_ "VssSig" SG_ 2566873630 OutFdbkCur3 "Mch.ACU.ACUFB1.OutFdbkCur3";
BA_ "VssSig" SG_ 2566873630 OutFdbkCur2 "Mch.ACU.ACUFB1.OutFdbkCur2";
BA_ "VssSig" SG_ 2566873630 OutFdbkCur1 "Mch.ACU.ACUFB1.OutFdbkCur1";
BA_ "VssSig" SG_ 2566873767 OutFdbkCur8 "Mch.SMB.ACUFB1.OutFdbkCur8";
BA_ "VssSig" SG_ 2566873767 OutFdbkCur7 "Mch.SMB.ACUFB1.OutFdbkCur7";
BA_ "VssSig" SG_ 2566873767 OutFdbkCur6 "Mch.SMB.ACUFB1.OutFdbkCur6";
BA_ "VssSig" SG_ 2566873767 OutFdbkCur5 "Mch.SMB.ACUFB1.OutFdbkCur5";
BA_ "VssSig" SG_ 2566873767 OutFdbkCur4 "Mch.SMB.ACUFB1.OutFdbkCur4";
BA_ "VssSig" SG_ 2566873767 OutFdbkCur3 "Mch.SMB.ACUFB1.OutFdbkCur3";
BA_ "VssSig" SG_ 2566873767 OutFdbkCur2 "Mch.SMB.ACUFB1.OutFdbkCur2";
BA_ "VssSig" SG_ 2566873767 OutFdbkCur1 "Mch.SMB.ACUFB1.OutFdbkCur1";
BA_ "VssSig" SG_ 2566873886 ErrorFlag "Mch.ACU.ACUFB2.ErrorFlag";
BA_ "VssSig" SG_ 2566873886 VltIn2 "Mch.ACU.ACUFB2.VltIn2";
BA_ "VssSig" SG_ 2566873886 VltIn1 "Mch.ACU.ACUFB2.VltIn1";
BA_ "VssSig" SG_ 2566873886 OutFdbkCur13 "Mch.ACU.ACUFB2.OutFdbkCur13";
BA_ "VssSig" SG_ 2566873886 OutFdbkCur12 "Mch.ACU.ACUFB2.OutFdbkCur12";
BA_ "VssSig" SG_ 2566873886 OutFdbkCur11 "Mch.ACU.ACUFB2.OutFdbkCur11";
BA_ "VssSig" SG_ 2566873886 OutFdbkCur10 "Mch.ACU.ACUFB2.OutFdbkCur10";
BA_ "VssSig" SG_ 2566873886 OutFdbkCur9 "Mch.ACU.ACUFB2.OutFdbkCur9";
BA_ "VssSig" SG_ 2566874654 OutFdbkActvLowCur8 "Mch.ACU.ACUFB3.OutFdbkActvLowCur8";
BA_ "VssSig" SG_ 2566874654 OutFdbkActvLowCur7 "Mch.ACU.ACUFB3.OutFdbkActvLowCur7";
BA_ "VssSig" SG_ 2566874654 OutFdbkActvLowCur6 "Mch.ACU.ACUFB3.OutFdbkActvLowCur6";
BA_ "VssSig" SG_ 2566874654 OutFdbkActvLowCur5 "Mch.ACU.ACUFB3.OutFdbkActvLowCur5";
BA_ "VssSig" SG_ 2566874654 OutFdbkActvLowCur4 "Mch.ACU.ACUFB3.OutFdbkActvLowCur4";
BA_ "VssSig" SG_ 2566874654 OutFdbkActvLowCur3 "Mch.ACU.ACUFB3.OutFdbkActvLowCur3";
BA_ "VssSig" SG_ 2566874654 OutFdbkActvLowCur2 "Mch.ACU.ACUFB3.OutFdbkActvLowCur2";
BA_ "VssSig" SG_ 2566874654 OutFdbkActvLowCur1 "Mch.ACU.ACUFB3.OutFdbkActvLowCur1";
BA_ "VssSig" SG_ 2566874654 OutFdbkActvHighCur15 "Mch.ACU.ACUFB3.OutFdbkActvHighCur15";
BA_ "VssSig" SG_ 2566874654 OutFdbkActvHighCur14 "Mch.ACU.ACUFB3.OutFdbkActvHighCur14";
BA_ "VssSig" SG_ 2566874654 OutFdbkActvHighCur13 "Mch.ACU.ACUFB3.OutFdbkActvHighCur13";
BA_ "VssSig" SG_ 2566874654 OutFdbkActvHighCur12 "Mch.ACU.ACUFB3.OutFdbkActvHighCur12";
BA_ "VssSig" SG_ 2566874654 OutFdbkActvHighCur11 "Mch.ACU.ACUFB3.OutFdbkActvHighCur11";
BA_ "VssSig" SG_ 2566874654 OutFdbkActvHighCur10 "Mch.ACU.ACUFB3.OutFdbkActvHighCur10";
BA_ "VssSig" SG_ 2566874654 OutFdbkActvHighCur9 "Mch.ACU.ACUFB3.OutFdbkActvHighCur9";
BA_ "VssSig" SG_ 2566874654 OutFdbkActvHighCur8 "Mch.ACU.ACUFB3.OutFdbkActvHighCur8";
BA_ "VssSig" SG_ 2566874654 OutFdbkActvHighCur7 "Mch.ACU.ACUFB3.OutFdbkActvHighCur7";
BA_ "VssSig" SG_ 2566874654 OutFdbkActvHighCur6 "Mch.ACU.ACUFB3.OutFdbkActvHighCur6";
BA_ "VssSig" SG_ 2566874654 OutFdbkActvHighCur5 "Mch.ACU.ACUFB3.OutFdbkActvHighCur5";
BA_ "VssSig" SG_ 2566874654 OutFdbkActvHighCur4 "Mch.ACU.ACUFB3.OutFdbkActvHighCur4";
BA_ "VssSig" SG_ 2566874654 OutFdbkActvHighCur3 "Mch.ACU.ACUFB3.OutFdbkActvHighCur3";
BA_ "VssSig" SG_ 2566874654 OutFdbkActvHighCur2 "Mch.ACU.ACUFB3.OutFdbkActvHighCur2";
BA_ "VssSig" SG_ 2566874654 OutFdbkActvHighCur1 "Mch.ACU.ACUFB3.OutFdbkActvHighCur1";
BA_ "VssSig" SG_ 2566874910 InVlt12 "Mch.ACU.ACUFB4.InVlt12";
BA_ "VssSig" SG_ 2566874910 InVlt11 "Mch.ACU.ACUFB4.InVlt11";
BA_ "VssSig" SG_ 2566874910 InVlt10 "Mch.ACU.ACUFB4.InVlt10";
BA_ "VssSig" SG_ 2566874910 InVlt9 "Mch.ACU.ACUFB4.InVlt9";
BA_ "VssSig" SG_ 2566874910 InVlt8 "Mch.ACU.ACUFB4.InVlt8";
BA_ "VssSig" SG_ 2566874910 InVlt7 "Mch.ACU.ACUFB4.InVlt7";
BA_ "VssSig" SG_ 2566874910 InVlt6 "Mch.ACU.ACUFB4.InVlt6";
BA_ "VssSig" SG_ 2566874910 InVlt5 "Mch.ACU.ACUFB4.InVlt5";
BA_ "VssSig" SG_ 2566874910 InVlt4 "Mch.ACU.ACUFB4.InVlt4";
BA_ "VssSig" SG_ 2566874910 InVlt3 "Mch.ACU.ACUFB4.InVlt3";
BA_ "VssSig" SG_ 2566874910 InVlt2 "Mch.ACU.ACUFB4.InVlt2";
BA_ "VssSig" SG_ 2566874910 InVlt1 "Mch.ACU.ACUFB4.InVlt1";
BA_ "VssSig" SG_ 2566875297 HvacOffSel "Mch.KPAC.ACCMD.HvacOffSel";
BA_ "VssSig" SG_ 2566875297 BlowerDnSig "Mch.KPAC.ACCMD.BlowerDnSig";
BA_ "VssSig" SG_ 2566875297 BlowerUpSig "Mch.KPAC.ACCMD.BlowerUpSig";
BA_ "VssSig" SG_ 2566875297 DefMdSel "Mch.KPAC.ACCMD.DefMdSel";
BA_ "VssSig" SG_ 2566875297 BlowMdSelSig "Mch.KPAC.ACCMD.BlowMdSelSig";
BA_ "VssSig" SG_ 2566875297 MnAutoMdSel "Mch.KPAC.ACCMD.MnAutoMdSel";
BA_ "VssSig" SG_ 2566875297 TmpDnSig "Mch.KPAC.ACCMD.TmpDnSig";
BA_ "VssSig" SG_ 2566875297 TmpUpSig "Mch.KPAC.ACCMD.TmpUpSig";
BA_ "VssSig" SG_ 2566875297 OuttakeIntakeMdSel "Mch.KPAC.ACCMD.OuttakeIntakeMdSel";
BA_ "VssSig" SG_ 2566875297 AcMdSel "Mch.KPAC.ACCMD.AcMdSel";
BA_ "VssSig" SG_ 2566875422 OutFdbkCur12 "Mch.ACU.ACUFB5.OutFdbkCur12";
BA_ "VssSig" SG_ 2566875422 OutFdbkCur11 "Mch.ACU.ACUFB5.OutFdbkCur11";
BA_ "VssSig" SG_ 2566875422 OutFdbkCur10 "Mch.ACU.ACUFB5.OutFdbkCur10";
BA_ "VssSig" SG_ 2566875422 OutFdbkCur9 "Mch.ACU.ACUFB5.OutFdbkCur9";
BA_ "VssSig" SG_ 2566875559 OutFdbkCur12 "Mch.SMB.ACUFB5.OutFdbkCur12";
BA_ "VssSig" SG_ 2566875559 OutFdbkCur11 "Mch.SMB.ACUFB5.OutFdbkCur11";
BA_ "VssSig" SG_ 2566875559 OutFdbkCur10 "Mch.SMB.ACUFB5.OutFdbkCur10";
BA_ "VssSig" SG_ 2566875559 OutFdbkCur9 "Mch.SMB.ACUFB5.OutFdbkCur9";
BA_ "VssSig" SG_ 2566875678 MiniRly30AFuse2St "Mch.ACU.ACUFB6.MiniRly30AFuse2St";
BA_ "VssSig" SG_ 2566875678 MiniRly30AFuse1St "Mch.ACU.ACUFB6.MiniRly30AFuse1St";
BA_ "VssSig" SG_ 2566875678 MicroRly20AFuse5St "Mch.ACU.ACUFB6.MicroRly20AFuse5St";
BA_ "VssSig" SG_ 2566875678 MicroRly20AFuse4St "Mch.ACU.ACUFB6.MicroRly20AFuse4St";
BA_ "VssSig" SG_ 2566875678 MicroRly20AFuse3St "Mch.ACU.ACUFB6.MicroRly20AFuse3St";
BA_ "VssSig" SG_ 2566875678 MicroRly20AFuse2St "Mch.ACU.ACUFB6.MicroRly20AFuse2St";
BA_ "VssSig" SG_ 2566875678 MicroRly20AFuse1St "Mch.ACU.ACUFB6.MicroRly20AFuse1St";
BA_ "VssSig" SG_ 2566875678 KeyOn30AFuse5St "Mch.ACU.ACUFB6.KeyOn30AFuse5St";
BA_ "VssSig" SG_ 2566875678 KeyOn30AFuse4St "Mch.ACU.ACUFB6.KeyOn30AFuse4St";
BA_ "VssSig" SG_ 2566875678 KeyOn30AFuse3St "Mch.ACU.ACUFB6.KeyOn30AFuse3St";
BA_ "VssSig" SG_ 2566875678 KeyOn30AFuse2St "Mch.ACU.ACUFB6.KeyOn30AFuse2St";
BA_ "VssSig" SG_ 2566875678 KeyOn30AFuse1St "Mch.ACU.ACUFB6.KeyOn30AFuse1St";
BA_ "VssSig" SG_ 2566875678 KeyOn20AFuse10St "Mch.ACU.ACUFB6.KeyOn20AFuse10St";
BA_ "VssSig" SG_ 2566875678 KeyOn20AFuse9St "Mch.ACU.ACUFB6.KeyOn20AFuse9St";
BA_ "VssSig" SG_ 2566875678 KeyOn20AFuse8St "Mch.ACU.ACUFB6.KeyOn20AFuse8St";
BA_ "VssSig" SG_ 2566875678 KeyOn20AFuse7St "Mch.ACU.ACUFB6.KeyOn20AFuse7St";
BA_ "VssSig" SG_ 2566875678 KeyOn20AFuse6St "Mch.ACU.ACUFB6.KeyOn20AFuse6St";
BA_ "VssSig" SG_ 2566875678 KeyOn20AFuse5St "Mch.ACU.ACUFB6.KeyOn20AFuse5St";
BA_ "VssSig" SG_ 2566875678 KeyOn20AFuse4St "Mch.ACU.ACUFB6.KeyOn20AFuse4St";
BA_ "VssSig" SG_ 2566875678 KeyOn20AFuse3St "Mch.ACU.ACUFB6.KeyOn20AFuse3St";
BA_ "VssSig" SG_ 2566875678 KeyOn20AFuse2St "Mch.ACU.ACUFB6.KeyOn20AFuse2St";
BA_ "VssSig" SG_ 2566875678 KeyOn20AFuse1St "Mch.ACU.ACUFB6.KeyOn20AFuse1St";
BA_ "VssSig" SG_ 2566875678 KeyOn10AFuse5St "Mch.ACU.ACUFB6.KeyOn10AFuse5St";
BA_ "VssSig" SG_ 2566875678 KeyOn10AFuse4St "Mch.ACU.ACUFB6.KeyOn10AFuse4St";
BA_ "VssSig" SG_ 2566875678 KeyOn10AFuse3St "Mch.ACU.ACUFB6.KeyOn10AFuse3St";
BA_ "VssSig" SG_ 2566875678 KeyOn10AFuse2St "Mch.ACU.ACUFB6.KeyOn10AFuse2St";
BA_ "VssSig" SG_ 2566875678 KeyOn10AFuse1St "Mch.ACU.ACUFB6.KeyOn10AFuse1St";
BA_ "VssSig" SG_ 2566875678 KeyOn5AFuse15St "Mch.ACU.ACUFB6.KeyOn5AFuse15St";
BA_ "VssSig" SG_ 2566875678 KeyOn5AFuse14St "Mch.ACU.ACUFB6.KeyOn5AFuse14St";
BA_ "VssSig" SG_ 2566875678 KeyOn5AFuse13St "Mch.ACU.ACUFB6.KeyOn5AFuse13St";
BA_ "VssSig" SG_ 2566875678 KeyOn5AFuse12St "Mch.ACU.ACUFB6.KeyOn5AFuse12St";
BA_ "VssSig" SG_ 2566875678 KeyOn5AFuse11St "Mch.ACU.ACUFB6.KeyOn5AFuse11St";
BA_ "VssSig" SG_ 2566875678 KeyOn5AFuse10St "Mch.ACU.ACUFB6.KeyOn5AFuse10St";
BA_ "VssSig" SG_ 2566875678 KeyOn5AFuse9St "Mch.ACU.ACUFB6.KeyOn5AFuse9St";
BA_ "VssSig" SG_ 2566875678 KeyOn5AFuse8St "Mch.ACU.ACUFB6.KeyOn5AFuse8St";
BA_ "VssSig" SG_ 2566875678 KeyOn5AFuse7St "Mch.ACU.ACUFB6.KeyOn5AFuse7St";
BA_ "VssSig" SG_ 2566875678 KeyOn5AFuse6St "Mch.ACU.ACUFB6.KeyOn5AFuse6St";
BA_ "VssSig" SG_ 2566875678 KeyOn5AFuse5St "Mch.ACU.ACUFB6.KeyOn5AFuse5St";
BA_ "VssSig" SG_ 2566875678 KeyOn5AFuse4St "Mch.ACU.ACUFB6.KeyOn5AFuse4St";
BA_ "VssSig" SG_ 2566875678 KeyOn5AFuse3St "Mch.ACU.ACUFB6.KeyOn5AFuse3St";
BA_ "VssSig" SG_ 2566875678 KeyOn5AFuse2St "Mch.ACU.ACUFB6.KeyOn5AFuse2St";
BA_ "VssSig" SG_ 2566875678 KeyOn5AFuse1St "Mch.ACU.ACUFB6.KeyOn5AFuse1St";
BA_ "VssSig" SG_ 2566875678 BPlus30AFuse5St "Mch.ACU.ACUFB6.BPlus30AFuse5St";
BA_ "VssSig" SG_ 2566875678 BPlus30AFuse4St "Mch.ACU.ACUFB6.BPlus30AFuse4St";
BA_ "VssSig" SG_ 2566875678 BPlus30AFuse3St "Mch.ACU.ACUFB6.BPlus30AFuse3St";
BA_ "VssSig" SG_ 2566875678 BPlus30AFuse2St "Mch.ACU.ACUFB6.BPlus30AFuse2St";
BA_ "VssSig" SG_ 2566875678 BPlus30AFuse1St "Mch.ACU.ACUFB6.BPlus30AFuse1St";
BA_ "VssSig" SG_ 2566875678 BPlus20AFuse5St "Mch.ACU.ACUFB6.BPlus20AFuse5St";
BA_ "VssSig" SG_ 2566875678 BPlus20AFuse4St "Mch.ACU.ACUFB6.BPlus20AFuse4St";
BA_ "VssSig" SG_ 2566875678 BPlus20AFuse3St "Mch.ACU.ACUFB6.BPlus20AFuse3St";
BA_ "VssSig" SG_ 2566875678 BPlus20AFuse2St "Mch.ACU.ACUFB6.BPlus20AFuse2St";
BA_ "VssSig" SG_ 2566875678 BPlus20AFuse1St "Mch.ACU.ACUFB6.BPlus20AFuse1St";
BA_ "VssSig" SG_ 2566875678 BPlus5AFuse10St "Mch.ACU.ACUFB6.BPlus5AFuse10St";
BA_ "VssSig" SG_ 2566875678 BPlus5AFuse9St "Mch.ACU.ACUFB6.BPlus5AFuse9St";
BA_ "VssSig" SG_ 2566875678 BPlus5AFuse8St "Mch.ACU.ACUFB6.BPlus5AFuse8St";
BA_ "VssSig" SG_ 2566875678 BPlus5AFuse7St "Mch.ACU.ACUFB6.BPlus5AFuse7St";
BA_ "VssSig" SG_ 2566875678 BPlus5AFuse6St "Mch.ACU.ACUFB6.BPlus5AFuse6St";
BA_ "VssSig" SG_ 2566875678 BPlus5AFuse5St "Mch.ACU.ACUFB6.BPlus5AFuse5St";
BA_ "VssSig" SG_ 2566875678 BPlus5AFuse4St "Mch.ACU.ACUFB6.BPlus5AFuse4St";
BA_ "VssSig" SG_ 2566875678 BPlus5AFuse3St "Mch.ACU.ACUFB6.BPlus5AFuse3St";
BA_ "VssSig" SG_ 2566875678 BPlus5AFuse2St "Mch.ACU.ACUFB6.BPlus5AFuse2St";
BA_ "VssSig" SG_ 2566875678 BPlus5AFuse1St "Mch.ACU.ACUFB6.BPlus5AFuse1St";
BA_ "VssSig" SG_ 2566875678 IpsTotalCur "Mch.ACU.ACUFB6.IpsTotalCur";
BA_ "VssSig" SG_ 2566875678 MINIFuse2Cur "Mch.ACU.ACUFB6.MINIFuse2Cur";
BA_ "VssSig" SG_ 2566875678 MINIFuse1Cur "Mch.ACU.ACUFB6.MINIFuse1Cur";
BA_ "VssSig" SG_ 2566875678 MicroFuse5Cur "Mch.ACU.ACUFB6.MicroFuse5Cur";
BA_ "VssSig" SG_ 2566875678 MicroFuse4Cur "Mch.ACU.ACUFB6.MicroFuse4Cur";
BA_ "VssSig" SG_ 2566875678 MicroFuse3Cur "Mch.ACU.ACUFB6.MicroFuse3Cur";
BA_ "VssSig" SG_ 2566875678 MicroFuse2Cur "Mch.ACU.ACUFB6.MicroFuse2Cur";
BA_ "VssSig" SG_ 2566875678 MicroFuse1Cur "Mch.ACU.ACUFB6.MicroFuse1Cur";
BA_ "VssSig" SG_ 2566875678 KeyOnPwrCur "Mch.ACU.ACUFB6.KeyOnPwrCur";
BA_ "VssSig" SG_ 2566875678 BPlusPwrCur "Mch.ACU.ACUFB6.BPlusPwrCur";
BA_ "VssSig" SG_ 2566875815 MiniRly30AFuse2St "Mch.SMB.ACUFB6.MiniRly30AFuse2St";
BA_ "VssSig" SG_ 2566875815 MiniRly30AFuse1St "Mch.SMB.ACUFB6.MiniRly30AFuse1St";
BA_ "VssSig" SG_ 2566875815 MicroRly20AFuse5St "Mch.SMB.ACUFB6.MicroRly20AFuse5St";
BA_ "VssSig" SG_ 2566875815 MicroRly20AFuse4St "Mch.SMB.ACUFB6.MicroRly20AFuse4St";
BA_ "VssSig" SG_ 2566875815 MicroRly20AFuse3St "Mch.SMB.ACUFB6.MicroRly20AFuse3St";
BA_ "VssSig" SG_ 2566875815 MicroRly20AFuse2St "Mch.SMB.ACUFB6.MicroRly20AFuse2St";
BA_ "VssSig" SG_ 2566875815 MicroRly20AFuse1St "Mch.SMB.ACUFB6.MicroRly20AFuse1St";
BA_ "VssSig" SG_ 2566875815 KeyOn30AFuse5St "Mch.SMB.ACUFB6.KeyOn30AFuse5St";
BA_ "VssSig" SG_ 2566875815 KeyOn30AFuse4St "Mch.SMB.ACUFB6.KeyOn30AFuse4St";
BA_ "VssSig" SG_ 2566875815 KeyOn30AFuse3St "Mch.SMB.ACUFB6.KeyOn30AFuse3St";
BA_ "VssSig" SG_ 2566875815 KeyOn30AFuse2St "Mch.SMB.ACUFB6.KeyOn30AFuse2St";
BA_ "VssSig" SG_ 2566875815 KeyOn30AFuse1St "Mch.SMB.ACUFB6.KeyOn30AFuse1St";
BA_ "VssSig" SG_ 2566875815 KeyOn20AFuse10St "Mch.SMB.ACUFB6.KeyOn20AFuse10St";
BA_ "VssSig" SG_ 2566875815 KeyOn20AFuse9St "Mch.SMB.ACUFB6.KeyOn20AFuse9St";
BA_ "VssSig" SG_ 2566875815 KeyOn20AFuse8St "Mch.SMB.ACUFB6.KeyOn20AFuse8St";
BA_ "VssSig" SG_ 2566875815 KeyOn20AFuse7St "Mch.SMB.ACUFB6.KeyOn20AFuse7St";
BA_ "VssSig" SG_ 2566875815 KeyOn20AFuse6St "Mch.SMB.ACUFB6.KeyOn20AFuse6St";
BA_ "VssSig" SG_ 2566875815 KeyOn20AFuse5St "Mch.SMB.ACUFB6.KeyOn20AFuse5St";
BA_ "VssSig" SG_ 2566875815 KeyOn20AFuse4St "Mch.SMB.ACUFB6.KeyOn20AFuse4St";
BA_ "VssSig" SG_ 2566875815 KeyOn20AFuse3St "Mch.SMB.ACUFB6.KeyOn20AFuse3St";
BA_ "VssSig" SG_ 2566875815 KeyOn20AFuse2St "Mch.SMB.ACUFB6.KeyOn20AFuse2St";
BA_ "VssSig" SG_ 2566875815 KeyOn20AFuse1St "Mch.SMB.ACUFB6.KeyOn20AFuse1St";
BA_ "VssSig" SG_ 2566875815 KeyOn10AFuse5St "Mch.SMB.ACUFB6.KeyOn10AFuse5St";
BA_ "VssSig" SG_ 2566875815 KeyOn10AFuse4St "Mch.SMB.ACUFB6.KeyOn10AFuse4St";
BA_ "VssSig" SG_ 2566875815 KeyOn10AFuse3St "Mch.SMB.ACUFB6.KeyOn10AFuse3St";
BA_ "VssSig" SG_ 2566875815 KeyOn10AFuse2St "Mch.SMB.ACUFB6.KeyOn10AFuse2St";
BA_ "VssSig" SG_ 2566875815 KeyOn10AFuse1St "Mch.SMB.ACUFB6.KeyOn10AFuse1St";
BA_ "VssSig" SG_ 2566875815 KeyOn5AFuse15St "Mch.SMB.ACUFB6.KeyOn5AFuse15St";
BA_ "VssSig" SG_ 2566875815 KeyOn5AFuse14St "Mch.SMB.ACUFB6.KeyOn5AFuse14St";
BA_ "VssSig" SG_ 2566875815 KeyOn5AFuse13St "Mch.SMB.ACUFB6.KeyOn5AFuse13St";
BA_ "VssSig" SG_ 2566875815 KeyOn5AFuse12St "Mch.SMB.ACUFB6.KeyOn5AFuse12St";
BA_ "VssSig" SG_ 2566875815 KeyOn5AFuse11St "Mch.SMB.ACUFB6.KeyOn5AFuse11St";
BA_ "VssSig" SG_ 2566875815 KeyOn5AFuse10St "Mch.SMB.ACUFB6.KeyOn5AFuse10St";
BA_ "VssSig" SG_ 2566875815 KeyOn5AFuse9St "Mch.SMB.ACUFB6.KeyOn5AFuse9St";
BA_ "VssSig" SG_ 2566875815 KeyOn5AFuse8St "Mch.SMB.ACUFB6.KeyOn5AFuse8St";
BA_ "VssSig" SG_ 2566875815 KeyOn5AFuse7St "Mch.SMB.ACUFB6.KeyOn5AFuse7St";
BA_ "VssSig" SG_ 2566875815 KeyOn5AFuse6St "Mch.SMB.ACUFB6.KeyOn5AFuse6St";
BA_ "VssSig" SG_ 2566875815 KeyOn5AFuse5St "Mch.SMB.ACUFB6.KeyOn5AFuse5St";
BA_ "VssSig" SG_ 2566875815 KeyOn5AFuse4St "Mch.SMB.ACUFB6.KeyOn5AFuse4St";
BA_ "VssSig" SG_ 2566875815 KeyOn5AFuse3St "Mch.SMB.ACUFB6.KeyOn5AFuse3St";
BA_ "VssSig" SG_ 2566875815 KeyOn5AFuse2St "Mch.SMB.ACUFB6.KeyOn5AFuse2St";
BA_ "VssSig" SG_ 2566875815 KeyOn5AFuse1St "Mch.SMB.ACUFB6.KeyOn5AFuse1St";
BA_ "VssSig" SG_ 2566875815 BPlus30AFuse5St "Mch.SMB.ACUFB6.BPlus30AFuse5St";
BA_ "VssSig" SG_ 2566875815 BPlus30AFuse4St "Mch.SMB.ACUFB6.BPlus30AFuse4St";
BA_ "VssSig" SG_ 2566875815 BPlus30AFuse3St "Mch.SMB.ACUFB6.BPlus30AFuse3St";
BA_ "VssSig" SG_ 2566875815 BPlus30AFuse2St "Mch.SMB.ACUFB6.BPlus30AFuse2St";
BA_ "VssSig" SG_ 2566875815 BPlus30AFuse1St "Mch.SMB.ACUFB6.BPlus30AFuse1St";
BA_ "VssSig" SG_ 2566875815 BPlus20AFuse5St "Mch.SMB.ACUFB6.BPlus20AFuse5St";
BA_ "VssSig" SG_ 2566875815 BPlus20AFuse4St "Mch.SMB.ACUFB6.BPlus20AFuse4St";
BA_ "VssSig" SG_ 2566875815 BPlus20AFuse3St "Mch.SMB.ACUFB6.BPlus20AFuse3St";
BA_ "VssSig" SG_ 2566875815 BPlus20AFuse2St "Mch.SMB.ACUFB6.BPlus20AFuse2St";
BA_ "VssSig" SG_ 2566875815 BPlus20AFuse1St "Mch.SMB.ACUFB6.BPlus20AFuse1St";
BA_ "VssSig" SG_ 2566875815 BPlus5AFuse10St "Mch.SMB.ACUFB6.BPlus5AFuse10St";
BA_ "VssSig" SG_ 2566875815 BPlus5AFuse9St "Mch.SMB.ACUFB6.BPlus5AFuse9St";
BA_ "VssSig" SG_ 2566875815 BPlus5AFuse8St "Mch.SMB.ACUFB6.BPlus5AFuse8St";
BA_ "VssSig" SG_ 2566875815 BPlus5AFuse7St "Mch.SMB.ACUFB6.BPlus5AFuse7St";
BA_ "VssSig" SG_ 2566875815 BPlus5AFuse6St "Mch.SMB.ACUFB6.BPlus5AFuse6St";
BA_ "VssSig" SG_ 2566875815 BPlus5AFuse5St "Mch.SMB.ACUFB6.BPlus5AFuse5St";
BA_ "VssSig" SG_ 2566875815 BPlus5AFuse4St "Mch.SMB.ACUFB6.BPlus5AFuse4St";
BA_ "VssSig" SG_ 2566875815 BPlus5AFuse3St "Mch.SMB.ACUFB6.BPlus5AFuse3St";
BA_ "VssSig" SG_ 2566875815 BPlus5AFuse2St "Mch.SMB.ACUFB6.BPlus5AFuse2St";
BA_ "VssSig" SG_ 2566875815 BPlus5AFuse1St "Mch.SMB.ACUFB6.BPlus5AFuse1St";
BA_ "VssSig" SG_ 2566875815 IpsTotalCur "Mch.SMB.ACUFB6.IpsTotalCur";
BA_ "VssSig" SG_ 2566875815 MINIFuse2Cur "Mch.SMB.ACUFB6.MINIFuse2Cur";
BA_ "VssSig" SG_ 2566875815 MINIFuse1Cur "Mch.SMB.ACUFB6.MINIFuse1Cur";
BA_ "VssSig" SG_ 2566875815 MicroFuse5Cur "Mch.SMB.ACUFB6.MicroFuse5Cur";
BA_ "VssSig" SG_ 2566875815 MicroFuse4Cur "Mch.SMB.ACUFB6.MicroFuse4Cur";
BA_ "VssSig" SG_ 2566875815 MicroFuse3Cur "Mch.SMB.ACUFB6.MicroFuse3Cur";
BA_ "VssSig" SG_ 2566875815 MicroFuse2Cur "Mch.SMB.ACUFB6.MicroFuse2Cur";
BA_ "VssSig" SG_ 2566875815 MicroFuse1Cur "Mch.SMB.ACUFB6.MicroFuse1Cur";
BA_ "VssSig" SG_ 2566875815 KeyOnPwrCur "Mch.SMB.ACUFB6.KeyOnPwrCur";
BA_ "VssSig" SG_ 2566875815 BPlusPwrCur "Mch.SMB.ACUFB6.BPlusPwrCur";
BA_ "VssSig" SG_ 2566875929 AcpSsPrs "Mch.ACCU.ACRM1.AcpSsPrs";
BA_ "VssSig" SG_ 2566875929 CurAmbTmpCelsRealTm "Mch.ACCU.ACRM1.CurAmbTmpCelsRealTm";
BA_ "VssSig" SG_ 2566875929 TmpSt "Mch.ACCU.ACRM1.TmpSt";
BA_ "VssSig" SG_ 2566875929 CurBlowerSpd "Mch.ACCU.ACRM1.CurBlowerSpd";
BA_ "VssSig" SG_ 2566875929 CurAmbTmpCelsFilt "Mch.ACCU.ACRM1.CurAmbTmpCelsFilt";
BA_ "VssSig" SG_ 2566875929 CurTmpSet "Mch.ACCU.ACRM1.CurTmpSet";
BA_ "VssSig" SG_ 2566876576 ReqPgn "Mch.Audio.AFRTGP.ReqPgn";
BA_ "VssSig" SG_ 2566876576 MsgCounter "Mch.Audio.AFRTGP.MsgCounter";
BA_ "VssSig" SG_ 2566876832 AdoPreSetAma6FrqtoGp "Mch.Audio.APFGP.AdoPreSetAma6FrqtoGp";
BA_ "VssSig" SG_ 2566876832 AdoPreSetAma5FrqtoGp "Mch.Audio.APFGP.AdoPreSetAma5FrqtoGp";
BA_ "VssSig" SG_ 2566876832 AdoPreSetAma4FrqtoGp "Mch.Audio.APFGP.AdoPreSetAma4FrqtoGp";
BA_ "VssSig" SG_ 2566876832 AdoPreSetAma3FrqtoGp "Mch.Audio.APFGP.AdoPreSetAma3FrqtoGp";
BA_ "VssSig" SG_ 2566876832 AdoPreSetAma2FrqtoGp "Mch.Audio.APFGP.AdoPreSetAma2FrqtoGp";
BA_ "VssSig" SG_ 2566876832 AdoPreSetAma1FrqtoGp "Mch.Audio.APFGP.AdoPreSetAma1FrqtoGp";
BA_ "VssSig" SG_ 2566876832 AdoPreSetAm26FrqtoGp "Mch.Audio.APFGP.AdoPreSetAm26FrqtoGp";
BA_ "VssSig" SG_ 2566876832 AdoPreSetAm25FrqtoGp "Mch.Audio.APFGP.AdoPreSetAm25FrqtoGp";
BA_ "VssSig" SG_ 2566876832 AdoPreSetAm24FrqtoGp "Mch.Audio.APFGP.AdoPreSetAm24FrqtoGp";
BA_ "VssSig" SG_ 2566876832 AdoPreSetAm23FrqtoGp "Mch.Audio.APFGP.AdoPreSetAm23FrqtoGp";
BA_ "VssSig" SG_ 2566876832 AdoPreSetAm22FrqtoGp "Mch.Audio.APFGP.AdoPreSetAm22FrqtoGp";
BA_ "VssSig" SG_ 2566876832 AdoPreSetAm21FrqtoGp "Mch.Audio.APFGP.AdoPreSetAm21FrqtoGp";
BA_ "VssSig" SG_ 2566876832 AdoPreSetAm16FrqtoGp "Mch.Audio.APFGP.AdoPreSetAm16FrqtoGp";
BA_ "VssSig" SG_ 2566876832 AdoPreSetAm15FrqtoGp "Mch.Audio.APFGP.AdoPreSetAm15FrqtoGp";
BA_ "VssSig" SG_ 2566876832 AdoPreSetAm14FrqtoGp "Mch.Audio.APFGP.AdoPreSetAm14FrqtoGp";
BA_ "VssSig" SG_ 2566876832 AdoPreSetAm13FrqtoGp "Mch.Audio.APFGP.AdoPreSetAm13FrqtoGp";
BA_ "VssSig" SG_ 2566876832 AdoPreSetAm12FrqtoGp "Mch.Audio.APFGP.AdoPreSetAm12FrqtoGp";
BA_ "VssSig" SG_ 2566876832 AdoPreSetAm11FrqtoGp "Mch.Audio.APFGP.AdoPreSetAm11FrqtoGp";
BA_ "VssSig" SG_ 2566876832 AdoPreSetFma6FrqtoGp "Mch.Audio.APFGP.AdoPreSetFma6FrqtoGp";
BA_ "VssSig" SG_ 2566876832 AdoPreSetFma5FrqtoGp "Mch.Audio.APFGP.AdoPreSetFma5FrqtoGp";
BA_ "VssSig" SG_ 2566876832 AdoPreSetFma4FrqtoGp "Mch.Audio.APFGP.AdoPreSetFma4FrqtoGp";
BA_ "VssSig" SG_ 2566876832 AdoPreSetFma3FrqtoGp "Mch.Audio.APFGP.AdoPreSetFma3FrqtoGp";
BA_ "VssSig" SG_ 2566876832 AdoPreSetFma2FrqtoGp "Mch.Audio.APFGP.AdoPreSetFma2FrqtoGp";
BA_ "VssSig" SG_ 2566876832 AdoPreSetFma1FrqtoGp "Mch.Audio.APFGP.AdoPreSetFma1FrqtoGp";
BA_ "VssSig" SG_ 2566876832 AdoPreSetFm26FrqtoGp "Mch.Audio.APFGP.AdoPreSetFm26FrqtoGp";
BA_ "VssSig" SG_ 2566876832 AdoPreSetFm25FrqtoGp "Mch.Audio.APFGP.AdoPreSetFm25FrqtoGp";
BA_ "VssSig" SG_ 2566876832 AdoPreSetFm24FrqtoGp "Mch.Audio.APFGP.AdoPreSetFm24FrqtoGp";
BA_ "VssSig" SG_ 2566876832 AdoPreSetFm23FrqtoGp "Mch.Audio.APFGP.AdoPreSetFm23FrqtoGp";
BA_ "VssSig" SG_ 2566876832 AdoPreSetFm22FrqtoGp "Mch.Audio.APFGP.AdoPreSetFm22FrqtoGp";
BA_ "VssSig" SG_ 2566876832 AdoPreSetFm21FrqtoGp "Mch.Audio.APFGP.AdoPreSetFm21FrqtoGp";
BA_ "VssSig" SG_ 2566876832 AdoPreSetFm16FrqtoGp "Mch.Audio.APFGP.AdoPreSetFm16FrqtoGp";
BA_ "VssSig" SG_ 2566876832 AdoPreSetFm15FrqtoGp "Mch.Audio.APFGP.AdoPreSetFm15FrqtoGp";
BA_ "VssSig" SG_ 2566876832 AdoPreSetFm14FrqtoGp "Mch.Audio.APFGP.AdoPreSetFm14FrqtoGp";
BA_ "VssSig" SG_ 2566876832 AdoPreSetFm13FrqtoGp "Mch.Audio.APFGP.AdoPreSetFm13FrqtoGp";
BA_ "VssSig" SG_ 2566876832 AdoPreSetFm12FrqtoGp "Mch.Audio.APFGP.AdoPreSetFm12FrqtoGp";
BA_ "VssSig" SG_ 2566876832 AdoPreSetFm11FrqtoGp "Mch.Audio.APFGP.AdoPreSetFm11FrqtoGp";
BA_ "VssSig" SG_ 2566876961 LowOutReq8 "Mch.MCU.ACUCTR2.LowOutReq8";
BA_ "VssSig" SG_ 2566876961 LowOutReq7 "Mch.MCU.ACUCTR2.LowOutReq7";
BA_ "VssSig" SG_ 2566876961 LowOutReq6 "Mch.MCU.ACUCTR2.LowOutReq6";
BA_ "VssSig" SG_ 2566876961 LowOutReq5 "Mch.MCU.ACUCTR2.LowOutReq5";
BA_ "VssSig" SG_ 2566876961 LowOutReq4 "Mch.MCU.ACUCTR2.LowOutReq4";
BA_ "VssSig" SG_ 2566876961 LowOutReq3 "Mch.MCU.ACUCTR2.LowOutReq3";
BA_ "VssSig" SG_ 2566876961 LowOutReq2 "Mch.MCU.ACUCTR2.LowOutReq2";
BA_ "VssSig" SG_ 2566876961 LowOutReq1 "Mch.MCU.ACUCTR2.LowOutReq1";
BA_ "VssSig" SG_ 2566876961 OutReq15 "Mch.MCU.ACUCTR2.OutReq15";
BA_ "VssSig" SG_ 2566876961 OutReq14 "Mch.MCU.ACUCTR2.OutReq14";
BA_ "VssSig" SG_ 2566876961 OutReq13 "Mch.MCU.ACUCTR2.OutReq13";
BA_ "VssSig" SG_ 2566876961 OutReq12 "Mch.MCU.ACUCTR2.OutReq12";
BA_ "VssSig" SG_ 2566876961 OutReq11 "Mch.MCU.ACUCTR2.OutReq11";
BA_ "VssSig" SG_ 2566876961 OutReq10 "Mch.MCU.ACUCTR2.OutReq10";
BA_ "VssSig" SG_ 2566876961 OutReq9 "Mch.MCU.ACUCTR2.OutReq9";
BA_ "VssSig" SG_ 2566876961 OutReq8 "Mch.MCU.ACUCTR2.OutReq8";
BA_ "VssSig" SG_ 2566876961 OutReq7 "Mch.MCU.ACUCTR2.OutReq7";
BA_ "VssSig" SG_ 2566876961 OutReq6 "Mch.MCU.ACUCTR2.OutReq6";
BA_ "VssSig" SG_ 2566876961 OutReq5 "Mch.MCU.ACUCTR2.OutReq5";
BA_ "VssSig" SG_ 2566876961 OutReq4 "Mch.MCU.ACUCTR2.OutReq4";
BA_ "VssSig" SG_ 2566876961 OutReq3 "Mch.MCU.ACUCTR2.OutReq3";
BA_ "VssSig" SG_ 2566876961 OutReq2 "Mch.MCU.ACUCTR2.OutReq2";
BA_ "VssSig" SG_ 2566876961 OutReq1 "Mch.MCU.ACUCTR2.OutReq1";
VAL_ 2566866721 DifActlTrgGrdt 0 "OFF" 1 "ON" 2 "ERROR" 3 "NOT_AVAILABLE" ;
VAL_ 2566866721 OprPrsntSt 0 "OFF" 1 "ON" 2 "ERROR" 3 "NOT_AVAILABLE" ;
VAL_ 2566866721 HydCutOffRls 0 "OFF" 1 "ON" 2 "ERROR" 3 "NOT_AVAILABLE" ;
VAL_ 2566866721 ChgSt 0 "OFF" 1 "GREY" 2 "GREEN" 3 "YELLOW" ;
VAL_ 2566866721 WrkTrv 0 "OFF" 1 "GREY" 2 "GREEN" 3 "NOT_DEFINED" ;
VAL_ 2566866721 HydLck 0 "OFF" 1 "ON" 2 "ERROR" 3 "NOT_AVAILABLE" ;
VAL_ 2566866721 HillDscntCtrlSt 0 "OFF" 1 "ON" 2 "ERROR" 3 "NOT_AVAILABLE" ;
VAL_ 2566866721 OprPrsnc 0 "OFF" 1 "ON" 2 "ERROR" 3 "NOT_AVAILABLE" ;
VAL_ 2566866721 BckDust 0 "OFF" 1 "ON" 2 "ERROR" 3 "NOT_AVAILABLE" ;
VAL_ 2566866721 DacSt 0 "NOT_READY" 1 "STAND_BY" 2 "MANUAL" 3 "AUTO" 4 "INTERLOCK" 5 "SUSPEND_AUTO" ;
VAL_ 2566866721 EmcvFngrtpLvrErr 0 "OFF" 1 "ON" 2 "ERROR" 3 "NOT_AVAILABLE" ;
VAL_ 2566866721 PopCmdFnrNtrl 0 "OFF" 1 "COMBI_SWITCH_NOT_NEUTRAL" 2 "JOYSTICK_NOT_NEUTRAL" 3 "BOTH_NOT_NEUTRAL" ;
VAL_ 2566866721 IllminSt 0 "NONE" 1 "OFF" 2 "ON" 3 "NOT_AVAILABLE" ;
VAL_ 2566866721 ChmslSt 0 "OFF" 1 "BRAKE_ON" 2 "STANDBY_WORKING_CONTINUOUS" 3 "WORKING_STATUS_FLASHING" 4 "SWING_RIGHT" 5 "SWING_LEFT" 6 "OBJECT_SENSING_FAST_FLASHING" ;
VAL_ 2566866721 CdsFanRvsSt 0 "OFF" 1 "ON" 2 "ERROR" 3 "NOT_AVAILABLE" ;
VAL_ 2566866721 CacFanRvsSt 0 "OFF" 1 "ON" 2 "ERROR" 3 "NOT_AVAILABLE" ;
VAL_ 2566866721 CurMaxSpdMinor 0 "STEP_0" 1 "STEP_1" ;
VAL_ 2566866721 WhlTypeStrMd 0 "OFF" 1 "2WHEEL_MODE" 2 "4WHEEL_MODE_ROUND" 3 "4WHEEL_MODE_CRAB" ;
VAL_ 2566866721 WrnGndSlop 0 "OFF" 1 "ON" 2 "ERROR" 3 "NOT_AVAILABLE" ;
VAL_ 2566866721 WrnOilTmpLw 0 "OFF" 1 "ON" 2 "ERROR" 3 "NOT_AVAILABLE" ;
VAL_ 2566866721 WghConfirmWarnMsg 0 "OFF" 1 "SWING_SPEED_TOO_FAST" 2 "BOOM_TOO_HIGH" 3 "BOOM_TOO_LOW" 4 "ARM_TOO_NEAR" 5 "ARM_TOO_FAR" 6 "POOR_LIFT" ;
VAL_ 2566866721 AttOpr 0 "OFF" 1 "ON" 2 "ERROR" 3 "NOT_AVAILABLE" ;
VAL_ 2566866721 QckCoolSt 0 "BEFORE_PROCEEDING" 1 "PROCEEDING" 2 "NOT_POSSIBLE_TO_PROCEED" ;
VAL_ 2566866721 WrnLimpHome 0 "OFF" 1 "ON" 2 "ERROR" 3 "NOT_AVAILABLE" ;
VAL_ 2566866721 DozAstStopReq 0 "OFF" 1 "ON" 2 "ERROR" 3 "NOT_AVAILABLE" ;
VAL_ 2566866721 MchCond 0 "IDLE_CONDITION" 1 "WORKING_CONDITION" 2 "ERROR" 3 "STANDSTILL_CONDITION" ;
VAL_ 2566866721 WrnRollOvr 0 "OFF" 1 "WARNING_LEVEL1" 2 "WARNING_LEVEL2" ;
VAL_ 2566866721 WrnArmPosOnDrv 0 "OFF" 1 "ON" 2 "ERROR" 3 "NOT_AVAILABLE" ;
VAL_ 2566866721 WrnThwStrShft 0 "OFF" 1 "ON" 2 "ERROR" 3 "NOT_AVAILABLE" ;
VAL_ 2566866721 WrnRamLck 0 "OFF" 1 "ON" 2 "ERROR" 3 "NOT_AVAILABLE" ;
VAL_ 2566866721 WrnHstOilFilt 0 "OFF" 1 "ON" 2 "ERROR" 3 "NOT_AVAILABLE" ;
VAL_ 2566866721 WrnGrBoxOvTmp 0 "OFF" 1 "ON" 2 "ERROR" 3 "NOT_AVAILABLE" ;
VAL_ 2566866721 VhcStTractionLv 0 "A_3" 1 "B_2" 2 "C_1" 3 "NOT_DEFINED" ;
VAL_ 2566866721 WhlLis 0 "OFF" 1 "ON" 2 "ERROR" 3 "NOT_AVAILABLE" ;
VAL_ 2566866721 WhlDzTrlHitch 0 "OFF" 1 "ON" 2 "ERROR" 3 "NOT_AVAILABLE" ;
VAL_ 2566866721 WhlSwgAlign 0 "OFF" 1 "ON" 2 "ERROR" 3 "NOT_AVAILABLE" ;
VAL_ 2566866721 WhlRamLckAuto 0 "OFF" 1 "ON" 2 "ERROR" 3 "NOT_AVAILABLE" ;
VAL_ 2566867489 WarnPopLimitangexcess 0 "NONE" 1 "TILTING_IS_NOT_POSSIBLE" ;
VAL_ 2566867489 WarnPopMgMcSsErr 0 "NONE" 1 "SS_ERROR_BODY_BOOM_ARM_BCK_SWG" 2 "SENSOR_ERROR_TILT" 3 "SENSOR_ERROR_PILOT_CUTOFF" 4 "MACHINE_ERROR" 5 "XCU_COMMUNICATION_ERROR" 6 "TILT_ROTATOR_ERROR" ;
VAL_ 2566867489 McTemporaryRlsPop 0 "OFF" 1 "ON" 2 "ERROR" 3 "NOT_AVAILABLE" ;
VAL_ 2566867489 VhcStStickStr 0 "OFF" 1 "ON" 2 "ERROR" 3 "NOT_AVAILABLE" ;
VAL_ 2566867489 VhcStFineSwg 0 "OFF" 1 "ON" 2 "ERROR" 3 "NOT_AVAILABLE" ;
VAL_ 2566867489 ActTrvlSpdforCrwl 0 "LOW_SPEED" 1 "HIGH_SPEED" 2 "AUTO_SPEED" 3 "NOT_AVAILABLE" ;
VAL_ 2566867489 ActTrvlStforCrwl 0 "NOT_TRAVELING" 1 "TRAVELING" 2 "RESERVED" 3 "NOT_AVAILABLE" ;
VAL_ 2566867489 VhcStParallelLift 0 "OFF" 1 "ON" 2 "ERROR" 3 "NOT_AVAILABLE" ;
VAL_ 2566867489 VhcStFrSspnAuto 0 "OFF" 1 "ON" 2 "ERROR" 3 "NOT_AVAILABLE" ;
VAL_ 2566867489 RmCrakingSt 0 "NONE" 1 "SUCCESS" 2 "FAIL_BY_PARKING_SWITCH" 3 "FAIL_BY_NEUTRAL_SWITCH" 4 "FAIL_BY_PILOT_CUT_OFF_SWITCH" 5 "FAIL_BY_ANOTHER_REASON" ;
VAL_ 2566867489 VhcStElevatingCabin 0 "OFF" 1 "ON_NO_BLINKING" 2 "ON_NORMAL_BLINKING" 3 "ON_SLOW_BLINKING" ;
VAL_ 2566867489 WarnPopStickStr 0 "OFF" 1 "ON" 2 "ERROR" 3 "NOT_AVAILABLE" ;
VAL_ 2566867489 PopCmdThwLvrErr 0 "OFF" 1 "ON" 2 "ERROR" 3 "NOT_AVAILABLE" ;
VAL_ 2566867489 HpApMd 0 "OFF" 1 "HP" 2 "AP" 3 "NOT_AVAILABLE" ;
VAL_ 2566867489 GrLmt 0 "OFF" 1 "ON" 2 "ERROR" 3 "NOT_AVAILABLE" ;
VAL_ 2566867489 BodyAng 0 "OFF" 1 "ON" 2 "ERROR" 3 "NOT_AVAILABLE" ;
VAL_ 2566867489 WghIndSt 0 "OFF" 1 "STATE_1" 2 "STATE_2" 3 "STATE_3" ;
VAL_ 2566867489 RtrdSt 0 "OFF" 1 "STATE_1" 2 "STATE_2" 3 "STATE_3" 4 "STATE_4" 5 "STATE_5" 6 "STATE_6" 7 "STATE_7" ;
VAL_ 2566867489 PilotCutOffSt 0 "UNLOCK" 1 "MANUAL_LOCK" 2 "AUTO_LOCK" 3 "NOT_AVAILABLE" ;
VAL_ 2566867489 BodySt 0 "OFF" 1 "HOLD" 2 "FLOAT" 3 "NOT_DEFINED" ;
VAL_ 2566867489 VhcStGndSaw 0 "OFF" 1 "ON" 2 "ERROR" 3 "NOT_AVAILABLE" ;
VAL_ 2566867489 VhcStIntAxleLck 0 "OFF" 1 "ON" 2 "ERROR" 3 "NOT_AVAILABLE" ;
VAL_ 2566867489 TrlHhFlowMd 0 "STANDARD_BLUE" 1 "XPS_ORANGE" 2 "XHP_XE_RED" ;
VAL_ 2566867489 ExcAutoBrkAntiFire 0 "OFF" 1 "ON" 2 "CONDITION_GREEN" 3 "CONDITION_YELLOW" ;
VAL_ 2566867489 TrlIntLckOvrd 0 "OFF" 1 "ON" 2 "ERROR" 3 "NOT_AVAILABLE" ;
VAL_ 2566867489 TrlCtrlFlow 0 "OFF" 1 "ON" 2 "CONDITION_GREEN" 3 "CONDITION_YELLOW" ;
VAL_ 2566867489 TrlSelfLv 0 "OFF" 1 "ON" 2 "CONDITION_GREEN" 3 "CONDITION_YELLOW" ;
VAL_ 2566867489 TrlHhFlow 0 "OFF" 1 "ON" 2 "ERROR" 3 "NOT_AVAILABLE" ;
VAL_ 2566867745 EcoGgSt 0 "GREEN" 1 "YELLOW" 2 "RED" 3 "WHITE" ;
VAL_ 2566868257 AutoCalbMd 0 "MANUAL" 1 "AUTO" 2 "ERROR" 3 "NOT_AVAILABLE" ;
VAL_ 2566868257 CalbReq 0 "FALSE" 1 "TRUE" 2 "ERROR" 3 "NOT_AVAILABLE" ;
VAL_ 2566868257 VhcStTpsCalb 0 "NONE" 1 "IN_PROGRESS" 2 "COMPLETE" 3 "NOT_AVAILABLE" ;
VAL_ 2566868257 VhcStEgCtrlDialMax 0 "OFF" 1 "ON" 2 "ERROR" 3 "NOT_AVAILABLE" ;
VAL_ 2566868921 DialStep 0 "STEP_1" 1 "STEP_2" 2 "STEP_3" 3 "STEP_4" 4 "STEP_5" 5 "STEP_6" 6 "STEP_7" 7 "STEP_8" 8 "STEP_9" 9 "STEP_10" 10 "STEP_11" 11 "STEP_12" 12 "STEP_13" ;
VAL_ 2566869025 BlIntensity 0 "OFF" 255 "ERROR" ;
VAL_ 2566869025 BzStopBtn 0 "OFF" 1 "ON" 2 "ERROR" 3 "NOT_AVAILABLE" ;
VAL_ 2566869025 CallBtn 0 "OFF" 1 "ON" 2 "ERROR" 3 "NOT_AVAILABLE" ;
VAL_ 2566869025 FavoriteBtn 0 "OFF" 1 "ON" 2 "ERROR" 3 "NOT_AVAILABLE" ;
VAL_ 2566869025 DmbBtn 0 "OFF" 1 "ON" 2 "ERROR" 3 "NOT_AVAILABLE" ;
VAL_ 2566869025 WrkMdBtn 0 "OFF" 1 "ON" 2 "ERROR" 3 "NOT_AVAILABLE" ;
VAL_ 2566869025 AutoidleBzStopBtn 0 "OFF" 1 "ON" 2 "ERROR" 3 "NOT_AVAILABLE" ;
VAL_ 2566869025 PwrMdBtn 0 "OFF" 1 "ON" 2 "ERROR" 3 "NOT_AVAILABLE" ;
VAL_ 2566869025 CamEscBtn 0 "OFF" 1 "ON" 2 "ERROR" 3 "NOT_AVAILABLE" ;
VAL_ 2566869025 RotatyPushBtn 0 "OFF" 1 "ON" 2 "ERROR" 3 "NOT_AVAILABLE" ;
VAL_ 2566869158 BlIntensity 0 "OFF" 255 "ERROR" ;
VAL_ 2566869158 BzStopBtn 0 "OFF" 1 "ON" 2 "ERROR" 3 "NOT_AVAILABLE" ;
VAL_ 2566869158 CallBtn 0 "OFF" 1 "ON" 2 "ERROR" 3 "NOT_AVAILABLE" ;
VAL_ 2566869158 FavoriteBtn 0 "OFF" 1 "ON" 2 "ERROR" 3 "NOT_AVAILABLE" ;
VAL_ 2566869158 DmbBtn 0 "OFF" 1 "ON" 2 "ERROR" 3 "NOT_AVAILABLE" ;
VAL_ 2566869158 WrkMdBtn 0 "OFF" 1 "ON" 2 "ERROR" 3 "NOT_AVAILABLE" ;
VAL_ 2566869158 AutoidleBzStopBtn 0 "OFF" 1 "ON" 2 "ERROR" 3 "NOT_AVAILABLE" ;
VAL_ 2566869158 PwrMdBtn 0 "OFF" 1 "ON" 2 "ERROR" 3 "NOT_AVAILABLE" ;
VAL_ 2566869158 CamEscBtn 0 "OFF" 1 "ON" 2 "ERROR" 3 "NOT_AVAILABLE" ;
VAL_ 2566869158 RotatyPushBtn 0 "OFF" 1 "ON" 2 "ERROR" 3 "NOT_AVAILABLE" ;
VAL_ 2365543201 RvsFanLInd 0 "OFF" 1 "ON" 2 "BLINKING" 3 "NOT_AVAILABLE" ;
VAL_ 2365543201 RvsFanRInd 0 "OFF" 1 "ON" 2 "BLINKING" 3 "NOT_AVAILABLE" ;
VAL_ 2365543201 BoomLmpOprLInd 0 "OFF" 1 "ON" 2 "BLINKING" 3 "NOT_AVAILABLE" ;
VAL_ 2365543201 BoomLmpOprCtrInd 0 "OFF" 1 "ON" 2 "BLINKING" 3 "NOT_AVAILABLE" ;
VAL_ 2365543201 BoomLmpOprRInd 0 "OFF" 1 "ON" 2 "BLINKING" 3 "NOT_AVAILABLE" ;
VAL_ 2365543201 InfoLInd 0 "OFF" 1 "ON" 2 "BLINKING" 3 "NOT_AVAILABLE" ;
VAL_ 2365543201 InfoCtrInd 0 "OFF" 1 "ON" 2 "BLINKING" 3 "NOT_AVAILABLE" ;
VAL_ 2365543201 InfoRInd 0 "OFF" 1 "ON" 2 "BLINKING" 3 "NOT_AVAILABLE" ;
VAL_ 2365543201 EmgStrLInd 0 "OFF" 1 "ON" 2 "BLINKING" 3 "NOT_AVAILABLE" ;
VAL_ 2365543201 EmgStrCtrInd 0 "OFF" 1 "ON" 2 "BLINKING" 3 "NOT_AVAILABLE" ;
VAL_ 2365543201 EmgStrRInd 0 "OFF" 1 "ON" 2 "BLINKING" 3 "NOT_AVAILABLE" ;
VAL_ 2365543201 LoadIsolationLInd 0 "OFF" 1 "ON" 2 "BLINKING" 3 "NOT_AVAILABLE" ;
VAL_ 2365543201 LoadIsolationCtrInd 0 "OFF" 1 "ON" 2 "BLINKING" 3 "NOT_AVAILABLE" ;
VAL_ 2365543201 LoadIsolationRInd 0 "OFF" 1 "ON" 2 "BLINKING" 3 "NOT_AVAILABLE" ;
VAL_ 2365543201 MirrorHtLInd 0 "OFF" 1 "ON" 2 "BLINKING" 3 "NOT_AVAILABLE" ;
VAL_ 2365543201 MirrorHtCtrInd 0 "OFF" 1 "ON" 2 "BLINKING" 3 "NOT_AVAILABLE" ;
VAL_ 2365543201 MirrorHtRInd 0 "OFF" 1 "ON" 2 "BLINKING" 3 "NOT_AVAILABLE" ;
VAL_ 2365543201 RrWpWashLInd 0 "OFF" 1 "ON" 2 "BLINKING" 3 "NOT_AVAILABLE" ;
VAL_ 2365543201 RrWpWashCtrInd 0 "OFF" 1 "ON" 2 "BLINKING" 3 "NOT_AVAILABLE" ;
VAL_ 2365543201 RrWpWashRInd 0 "OFF" 1 "ON" 2 "BLINKING" 3 "NOT_AVAILABLE" ;
VAL_ 2365543201 BeaconLInd 0 "OFF" 1 "ON" 2 "BLINKING" 3 "NOT_AVAILABLE" ;
VAL_ 2365543201 BeaconCtrInd 0 "OFF" 1 "ON" 2 "BLINKING" 3 "NOT_AVAILABLE" ;
VAL_ 2365543201 BeaconRInd 0 "OFF" 1 "ON" 2 "BLINKING" 3 "NOT_AVAILABLE" ;
VAL_ 2365543201 RrWrkLmpLInd 0 "OFF" 1 "ON" 2 "BLINKING" 3 "NOT_AVAILABLE" ;
VAL_ 2365543201 RrWrkLmpCtrInd 0 "OFF" 1 "ON" 2 "BLINKING" 3 "NOT_AVAILABLE" ;
VAL_ 2365543201 RrWrkLmpRInd 0 "OFF" 1 "ON" 2 "BLINKING" 3 "NOT_AVAILABLE" ;
VAL_ 2365543201 FrWrkLmpLInd 0 "OFF" 1 "ON" 2 "BLINKING" 3 "NOT_AVAILABLE" ;
VAL_ 2365543201 FrWrkLmpCentorInd 0 "OFF" 1 "ON" 2 "BLINKING" 3 "NOT_AVAILABLE" ;
VAL_ 2365543201 FrWrkLmpRInd 0 "OFF" 1 "ON" 2 "BLINKING" 3 "NOT_AVAILABLE" ;
VAL_ 2365543201 HeadLmpLInd 0 "OFF" 1 "ON" 2 "BLINKING" 3 "NOT_AVAILABLE" ;
VAL_ 2365543201 HeadLmpCtrInd 0 "OFF" 1 "ON" 2 "BLINKING" 3 "NOT_AVAILABLE" ;
VAL_ 2365543201 HeadLmpRInd 0 "OFF" 1 "ON" 2 "BLINKING" 3 "NOT_AVAILABLE" ;
VAL_ 2365543504 BoomLis 0 "OFF" 1 "ON" 2 "ERROR" 3 "NOT_AVAILABLE" ;
VAL_ 2365543504 UpSig 0 "OFF" 1 "ON" 2 "ERROR" 3 "NOT_AVAILABLE" ;
VAL_ 2365543504 DnSig 0 "OFF" 1 "ON" 2 "ERROR" 3 "NOT_AVAILABLE" ;
VAL_ 2365543504 EnterSig 0 "OFF" 1 "ON" 2 "ERROR" 3 "NOT_AVAILABLE" ;
VAL_ 2365543504 MenuSig 0 "OFF" 1 "ON" 2 "ERROR" 3 "NOT_AVAILABLE" ;
VAL_ 2365543504 FrWpOprSig 0 "OFF" 1 "ON" 2 "ERROR" 3 "NOT_AVAILABLE" ;
VAL_ 2365543504 RrWpOprSig 0 "OFF" 1 "ON" 2 "ERROR" 3 "NOT_AVAILABLE" ;
VAL_ 2365543504 SideWpOprSig 0 "OFF" 1 "ON" 2 "ERROR" 3 "NOT_AVAILABLE" ;
VAL_ 2365543504 FrWpWashOprSig 0 "OFF" 1 "ON" 2 "ERROR" 3 "NOT_AVAILABLE" ;
VAL_ 2365543504 SideWpWashOprSig 0 "OFF" 1 "ON" 2 "ERROR" 3 "NOT_AVAILABLE" ;
VAL_ 2365543504 AirCompOprSig 0 "OFF" 1 "ON" 2 "ERROR" 3 "NOT_AVAILABLE" ;
VAL_ 2365543504 TrvlSpdOprSig 0 "OFF" 1 "ON" 2 "ERROR" 3 "NOT_AVAILABLE" ;
VAL_ 2365543504 AutoidleSig 0 "OFF" 1 "ON" 2 "ERROR" 3 "NOT_AVAILABLE" ;
VAL_ 2365543504 CrabRoundSelSig 0 "OFF" 1 "ON" 2 "ERROR" 3 "NOT_AVAILABLE" ;
VAL_ 2365543504 TwoWhlFourWhlSelSig 0 "OFF" 1 "ON" 2 "ERROR" 3 "NOT_AVAILABLE" ;
VAL_ 2365543504 ThrottleLckUpOprSig 0 "OFF" 1 "ON" 2 "ERROR" 3 "NOT_AVAILABLE" ;
VAL_ 2365543504 TractionCtrlMdOprSig 0 "OFF" 1 "ON" 2 "ERROR" 3 "NOT_AVAILABLE" ;
VAL_ 2365543504 VariableSpdDnOprSig 0 "OFF" 1 "ON" 2 "ERROR" 3 "NOT_AVAILABLE" ;
VAL_ 2365543504 VariableSpdUpOprSig 0 "OFF" 1 "ON" 2 "ERROR" 3 "NOT_AVAILABLE" ;
VAL_ 2365543504 MaxSpdUpOprSig 0 "OFF" 1 "ON" 2 "ERROR" 3 "NOT_AVAILABLE" ;
VAL_ 2365543504 MaxSpdDnOprSig 0 "OFF" 1 "ON" 2 "ERROR" 3 "NOT_AVAILABLE" ;
VAL_ 2365543504 TrqCvtLckUpOprSig 0 "OFF" 1 "ON" 2 "ERROR" 3 "NOT_AVAILABLE" ;
VAL_ 2365543504 ClutchCutOffOprSig 0 "OFF" 1 "ON" 2 "ERROR" 3 "NOT_AVAILABLE" ;
VAL_ 2365543504 TrmsMdSelOprSig 0 "OFF" 1 "ON" 2 "ERROR" 3 "NOT_AVAILABLE" ;
VAL_ 2365543504 OutriggerAllSig 0 "OFF" 1 "ON" 2 "ERROR" 3 "NOT_AVAILABLE" ;
VAL_ 2365543504 OutriggerRrRSig 0 "OFF" 1 "ON" 2 "ERROR" 3 "NOT_AVAILABLE" ;
VAL_ 2365543504 OutriggerRrLSig 0 "OFF" 1 "ON" 2 "ERROR" 3 "NOT_AVAILABLE" ;
VAL_ 2365543504 OutriggerFrRSig 0 "OFF" 1 "ON" 2 "ERROR" 3 "NOT_AVAILABLE" ;
VAL_ 2365543504 OutriggerFrLSig 0 "OFF" 1 "ON" 2 "ERROR" 3 "NOT_AVAILABLE" ;
VAL_ 2365543504 DifLockEngagedOprSig 0 "OFF" 1 "ON" 2 "ERROR" 3 "NOT_AVAILABLE" ;
VAL_ 2365543504 EmgStrOprSig 0 "OFF" 1 "ON" 2 "ERROR" 3 "NOT_AVAILABLE" ;
VAL_ 2365543504 BckDetentOprSig 0 "OFF" 1 "ON" 2 "ERROR" 3 "NOT_AVAILABLE" ;
VAL_ 2365543504 BoomDetentOprSig 0 "OFF" 1 "ON" 2 "ERROR" 3 "NOT_AVAILABLE" ;
VAL_ 2365543504 LoadIsolationOprSig 0 "OFF" 1 "ON" 2 "ERROR" 3 "NOT_AVAILABLE" ;
VAL_ 2365543504 MdSelOprSig 0 "OFF" 1 "ON" 2 "ERROR" 3 "NOT_AVAILABLE" ;
VAL_ 2365543504 MenuHelpOprSig 0 "OFF" 1 "ON" 2 "ERROR" 3 "NOT_AVAILABLE" ;
VAL_ 2365543504 JoyStrSig 0 "OFF" 1 "ON" 2 "ERROR" 3 "NOT_AVAILABLE" ;
VAL_ 2365543504 FineSwgSig 0 "OFF" 1 "ON" 2 "ERROR" 3 "NOT_AVAILABLE" ;
VAL_ 2365543504 TrailerHitchSig 0 "OFF" 1 "ON" 2 "ERROR" 3 "NOT_AVAILABLE" ;
VAL_ 2365543504 AutoDigBrkSig 0 "OFF" 1 "ON" 2 "ERROR" 3 "NOT_AVAILABLE" ;
VAL_ 2365543504 BoomSwgSig 0 "OFF" 1 "ON" 2 "ERROR" 3 "NOT_AVAILABLE" ;
VAL_ 2365543504 WorkMdSig 0 "OFF" 1 "ON" 2 "ERROR" 3 "NOT_AVAILABLE" ;
VAL_ 2365543504 PwrMdSig 0 "OFF" 1 "ON" 2 "ERROR" 3 "NOT_AVAILABLE" ;
VAL_ 2365543504 TrvlAlmSig 0 "OFF" 1 "ON" 2 "ERROR" 3 "NOT_AVAILABLE" ;
VAL_ 2365543504 MirrorHtOprSig 0 "OFF" 1 "ON" 2 "ERROR" 3 "NOT_AVAILABLE" ;
VAL_ 2365543504 RrWpWashOprSig 0 "OFF" 1 "ON" 2 "ERROR" 3 "NOT_AVAILABLE" ;
VAL_ 2365543504 OwdOprSig 0 "OFF" 1 "ON" 2 "ERROR" 3 "NOT_AVAILABLE" ;
VAL_ 2365543504 BoomLmpOprSig 0 "OFF" 1 "ON" 2 "ERROR" 3 "NOT_AVAILABLE" ;
VAL_ 2365543504 BeaconLmpOprSig 0 "OFF" 1 "ON" 2 "ERROR" 3 "NOT_AVAILABLE" ;
VAL_ 2365543504 RrWrkLmpOprSig 0 "OFF" 1 "ON" 2 "ERROR" 3 "NOT_AVAILABLE" ;
VAL_ 2365543504 FrWrkLmpOprSig 0 "OFF" 1 "ON" 2 "ERROR" 3 "NOT_AVAILABLE" ;
VAL_ 2365543504 HeadLmpOprSig 0 "OFF" 1 "ON" 2 "ERROR" 3 "NOT_AVAILABLE" ;
VAL_ 2365543713 SelfLvLInd 0 "OFF" 1 "ON" 2 "BLINKING" 3 "NOT_AVAILABLE" ;
VAL_ 2365543713 SelfLvCtrInd 0 "OFF" 1 "ON" 2 "BLINKING" 3 "NOT_AVAILABLE" ;
VAL_ 2365543713 SelfLvRInd 0 "OFF" 1 "ON" 2 "BLINKING" 3 "NOT_AVAILABLE" ;
VAL_ 2365543713 TrqCvtLckUpLInd 0 "OFF" 1 "ON" 2 "BLINKING" 3 "NOT_AVAILABLE" ;
VAL_ 2365543713 TrqCvtLckUpCtrInd 0 "OFF" 1 "ON" 2 "BLINKING" 3 "NOT_AVAILABLE" ;
VAL_ 2365543713 TrqCvtLckUpRInd 0 "OFF" 1 "ON" 2 "BLINKING" 3 "NOT_AVAILABLE" ;
VAL_ 2365543713 ClutchCutOffLInd 0 "OFF" 1 "ON" 2 "BLINKING" 3 "NOT_AVAILABLE" ;
VAL_ 2365543713 ClutchCutOffCtrInd 0 "OFF" 1 "ON" 2 "BLINKING" 3 "NOT_AVAILABLE" ;
VAL_ 2365543713 ClutchCutOffRInd 0 "OFF" 1 "ON" 2 "BLINKING" 3 "NOT_AVAILABLE" ;
VAL_ 2365543713 TrmsMdSelLInd 0 "OFF" 1 "ON" 2 "BLINKING" 3 "NOT_AVAILABLE" ;
VAL_ 2365543713 TrmsMdSelCtrInd 0 "OFF" 1 "ON" 2 "BLINKING" 3 "NOT_AVAILABLE" ;
VAL_ 2365543713 TrmsMdSelRInd 0 "OFF" 1 "ON" 2 "BLINKING" 3 "NOT_AVAILABLE" ;
VAL_ 2365543713 MaxSpdDnLInd 0 "OFF" 1 "ON" 2 "BLINKING" 3 "NOT_AVAILABLE" ;
VAL_ 2365543713 MaxSpdDnCtrInd 0 "OFF" 1 "ON" 2 "BLINKING" 3 "NOT_AVAILABLE" ;
VAL_ 2365543713 MaxSpdDnRInd 0 "OFF" 1 "ON" 2 "BLINKING" 3 "NOT_AVAILABLE" ;
VAL_ 2365543713 MaxSpdUpLInd 0 "OFF" 1 "ON" 2 "BLINKING" 3 "NOT_AVAILABLE" ;
VAL_ 2365543713 MaxSpdUpCtrInd 0 "OFF" 1 "ON" 2 "BLINKING" 3 "NOT_AVAILABLE" ;
VAL_ 2365543713 MaxSpdUpRInd 0 "OFF" 1 "ON" 2 "BLINKING" 3 "NOT_AVAILABLE" ;
VAL_ 2365543713 BckDetentLInd 0 "OFF" 1 "ON" 2 "BLINKING" 3 "NOT_AVAILABLE" ;
VAL_ 2365543713 BckDetentCtrInd 0 "OFF" 1 "ON" 2 "BLINKING" 3 "NOT_AVAILABLE" ;
VAL_ 2365543713 BckDetentRInd 0 "OFF" 1 "ON" 2 "BLINKING" 3 "NOT_AVAILABLE" ;
VAL_ 2365543713 BoomDetentLInd 0 "OFF" 1 "ON" 2 "BLINKING" 3 "NOT_AVAILABLE" ;
VAL_ 2365543713 BoomDetentCtrInd 0 "OFF" 1 "ON" 2 "BLINKING" 3 "NOT_AVAILABLE" ;
VAL_ 2365543713 BoomDetentRInd 0 "OFF" 1 "ON" 2 "BLINKING" 3 "NOT_AVAILABLE" ;
VAL_ 2365543713 DifLckEngagedLInd 0 "OFF" 1 "ON" 2 "BLINKING" 3 "NOT_AVAILABLE" ;
VAL_ 2365543713 DifLckEngagedCtrInd 0 "OFF" 1 "ON" 2 "BLINKING" 3 "NOT_AVAILABLE" ;
VAL_ 2365543713 DifLckEngagedRInd 0 "OFF" 1 "ON" 2 "BLINKING" 3 "NOT_AVAILABLE" ;
VAL_ 2365543713 MdSelLInd 0 "OFF" 1 "ON" 2 "BLINKING" 3 "NOT_AVAILABLE" ;
VAL_ 2365543713 MdSelCtrInd 0 "OFF" 1 "ON" 2 "BLINKING" 3 "NOT_AVAILABLE" ;
VAL_ 2365543713 MdSelRInd 0 "OFF" 1 "ON" 2 "BLINKING" 3 "NOT_AVAILABLE" ;
VAL_ 2365543969 HyhLckCtrInd 0 "OFF" 1 "ON" 2 "BLINKING" 3 "NOT_AVAILABLE" ;
VAL_ 2365543969 AutoidleLInd 0 "OFF" 1 "ON" 2 "BLINKING" 3 "NOT_AVAILABLE" ;
VAL_ 2365543969 AutoidleCtrInd 0 "OFF" 1 "ON" 2 "BLINKING" 3 "NOT_AVAILABLE" ;
VAL_ 2365543969 AutoidleRInd 0 "OFF" 1 "ON" 2 "BLINKING" 3 "NOT_AVAILABLE" ;
VAL_ 2365543969 JoyStrLInd 0 "OFF" 1 "ON" 2 "BLINKING" 3 "NOT_AVAILABLE" ;
VAL_ 2365543969 JoyStrCtrInd 0 "OFF" 1 "ON" 2 "BLINKING" 3 "NOT_AVAILABLE" ;
VAL_ 2365543969 JoyStrRInd 0 "OFF" 1 "ON" 2 "BLINKING" 3 "NOT_AVAILABLE" ;
VAL_ 2365543969 FineSwgLInd 0 "OFF" 1 "ON" 2 "BLINKING" 3 "NOT_AVAILABLE" ;
VAL_ 2365543969 FineSwgCtrInd 0 "OFF" 1 "ON" 2 "BLINKING" 3 "NOT_AVAILABLE" ;
VAL_ 2365543969 FineSwgRInd 0 "OFF" 1 "ON" 2 "BLINKING" 3 "NOT_AVAILABLE" ;
VAL_ 2365543969 TrailerHitchBrkLInd 0 "OFF" 1 "ON" 2 "BLINKING" 3 "NOT_AVAILABLE" ;
VAL_ 2365543969 TrailerHitchBrkCtrInd 0 "OFF" 1 "ON" 2 "BLINKING" 3 "NOT_AVAILABLE" ;
VAL_ 2365543969 TrailerHitchRInd 0 "OFF" 1 "ON" 2 "BLINKING" 3 "NOT_AVAILABLE" ;
VAL_ 2365543969 AutoDigBrkLInd 0 "OFF" 1 "ON" 2 "BLINKING" 3 "NOT_AVAILABLE" ;
VAL_ 2365543969 AutoDigBrkCtrInd 0 "OFF" 1 "ON" 2 "BLINKING" 3 "NOT_AVAILABLE" ;
VAL_ 2365543969 AutoDigBrkRInd 0 "OFF" 1 "ON" 2 "BLINKING" 3 "NOT_AVAILABLE" ;
VAL_ 2365543969 BoomSwgMdLInd 0 "OFF" 1 "ON" 2 "BLINKING" 3 "NOT_AVAILABLE" ;
VAL_ 2365543969 BoomSwgMdCtrInd 0 "OFF" 1 "ON" 2 "BLINKING" 3 "NOT_AVAILABLE" ;
VAL_ 2365543969 BoomSwgMdRInd 0 "OFF" 1 "ON" 2 "BLINKING" 3 "NOT_AVAILABLE" ;
VAL_ 2365543969 WrkMdLInd 0 "OFF" 1 "ON" 2 "BLINKING" 3 "NOT_AVAILABLE" ;
VAL_ 2365543969 WrkMdCtrInd 0 "OFF" 1 "ON" 2 "BLINKING" 3 "NOT_AVAILABLE" ;
VAL_ 2365543969 WrkMdRInd 0 "OFF" 1 "ON" 2 "BLINKING" 3 "NOT_AVAILABLE" ;
VAL_ 2365543969 PwrMdLInd 0 "OFF" 1 "ON" 2 "BLINKING" 3 "NOT_AVAILABLE" ;
VAL_ 2365543969 PwrMdCtrInd 0 "OFF" 1 "ON" 2 "BLINKING" 3 "NOT_AVAILABLE" ;
VAL_ 2365543969 PwrMdRInd 0 "OFF" 1 "ON" 2 "BLINKING" 3 "NOT_AVAILABLE" ;
VAL_ 2365543969 TrvlAlmLInd 0 "OFF" 1 "ON" 2 "BLINKING" 3 "NOT_AVAILABLE" ;
VAL_ 2365543969 TrvlAlmCtrInd 0 "OFF" 1 "ON" 2 "BLINKING" 3 "NOT_AVAILABLE" ;
VAL_ 2365543969 TrvlAlmRInd 0 "OFF" 1 "ON" 2 "BLINKING" 3 "NOT_AVAILABLE" ;
VAL_ 2365543969 OwdLInd 0 "OFF" 1 "ON" 2 "BLINKING" 3 "NOT_AVAILABLE" ;
VAL_ 2365543969 OwdCtrInd 0 "OFF" 1 "ON" 2 "BLINKING" 3 "NOT_AVAILABLE" ;
VAL_ 2365543969 OwdRInd 0 "OFF" 1 "ON" 2 "BLINKING" 3 "NOT_AVAILABLE" ;
VAL_ 2365544225 SwgLckLInd 0 "OFF" 1 "ON" 2 "BLINKING" 3 "NOT_AVAILABLE" ;
VAL_ 2365544225 SwgLckCtrInd 0 "OFF" 1 "ON" 2 "BLINKING" 3 "NOT_AVAILABLE" ;
VAL_ 2365544225 SwgLckRInd 0 "OFF" 1 "ON" 2 "BLINKING" 3 "NOT_AVAILABLE" ;
VAL_ 2365544225 BoomFltLInd 0 "OFF" 1 "ON" 2 "BLINKING" 3 "NOT_AVAILABLE" ;
VAL_ 2365544225 BoomFltCtrInd 0 "OFF" 1 "ON" 2 "BLINKING" 3 "NOT_AVAILABLE" ;
VAL_ 2365544225 BoomFltRInd 0 "OFF" 1 "ON" 2 "BLINKING" 3 "NOT_AVAILABLE" ;
VAL_ 2365544225 BoomLisLInd 0 "OFF" 1 "ON" 2 "BLINKING" 3 "NOT_AVAILABLE" ;
VAL_ 2365544225 BoomLisCtrInd 0 "OFF" 1 "ON" 2 "BLINKING" 3 "NOT_AVAILABLE" ;
VAL_ 2365544225 BoomLisRInd 0 "OFF" 1 "ON" 2 "BLINKING" 3 "NOT_AVAILABLE" ;
VAL_ 2365544225 CrabRoundSelLInd 0 "OFF" 1 "ON" 2 "BLINKING" 3 "NOT_AVAILABLE" ;
VAL_ 2365544225 CrabRoundSelCtrInd 0 "OFF" 1 "ON" 2 "BLINKING" 3 "NOT_AVAILABLE" ;
VAL_ 2365544225 CrabRoundSelRInd 0 "OFF" 1 "ON" 2 "BLINKING" 3 "NOT_AVAILABLE" ;
VAL_ 2365544225 TwoWhlFourWhlSelLInd 0 "OFF" 1 "ON" 2 "BLINKING" 3 "NOT_AVAILABLE" ;
VAL_ 2365544225 TwoWhlFourWhlSelCtrInd 0 "OFF" 1 "ON" 2 "BLINKING" 3 "NOT_AVAILABLE" ;
VAL_ 2365544225 TwoWhlFourWhlSelRInd 0 "OFF" 1 "ON" 2 "BLINKING" 3 "NOT_AVAILABLE" ;
VAL_ 2365544225 OtrgAllLInd 0 "OFF" 1 "ON" 2 "BLINKING" 3 "NOT_AVAILABLE" ;
VAL_ 2365544225 OtrgAllCtrInd 0 "OFF" 1 "ON" 2 "BLINKING" 3 "NOT_AVAILABLE" ;
VAL_ 2365544225 OtrgAllRInd 0 "OFF" 1 "ON" 2 "BLINKING" 3 "NOT_AVAILABLE" ;
VAL_ 2365544225 OtrgRrRLInd 0 "OFF" 1 "ON" 2 "BLINKING" 3 "NOT_AVAILABLE" ;
VAL_ 2365544225 OtrgRrRCtrInd 0 "OFF" 1 "ON" 2 "BLINKING" 3 "NOT_AVAILABLE" ;
VAL_ 2365544225 OtrgRrRRInd 0 "OFF" 1 "ON" 2 "BLINKING" 3 "NOT_AVAILABLE" ;
VAL_ 2365544225 OtrgRrLLInd 0 "OFF" 1 "ON" 2 "BLINKING" 3 "NOT_AVAILABLE" ;
VAL_ 2365544225 OtrgRrLCtrInd 0 "OFF" 1 "ON" 2 "BLINKING" 3 "NOT_AVAILABLE" ;
VAL_ 2365544225 OtrgRrLRInd 0 "OFF" 1 "ON" 2 "BLINKING" 3 "NOT_AVAILABLE" ;
VAL_ 2365544225 OtrgFrRLInd 0 "OFF" 1 "ON" 2 "BLINKING" 3 "NOT_AVAILABLE" ;
VAL_ 2365544225 OtrgFrRCtrInd 0 "OFF" 1 "ON" 2 "BLINKING" 3 "NOT_AVAILABLE" ;
VAL_ 2365544225 OtrgFrRRInd 0 "OFF" 1 "ON" 2 "BLINKING" 3 "NOT_AVAILABLE" ;
VAL_ 2365544225 OtrgFrLLInd 0 "OFF" 1 "ON" 2 "BLINKING" 3 "NOT_AVAILABLE" ;
VAL_ 2365544225 OtrgFrLCtrInd 0 "OFF" 1 "ON" 2 "BLINKING" 3 "NOT_AVAILABLE" ;
VAL_ 2365544225 OtrgFrLRInd 0 "OFF" 1 "ON" 2 "BLINKING" 3 "NOT_AVAILABLE" ;
VAL_ 2365544481 Aux8LInd 0 "OFF" 1 "ON" 2 "BLINKING" 3 "NOT_AVAILABLE" ;
VAL_ 2365544481 Aux8CtrInd 0 "OFF" 1 "ON" 2 "BLINKING" 3 "NOT_AVAILABLE" ;
VAL_ 2365544481 Aux8RInd 0 "OFF" 1 "ON" 2 "BLINKING" 3 "NOT_AVAILABLE" ;
VAL_ 2365544481 Aux7LInd 0 "OFF" 1 "ON" 2 "BLINKING" 3 "NOT_AVAILABLE" ;
VAL_ 2365544481 Aux7CtrInd 0 "OFF" 1 "ON" 2 "BLINKING" 3 "NOT_AVAILABLE" ;
VAL_ 2365544481 Aux7RInd 0 "OFF" 1 "ON" 2 "BLINKING" 3 "NOT_AVAILABLE" ;
VAL_ 2365544481 ContinuousFlowLInd 0 "OFF" 1 "ON" 2 "BLINKING" 3 "NOT_AVAILABLE" ;
VAL_ 2365544481 ContinuousFlowCtrInd 0 "OFF" 1 "ON" 2 "BLINKING" 3 "NOT_AVAILABLE" ;
VAL_ 2365544481 ContinuousFlowRInd 0 "OFF" 1 "ON" 2 "BLINKING" 3 "NOT_AVAILABLE" ;
VAL_ 2365544481 InterlockOverrideLInd 0 "OFF" 1 "ON" 2 "BLINKING" 3 "NOT_AVAILABLE" ;
VAL_ 2365544481 InterlockOverrideCtrInd 0 "OFF" 1 "ON" 2 "BLINKING" 3 "NOT_AVAILABLE" ;
VAL_ 2365544481 InterlockOverrideRInd 0 "OFF" 1 "ON" 2 "BLINKING" 3 "NOT_AVAILABLE" ;
VAL_ 2365544481 ShakeCtrlLInd 0 "OFF" 1 "ON" 2 "BLINKING" 3 "NOT_AVAILABLE" ;
VAL_ 2365544481 ShakeCtrlCtrInd 0 "OFF" 1 "ON" 2 "BLINKING" 3 "NOT_AVAILABLE" ;
VAL_ 2365544481 ShakeCtrlRInd 0 "OFF" 1 "ON" 2 "BLINKING" 3 "NOT_AVAILABLE" ;
VAL_ 2365544481 ThrottleLckUpLInd 0 "OFF" 1 "ON" 2 "BLINKING" 3 "NOT_AVAILABLE" ;
VAL_ 2365544481 ThrottleLckUpCtrInd 0 "OFF" 1 "ON" 2 "BLINKING" 3 "NOT_AVAILABLE" ;
VAL_ 2365544481 ThrottleLckUpRInd 0 "OFF" 1 "ON" 2 "BLINKING" 3 "NOT_AVAILABLE" ;
VAL_ 2365544481 TractionCtrlMdLInd 0 "OFF" 1 "ON" 2 "BLINKING" 3 "NOT_AVAILABLE" ;
VAL_ 2365544481 TractionCtrlMdCtrInd 0 "OFF" 1 "ON" 2 "BLINKING" 3 "NOT_AVAILABLE" ;
VAL_ 2365544481 TractionCtrlMdRInd 0 "OFF" 1 "ON" 2 "BLINKING" 3 "NOT_AVAILABLE" ;
VAL_ 2365544481 VariableSpdDnLInd 0 "OFF" 1 "ON" 2 "BLINKING" 3 "NOT_AVAILABLE" ;
VAL_ 2365544481 VariableSpdDnCtrInd 0 "OFF" 1 "ON" 2 "BLINKING" 3 "NOT_AVAILABLE" ;
VAL_ 2365544481 VariableSpdDnRInd 0 "OFF" 1 "ON" 2 "BLINKING" 3 "NOT_AVAILABLE" ;
VAL_ 2365544481 VariableSpdUpLInd 0 "OFF" 1 "ON" 2 "BLINKING" 3 "NOT_AVAILABLE" ;
VAL_ 2365544481 VariableSpdUpCtrInd 0 "OFF" 1 "ON" 2 "BLINKING" 3 "NOT_AVAILABLE" ;
VAL_ 2365544481 VariableSpdUpRInd 0 "OFF" 1 "ON" 2 "BLINKING" 3 "NOT_AVAILABLE" ;
VAL_ 2365544737 TrkExpansionLInd 0 "OFF" 1 "ON" 2 "BLINKING" 3 "NOT_AVAILABLE" ;
VAL_ 2365544737 TrkExpansionCtrInd 0 "OFF" 1 "ON" 2 "BLINKING" 3 "NOT_AVAILABLE" ;
VAL_ 2365544737 TrkExpansionRInd 0 "OFF" 1 "ON" 2 "BLINKING" 3 "NOT_AVAILABLE" ;
VAL_ 2365544737 FrWpLInd 0 "OFF" 1 "ON" 2 "BLINKING" 3 "NOT_AVAILABLE" ;
VAL_ 2365544737 FrWpCtrInd 0 "OFF" 1 "ON" 2 "BLINKING" 3 "NOT_AVAILABLE" ;
VAL_ 2365544737 FrWpRInd 0 "OFF" 1 "ON" 2 "BLINKING" 3 "NOT_AVAILABLE" ;
VAL_ 2365544737 RrWpLInd 0 "OFF" 1 "ON" 2 "BLINKING" 3 "NOT_AVAILABLE" ;
VAL_ 2365544737 RrWpCtrInd 0 "OFF" 1 "ON" 2 "BLINKING" 3 "NOT_AVAILABLE" ;
VAL_ 2365544737 RrWpRInd 0 "OFF" 1 "ON" 2 "BLINKING" 3 "NOT_AVAILABLE" ;
VAL_ 2365544737 SideWpLInd 0 "OFF" 1 "ON" 2 "BLINKING" 3 "NOT_AVAILABLE" ;
VAL_ 2365544737 SideWpCtrInd 0 "OFF" 1 "ON" 2 "BLINKING" 3 "NOT_AVAILABLE" ;
VAL_ 2365544737 SideWpRInd 0 "OFF" 1 "ON" 2 "BLINKING" 3 "NOT_AVAILABLE" ;
VAL_ 2365544737 FrWpWashLInd 0 "OFF" 1 "ON" 2 "BLINKING" 3 "NOT_AVAILABLE" ;
VAL_ 2365544737 FrWpWashCtrInd 0 "OFF" 1 "ON" 2 "BLINKING" 3 "NOT_AVAILABLE" ;
VAL_ 2365544737 FrWpWashRInd 0 "OFF" 1 "ON" 2 "BLINKING" 3 "NOT_AVAILABLE" ;
VAL_ 2365544737 SideWpWashLInd 0 "OFF" 1 "ON" 2 "BLINKING" 3 "NOT_AVAILABLE" ;
VAL_ 2365544737 SideWpWashCtrInd 0 "OFF" 1 "ON" 2 "BLINKING" 3 "NOT_AVAILABLE" ;
VAL_ 2365544737 SideWpWashRInd 0 "OFF" 1 "ON" 2 "BLINKING" 3 "NOT_AVAILABLE" ;
VAL_ 2365544737 RrMirrorHtLInd 0 "OFF" 1 "ON" 2 "BLINKING" 3 "NOT_AVAILABLE" ;
VAL_ 2365544737 RrMirrorHtCtrInd 0 "OFF" 1 "ON" 2 "BLINKING" 3 "NOT_AVAILABLE" ;
VAL_ 2365544737 RrMirrorHtRInd 0 "OFF" 1 "ON" 2 "BLINKING" 3 "NOT_AVAILABLE" ;
VAL_ 2365544737 AirCompLInd 0 "OFF" 1 "ON" 2 "BLINKING" 3 "NOT_AVAILABLE" ;
VAL_ 2365544737 AirCompCtrInd 0 "OFF" 1 "ON" 2 "BLINKING" 3 "NOT_AVAILABLE" ;
VAL_ 2365544737 AirCompRInd 0 "OFF" 1 "ON" 2 "BLINKING" 3 "NOT_AVAILABLE" ;
VAL_ 2365544737 TrvlSpdLInd 0 "OFF" 1 "ON" 2 "BLINKING" 3 "NOT_AVAILABLE" ;
VAL_ 2365544737 TrvlSpdCtrInd 0 "OFF" 1 "ON" 2 "BLINKING" 3 "NOT_AVAILABLE" ;
VAL_ 2365544737 TrvlSpdRInd 0 "OFF" 1 "ON" 2 "BLINKING" 3 "NOT_AVAILABLE" ;
VAL_ 2365544737 BzStopLInd 0 "OFF" 1 "ON" 2 "BLINKING" 3 "NOT_AVAILABLE" ;
VAL_ 2365544737 BzStopCtrInd 0 "OFF" 1 "ON" 2 "BLINKING" 3 "NOT_AVAILABLE" ;
VAL_ 2365544737 BzStopRInd 0 "OFF" 1 "ON" 2 "BLINKING" 3 "NOT_AVAILABLE" ;
VAL_ 2566871629 HornSwIn 0 "OFF" 1 "ON" 2 "ERROR" 3 "NOT_AVAILABLE" ;
VAL_ 2365545552 BoomFltOprSig 0 "OFF" 1 "ON" 2 "ERROR" 3 "NOT_AVAILABLE" ;
VAL_ 2365545552 SwgLckOprSig 0 "OFF" 1 "ON" 2 "ERROR" 3 "NOT_AVAILABLE" ;
VAL_ 2365545552 HpApMdSelOprSig 0 "OFF" 1 "ON" 2 "ERROR" 3 "NOT_AVAILABLE" ;
VAL_ 2365545761 OutTrgDzShortcutLInd 0 "OFF" 1 "ON" 2 "BLINKING" 3 "NOT_AVAILABLE" ;
VAL_ 2365545761 OutTrgDzShortcutCtrInd 0 "OFF" 1 "ON" 2 "BLINKING" 3 "NOT_AVAILABLE" ;
VAL_ 2365545761 OutTrgDzShortcutRInd 0 "OFF" 1 "ON" 2 "BLINKING" 3 "NOT_AVAILABLE" ;
VAL_ 2365545761 BoomFltLInd 0 "OFF" 1 "ON" 2 "BLINKING" 3 "NOT_AVAILABLE" ;
VAL_ 2365545761 BoomFltCtrInd 0 "OFF" 1 "ON" 2 "BLINKING" 3 "NOT_AVAILABLE" ;
VAL_ 2365545761 BoomFltRInd 0 "OFF" 1 "ON" 2 "BLINKING" 3 "NOT_AVAILABLE" ;
VAL_ 2365545761 SwgLckLInd 0 "OFF" 1 "ON" 2 "BLINKING" 3 "NOT_AVAILABLE" ;
VAL_ 2365545761 SwgLckCtrInd 0 "OFF" 1 "ON" 2 "BLINKING" 3 "NOT_AVAILABLE" ;
VAL_ 2365545761 SwgLckRInd 0 "OFF" 1 "ON" 2 "BLINKING" 3 "NOT_AVAILABLE" ;
VAL_ 2365545761 HpApMdLInd 0 "OFF" 1 "ON" 2 "BLINKING" 3 "NOT_AVAILABLE" ;
VAL_ 2365545761 HpApMdCtrInd 0 "OFF" 1 "ON" 2 "BLINKING" 3 "NOT_AVAILABLE" ;
VAL_ 2365545761 HpApMdRInd 0 "OFF" 1 "ON" 2 "BLINKING" 3 "NOT_AVAILABLE" ;
VAL_ 2566873377 LowOutReq8 0 "OFF" 1 "ON" 2 "ERROR" 3 "NOT_AVAILABLE" ;
VAL_ 2566873377 LowOutReq7 0 "OFF" 1 "ON" 2 "ERROR" 3 "NOT_AVAILABLE" ;
VAL_ 2566873377 LowOutReq6 0 "OFF" 1 "ON" 2 "ERROR" 3 "NOT_AVAILABLE" ;
VAL_ 2566873377 LowOutReq5 0 "OFF" 1 "ON" 2 "ERROR" 3 "NOT_AVAILABLE" ;
VAL_ 2566873377 LowOutReq4 0 "OFF" 1 "ON" 2 "ERROR" 3 "NOT_AVAILABLE" ;
VAL_ 2566873377 LowOutReq3 0 "OFF" 1 "ON" 2 "ERROR" 3 "NOT_AVAILABLE" ;
VAL_ 2566873377 LowOutReq2 0 "OFF" 1 "ON" 2 "ERROR" 3 "NOT_AVAILABLE" ;
VAL_ 2566873377 LowOutReq1 0 "OFF" 1 "ON" 2 "ERROR" 3 "NOT_AVAILABLE" ;
VAL_ 2566873377 OutReq15 0 "OFF" 1 "ON" 2 "ERROR" 3 "NOT_AVAILABLE" ;
VAL_ 2566873377 OutReq14 0 "OFF" 1 "ON" 2 "ERROR" 3 "NOT_AVAILABLE" ;
VAL_ 2566873377 OutReq13 0 "OFF" 1 "ON" 2 "ERROR" 3 "NOT_AVAILABLE" ;
VAL_ 2566873377 OutReq12 0 "OFF" 1 "ON" 2 "ERROR" 3 "NOT_AVAILABLE" ;
VAL_ 2566873377 OutReq11 0 "OFF" 1 "ON" 2 "ERROR" 3 "NOT_AVAILABLE" ;
VAL_ 2566873377 OutReq10 0 "OFF" 1 "ON" 2 "ERROR" 3 "NOT_AVAILABLE" ;
VAL_ 2566873377 OutReq9 0 "OFF" 1 "ON" 2 "ERROR" 3 "NOT_AVAILABLE" ;
VAL_ 2566873377 OutReq8 0 "OFF" 1 "ON" 2 "ERROR" 3 "NOT_AVAILABLE" ;
VAL_ 2566873377 OutReq7 0 "OFF" 1 "ON" 2 "ERROR" 3 "NOT_AVAILABLE" ;
VAL_ 2566873377 OutReq6 0 "OFF" 1 "ON" 2 "ERROR" 3 "NOT_AVAILABLE" ;
VAL_ 2566873377 OutReq5 0 "OFF" 1 "ON" 2 "ERROR" 3 "NOT_AVAILABLE" ;
VAL_ 2566873377 OutReq4 0 "OFF" 1 "ON" 2 "ERROR" 3 "NOT_AVAILABLE" ;
VAL_ 2566873377 OutReq3 0 "OFF" 1 "ON" 2 "ERROR" 3 "NOT_AVAILABLE" ;
VAL_ 2566873377 OutReq2 0 "OFF" 1 "ON" 2 "ERROR" 3 "NOT_AVAILABLE" ;
VAL_ 2566873377 OutReq1 0 "OFF" 1 "ON" 2 "ERROR" 3 "NOT_AVAILABLE" ;
VAL_ 2566873630 OutFdbkCur8 254 "ERROR" 255 "NOT_AVAILABLE" ;
VAL_ 2566873630 OutFdbkCur7 254 "ERROR" 255 "NOT_AVAILABLE" ;
VAL_ 2566873630 OutFdbkCur6 254 "ERROR" 255 "NOT_AVAILABLE" ;
VAL_ 2566873630 OutFdbkCur5 254 "ERROR" 255 "NOT_AVAILABLE" ;
VAL_ 2566873630 OutFdbkCur4 254 "ERROR" 255 "NOT_AVAILABLE" ;
VAL_ 2566873630 OutFdbkCur3 254 "ERROR" 255 "NOT_AVAILABLE" ;
VAL_ 2566873630 OutFdbkCur2 254 "ERROR" 255 "NOT_AVAILABLE" ;
VAL_ 2566873630 OutFdbkCur1 254 "ERROR" 255 "NOT_AVAILABLE" ;
VAL_ 2566873767 OutFdbkCur8 254 "ERROR" 255 "NOT_AVAILABLE" ;
VAL_ 2566873767 OutFdbkCur7 254 "ERROR" 255 "NOT_AVAILABLE" ;
VAL_ 2566873767 OutFdbkCur6 254 "ERROR" 255 "NOT_AVAILABLE" ;
VAL_ 2566873767 OutFdbkCur5 254 "ERROR" 255 "NOT_AVAILABLE" ;
VAL_ 2566873767 OutFdbkCur4 254 "ERROR" 255 "NOT_AVAILABLE" ;
VAL_ 2566873767 OutFdbkCur3 254 "ERROR" 255 "NOT_AVAILABLE" ;
VAL_ 2566873767 OutFdbkCur2 254 "ERROR" 255 "NOT_AVAILABLE" ;
VAL_ 2566873767 OutFdbkCur1 254 "ERROR" 255 "NOT_AVAILABLE" ;
VAL_ 2566873886 ErrorFlag 0 "NONE" 255 "ERROR" ;
VAL_ 2566873886 VltIn2 254 "ERROR" 255 "NOT_AVAILABLE" ;
VAL_ 2566873886 VltIn1 254 "ERROR" 255 "NOT_AVAILABLE" ;
VAL_ 2566873886 OutFdbkCur13 254 "ERROR" 255 "NOT_AVAILABLE" ;
VAL_ 2566873886 OutFdbkCur12 254 "ERROR" 255 "NOT_AVAILABLE" ;
VAL_ 2566873886 OutFdbkCur11 254 "ERROR" 255 "NOT_AVAILABLE" ;
VAL_ 2566873886 OutFdbkCur10 254 "ERROR" 255 "NOT_AVAILABLE" ;
VAL_ 2566873886 OutFdbkCur9 254 "ERROR" 255 "NOT_AVAILABLE" ;
VAL_ 2566874654 OutFdbkActvLowCur8 0 "NORMAL" 1 "OPEN" 2 "SHORT" ;
VAL_ 2566874654 OutFdbkActvLowCur7 0 "NORMAL" 1 "OPEN" 2 "SHORT" ;
VAL_ 2566874654 OutFdbkActvLowCur6 0 "NORMAL" 1 "OPEN" 2 "SHORT" ;
VAL_ 2566874654 OutFdbkActvLowCur5 0 "NORMAL" 1 "OPEN" 2 "SHORT" ;
VAL_ 2566874654 OutFdbkActvLowCur4 0 "NORMAL" 1 "OPEN" 2 "SHORT" ;
VAL_ 2566874654 OutFdbkActvLowCur3 0 "NORMAL" 1 "OPEN" 2 "SHORT" ;
VAL_ 2566874654 OutFdbkActvLowCur2 0 "NORMAL" 1 "OPEN" 2 "SHORT" ;
VAL_ 2566874654 OutFdbkActvLowCur1 0 "NORMAL" 1 "OPEN" 2 "SHORT" ;
VAL_ 2566874654 OutFdbkActvHighCur15 0 "NORMAL" 1 "OPEN" 2 "SHORT" ;
VAL_ 2566874654 OutFdbkActvHighCur14 0 "NORMAL" 1 "OPEN" 2 "SHORT" ;
VAL_ 2566874654 OutFdbkActvHighCur13 0 "NORMAL" 1 "OPEN" 2 "SHORT" ;
VAL_ 2566874654 OutFdbkActvHighCur12 0 "NORMAL" 1 "OPEN" 2 "SHORT" ;
VAL_ 2566874654 OutFdbkActvHighCur11 0 "NORMAL" 1 "OPEN" 2 "SHORT" ;
VAL_ 2566874654 OutFdbkActvHighCur10 0 "NORMAL" 1 "OPEN" 2 "SHORT" ;
VAL_ 2566874654 OutFdbkActvHighCur9 0 "NORMAL" 1 "OPEN" 2 "SHORT" ;
VAL_ 2566874654 OutFdbkActvHighCur8 0 "NORMAL" 1 "OPEN" 2 "SHORT" ;
VAL_ 2566874654 OutFdbkActvHighCur7 0 "NORMAL" 1 "OPEN" 2 "SHORT" ;
VAL_ 2566874654 OutFdbkActvHighCur6 0 "NORMAL" 1 "OPEN" 2 "SHORT" ;
VAL_ 2566874654 OutFdbkActvHighCur5 0 "NORMAL" 1 "OPEN" 2 "SHORT" ;
VAL_ 2566874654 OutFdbkActvHighCur4 0 "NORMAL" 1 "OPEN" 2 "SHORT" ;
VAL_ 2566874654 OutFdbkActvHighCur3 254 "ERROR" 255 "NOT_AVAILABLE" ;
VAL_ 2566874654 OutFdbkActvHighCur2 254 "ERROR" 255 "NOT_AVAILABLE" ;
VAL_ 2566874654 OutFdbkActvHighCur1 254 "ERROR" 255 "NOT_AVAILABLE" ;
VAL_ 2566874910 InVlt12 0 "NORMAL" 1 "OPEN" 2 "SHORT" ;
VAL_ 2566874910 InVlt11 0 "NORMAL" 1 "OPEN" 2 "SHORT" ;
VAL_ 2566874910 InVlt10 0 "NORMAL" 1 "OPEN" 2 "SHORT" ;
VAL_ 2566874910 InVlt9 0 "NORMAL" 1 "OPEN" 2 "SHORT" ;
VAL_ 2566874910 InVlt8 0 "NORMAL" 1 "OPEN" 2 "SHORT" ;
VAL_ 2566874910 InVlt7 0 "NORMAL" 1 "OPEN" 2 "SHORT" ;
VAL_ 2566874910 InVlt6 0 "NORMAL" 1 "OPEN" 2 "SHORT" ;
VAL_ 2566874910 InVlt5 0 "NORMAL" 1 "OPEN" 2 "SHORT" ;
VAL_ 2566874910 InVlt3 14 "ERROR" 15 "NOT_AVAILABLE" ;
VAL_ 2566874910 InVlt2 14 "ERROR" 15 "NOT_AVAILABLE" ;
VAL_ 2566874910 InVlt1 14 "ERROR" 15 "NOT_AVAILABLE" ;
VAL_ 2566875297 HvacOffSel 0 "OUTTAKE_MODE" 1 "INTAKE_MODE" 2 "NOT_AVAILABLE" 3 "RESERVED" ;
VAL_ 2566875297 BlowerDnSig 0 "OUTTAKE_MODE" 1 "INTAKE_MODE" 2 "NOT_AVAILABLE" 3 "RESERVED" ;
VAL_ 2566875297 BlowerUpSig 0 "OUTTAKE_MODE" 1 "INTAKE_MODE" 2 "NOT_AVAILABLE" 3 "RESERVED" ;
VAL_ 2566875297 DefMdSel 0 "OUTTAKE_MODE" 1 "INTAKE_MODE" 2 "NOT_AVAILABLE" 3 "RESERVED" ;
VAL_ 2566875297 BlowMdSelSig 0 "OUTTAKE_MODE" 1 "INTAKE_MODE" 2 "NOT_AVAILABLE" 3 "RESERVED" ;
VAL_ 2566875297 MnAutoMdSel 0 "OUTTAKE_MODE" 1 "INTAKE_MODE" 2 "NOT_AVAILABLE" 3 "RESERVED" ;
VAL_ 2566875297 TmpDnSig 0 "OUTTAKE_MODE" 1 "INTAKE_MODE" 2 "NOT_AVAILABLE" 3 "RESERVED" ;
VAL_ 2566875297 TmpUpSig 0 "OUTTAKE_MODE" 1 "INTAKE_MODE" 2 "NOT_AVAILABLE" 3 "RESERVED" ;
VAL_ 2566875297 OuttakeIntakeMdSel 0 "OUTTAKE_MODE" 1 "INTAKE_MODE" 2 "NOT_AVAILABLE" 3 "RESERVED" ;
VAL_ 2566875297 AcMdSel 0 "DISABLE" 1 "ENABLE" ;
VAL_ 2566875422 OutFdbkCur12 254 "ERROR" 255 "NOT_AVAILABLE" ;
VAL_ 2566875422 OutFdbkCur11 254 "ERROR" 255 "NOT_AVAILABLE" ;
VAL_ 2566875422 OutFdbkCur10 254 "ERROR" 255 "NOT_AVAILABLE" ;
VAL_ 2566875422 OutFdbkCur9 254 "ERROR" 255 "NOT_AVAILABLE" ;
VAL_ 2566875559 OutFdbkCur12 254 "ERROR" 255 "NOT_AVAILABLE" ;
VAL_ 2566875559 OutFdbkCur11 254 "ERROR" 255 "NOT_AVAILABLE" ;
VAL_ 2566875559 OutFdbkCur10 254 "ERROR" 255 "NOT_AVAILABLE" ;
VAL_ 2566875559 OutFdbkCur9 254 "ERROR" 255 "NOT_AVAILABLE" ;
VAL_ 2566876961 LowOutReq8 0 "OFF" 1 "ON" 2 "ERROR" 3 "NOT_AVAILABLE" ;
VAL_ 2566876961 LowOutReq7 0 "OFF" 1 "ON" 2 "ERROR" 3 "NOT_AVAILABLE" ;
VAL_ 2566876961 LowOutReq6 0 "OFF" 1 "ON" 2 "ERROR" 3 "NOT_AVAILABLE" ;
VAL_ 2566876961 LowOutReq5 0 "OFF" 1 "ON" 2 "ERROR" 3 "NOT_AVAILABLE" ;
VAL_ 2566876961 LowOutReq4 0 "OFF" 1 "ON" 2 "ERROR" 3 "NOT_AVAILABLE" ;
VAL_ 2566876961 LowOutReq3 0 "OFF" 1 "ON" 2 "ERROR" 3 "NOT_AVAILABLE" ;
VAL_ 2566876961 LowOutReq2 0 "OFF" 1 "ON" 2 "ERROR" 3 "NOT_AVAILABLE" ;
VAL_ 2566876961 LowOutReq1 0 "OFF" 1 "ON" 2 "ERROR" 3 "NOT_AVAILABLE" ;
VAL_ 2566876961 OutReq15 0 "OFF" 1 "ON" 2 "ERROR" 3 "NOT_AVAILABLE" ;
VAL_ 2566876961 OutReq14 0 "OFF" 1 "ON" 2 "ERROR" 3 "NOT_AVAILABLE" ;
VAL_ 2566876961 OutReq13 0 "OFF" 1 "ON" 2 "ERROR" 3 "NOT_AVAILABLE" ;
VAL_ 2566876961 OutReq12 0 "OFF" 1 "ON" 2 "ERROR" 3 "NOT_AVAILABLE" ;
VAL_ 2566876961 OutReq11 0 "OFF" 1 "ON" 2 "ERROR" 3 "NOT_AVAILABLE" ;
VAL_ 2566876961 OutReq10 0 "OFF" 1 "ON" 2 "ERROR" 3 "NOT_AVAILABLE" ;
VAL_ 2566876961 OutReq9 0 "OFF" 1 "ON" 2 "ERROR" 3 "NOT_AVAILABLE" ;
VAL_ 2566876961 OutReq8 0 "OFF" 1 "ON" 2 "ERROR" 3 "NOT_AVAILABLE" ;
VAL_ 2566876961 OutReq7 0 "OFF" 1 "ON" 2 "ERROR" 3 "NOT_AVAILABLE" ;
VAL_ 2566876961 OutReq6 0 "OFF" 1 "ON" 2 "ERROR" 3 "NOT_AVAILABLE" ;
VAL_ 2566876961 OutReq5 0 "OFF" 1 "ON" 2 "ERROR" 3 "NOT_AVAILABLE" ;
VAL_ 2566876961 OutReq4 0 "OFF" 1 "ON" 2 "ERROR" 3 "NOT_AVAILABLE" ;
VAL_ 2566876961 OutReq3 0 "OFF" 1 "ON" 2 "ERROR" 3 "NOT_AVAILABLE" ;
VAL_ 2566876961 OutReq2 0 "OFF" 1 "ON" 2 "ERROR" 3 "NOT_AVAILABLE" ;
VAL_ 2566876961 OutReq1 0 "OFF" 1 "ON" 2 "ERROR" 3 "NOT_AVAILABLE" ;
